VERSION ""

NS_ :

BS_:

BU_: AMP ETC GW ICM IVI NVS PDC TBOX VSP WCM

BO_ 1924 Diag_Resp_POT: 8 GW
 SG_ Diag_Resp_POT_Data : 0|64@1+ (1,0) [0|0] "N/A"  TBOX

BO_ 1925 Diag_Resp_DSCU: 8 GW
 SG_ Diag_Resp_DSCU_Data : 0|64@1+ (1,0) [0|0] "N/A"  TBOX

BO_ 1934 Diag_Resp_GW: 8 GW
 SG_ Diag_Resp_GW_Data : 0|64@1+ (1,0) [0|0] "N/A"  TBOX

BO_ 1945 Diag_Resp_SWM: 8 GW
 SG_ Diag_Resp_SWM_Data : 0|64@1+ (1,0) [0|0] "N/A"  TBOX

BO_ 1952 Diag_Resp_HCMR: 8 GW
 SG_ Diag_Resp_HCMR_Data : 0|64@1+ (1,0) [0|0] "N/A"  TBOX

BO_ 1953 Diag_Resp_HCML: 8 GW
 SG_ Diag_Resp_HCML_Data : 0|64@1+ (1,0) [0|0] "N/A"  TBOX

BO_ 1954 Diag_Resp_ESC: 8 GW
 SG_ Diag_Resp_ESC_Data : 0|64@1+ (1,0) [0|0] "N/A"  TBOX

BO_ 1956 Diag_Resp_AVM: 8 GW
 SG_ Diag_Resp_AVM_Data : 0|64@1+ (1,0) [0|0] "N/A"  TBOX

BO_ 1958 Diag_Resp_AC: 8 GW
 SG_ Diag_Resp_AC_Data : 0|64@1+ (1,0) [0|0] "N/A"  TBOX

BO_ 1959 Diag_Resp_ASC: 8 GW
 SG_ Diag_Resp_ASC_Data : 0|64@1+ (1,0) [0|0] "N/A"  TBOX

BO_ 1961 Diag_Resp_GSM: 8 GW
 SG_ Diag_Resp_GSM_Data : 0|64@1+ (1,0) [0|0] "N/A"  TBOX

BO_ 1962 Diag_Resp_MPC: 8 GW
 SG_ Diag_Resp_MPC_Data : 0|64@1+ (1,0) [0|0] "N/A"  TBOX

BO_ 1963 Diag_Resp_MRR_R1: 8 GW
 SG_ Diag_Resp_MRR_R1_Data : 0|64@1+ (1,0) [0|0] "N/A"  TBOX

BO_ 1964 Diag_Resp_MRR_R2: 8 GW
 SG_ Diag_Resp_MRR_R2_Data : 0|64@1+ (1,0) [0|0] "N/A"  TBOX

BO_ 1969 Diag_Resp_VCU: 8 GW
 SG_ Diag_Resp_VCU_Data : 0|64@1+ (1,0) [0|0] "N/A"  TBOX

BO_ 1970 Diag_Resp_MCUR0: 8 GW
 SG_ Diag_Resp_MCUR0_Data : 0|64@1+ (1,0) [0|0] "N/A"  TBOX

BO_ 1971 Diag_Resp_MCUF0: 8 GW
 SG_ Diag_Resp_MCUF0_Data : 0|64@1+ (1,0) [0|0] "N/A"  TBOX

BO_ 1972 Diag_Resp_BMS: 8 GW
 SG_ Diag_Resp_BMS_Data : 0|64@1+ (1,0) [0|0] "N/A"  TBOX

BO_ 1973 Diag_Resp_iBooster: 8 GW
 SG_ Diag_Resp_iB_Data : 0|64@1+ (1,0) [0|0] "N/A"  TBOX

BO_ 1975 Diag_Resp_OBCM: 8 GW
 SG_ Diag_Resp_OBCM_Data : 0|64@1+ (1,0) [0|0] "N/A"  TBOX

BO_ 1977 Diag_Resp_MRR: 8 GW
 SG_ Diag_Resp_MRR_Data : 0|64@1+ (1,0) [0|0] "N/A"  TBOX

BO_ 1979 Diag_Resp_BLE: 8 GW
 SG_ Diag_Resp_BLE_Data : 0|64@1+ (1,0) [0|0] "N/A"  TBOX

BO_ 1980 Diag_Resp_GCU: 8 GW
 SG_ Diag_Resp_GCU_Data : 0|64@1+ (1,0) [0|0] "N/A"  TBOX

BO_ 1987 Diag_Resp_APA: 8 GW
 SG_ Diag_Resp_APA_Data : 0|64@1+ (1,0) [0|0] "N/A"  TBOX

BO_ 1988 Diag_Resp_EPS: 8 GW
 SG_ Diag_Resp_EPS_Data : 0|64@1+ (1,0) [0|0] "N/A"  TBOX

BO_ 1994 Diag_Resp_HANDLE_LF: 8 GW
 SG_ Diag_Resp_HANDLE_LF_Data : 0|64@1+ (1,0) [0|0] "N/A"  TBOX

BO_ 1995 Diag_Resp_HANDLE_RF: 8 GW
 SG_ Diag_Resp_HANDLE_RF_Data : 0|64@1+ (1,0) [0|0] "N/A"  TBOX

BO_ 1996 Diag_Resp_HANDLE_LR: 8 GW
 SG_ Diag_Resp_HANDLE_LR_Data : 0|64@1+ (1,0) [0|0] "N/A"  TBOX

BO_ 1997 Diag_Resp_HANDLE_RR: 8 GW
 SG_ Diag_Resp_HANDLE_RR_Data : 0|64@1+ (1,0) [0|0] "N/A"  TBOX

BO_ 2015 Diag_FuncReq: 8 GW
 SG_ Diag_FuncReq_Data : 0|64@1+ (1,0) [0|0] "N/A"  AMP,ETC,ICM,IVI,NVS,PDC,TBOX,VSP,WCM

BO_ 2024 Diag_Resp_ECU: 8 GW
 SG_ Diag_Resp_ECU_Data : 0|64@1+ (1,0) [0|0] "N/A"  TBOX

BO_ 2026 OBD_Resp_BMS: 8 GW
 SG_ OBD_Resp_BMS_Data : 0|64@1+ (1,0) [0|0] "N/A"  TBOX

BO_ 2027 OBD_Resp_GCU: 8 GW
 SG_ OBD_Resp_GCU_Data : 0|64@1+ (1,0) [0|0] "N/A"  TBOX

BO_ 2028 OBD_Resp_OBCM: 8 GW
 SG_ OBD_Resp_OBCM_Data : 0|64@1+ (1,0) [0|0] "N/A"  TBOX

BO_ 2029 OBD_Resp_iBooster: 8 GW
 SG_ OBD_Resp_iBooster_Data : 0|64@1+ (1,0) [0|0] "N/A"  TBOX

BO_ 2030 OBD_Resp_ESC: 8 GW
 SG_ OBD_Resp_ESC_Data : 0|64@1+ (1,0) [0|0] "N/A"  TBOX

BO_ 2031 OBD_Resp_VCU: 8 GW
 SG_ OBD_Resp_VCU_Data : 0|64@1+ (1,0) [0|0] "N/A"  TBOX

BO_ 2041 Diag_Resp_ACU: 8 GW
 SG_ Diag_Resp_ACU_Data : 0|64@1+ (1,0) [0|0] "N/A"  TBOX

BO_ 937 ICM_state: 8 ICM
 SG_ icm_dvrSts : 0|3@1+ (1,0) [0|7] ""  GW,IVI,TBOX
 SG_ icm_dvrPhotoSts : 3|1@1+ (1,0) [0|1] ""  GW,IVI,TBOX
 SG_ icm_dvrSDcardSts : 4|3@1+ (1,0) [0|7] ""  GW,IVI
 SG_ icm_dvrPhotoOutput : 7|1@1+ (1,0) [0|1] ""  GW,IVI,TBOX
 SG_ icm_dvrExitReq : 8|2@1+ (1,0) [0|3] ""  GW,IVI
 SG_ icm_roaSts : 10|2@1+ (1,0) [0|3] ""  GW,IVI,TBOX
 SG_ icm_roaDisplayRes : 14|2@1+ (1,0) [0|3] ""  GW,IVI
 SG_ icm_roaPassengerL : 16|1@1+ (1,0) [0|1] ""  GW,IVI
 SG_ icm_roaPassengerM : 17|1@1+ (1,0) [0|1] ""  GW,IVI
 SG_ icm_roaPassengerR : 18|1@1+ (1,0) [0|1] ""  GW,IVI
 SG_ icm_roaPassengerAge : 19|2@1+ (1,0) [0|3] ""  GW,IVI
 SG_ icm_roaPassengerMood : 21|2@1+ (1,0) [0|3] ""  GW,IVI,TBOX
 SG_ icm_ivipressphto : 23|1@1+ (1,0) [0|1] ""  GW,IVI
 SG_ icm_dmsSts : 24|3@1+ (1,0) [0|7] ""  GW,IVI,TBOX
 SG_ icm_dmsCameraSts : 27|3@1+ (1,0) [0|7] ""  GW,IVI,TBOX
 SG_ icm_dmsWearySet : 30|1@1+ (1,0) [0|1] ""  GW,IVI
 SG_ icm_dmsWearyAssisSet : 31|1@1+ (1,0) [0|1] ""  GW,IVI
 SG_ icm_dmsWearyLeverSts : 32|3@1+ (1,0) [0|7] ""  GW,IVI,TBOX
 SG_ icm_dmsDrvBehaviorMon : 35|3@1+ (1,0) [0|7] ""  GW,IVI,TBOX
 SG_ icm_dmsDistractLeverSts : 38|2@1+ (1,0) [0|3] ""  GW,IVI,TBOX
 SG_ icm_dmsSenSetRsp : 40|1@1+ (1,0) [0|1] ""  GW,IVI,TBOX
 SG_ icm_roaRemind : 41|3@1+ (1,0) [0|7] ""  GW,IVI,TBOX
 SG_ icm_dmsDriverMood : 44|2@1+ (1,0) [0|3] ""  GW,IVI,TBOX
 SG_ icm_dmsDriver : 46|1@1+ (1,0) [0|1] ""  GW,IVI
 SG_ icm_dmsPassenger : 47|1@1+ (1,0) [0|1] ""  GW,IVI
 SG_ icm_dmsFaceID : 48|4@1+ (1,0) [0|15] ""  GW,IVI,TBOX
 SG_ icm_dmsGestureID : 52|4@1+ (1,0) [0|15] ""  GW,IVI,TBOX
 SG_ icm_dmsVideoCallSts : 56|3@1+ (1,0) [0|7] ""  GW,IVI,TBOX
 SG_ icm_roaITLLightReq : 59|2@1+ (1,0) [0|3] ""  GW
 SG_ icm_dvrVideoOutput : 61|1@1+ (1,0) [0|1] ""  GW,IVI,TBOX
 SG_ icm_roaCameraSts : 62|2@1+ (1,0) [0|3] ""  GW,IVI

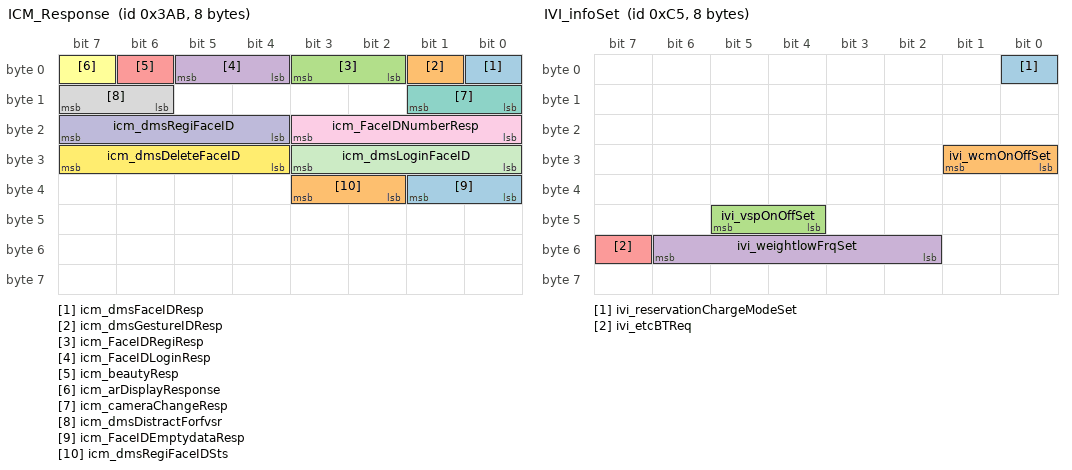
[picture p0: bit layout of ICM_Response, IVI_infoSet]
BO_ 939 ICM_Response: 8 ICM
 SG_ icm_dmsFaceIDResp : 0|1@1+ (1,0) [0|1] ""  IVI
 SG_ icm_dmsGestureIDResp : 1|1@1+ (1,0) [0|1] ""  IVI
 SG_ icm_FaceIDRegiResp : 2|2@1+ (1,0) [0|3] ""  IVI
 SG_ icm_FaceIDLoginResp : 4|2@1+ (1,0) [0|3] ""  IVI
 SG_ icm_beautyResp : 6|1@1+ (1,0) [0|1] ""  IVI
 SG_ icm_arDisplayResponse : 7|1@1+ (1,0) [0|1] ""  IVI
 SG_ icm_cameraChangeResp : 8|2@1+ (1,0) [0|3] ""  IVI
 SG_ icm_dmsDistractForfvsr : 14|2@1+ (1,0) [0|3] ""  GW
 SG_ icm_FaceIDNumberResp : 16|4@1+ (1,0) [0|15] ""  IVI
 SG_ icm_dmsRegiFaceID : 20|4@1+ (1,0) [0|15] ""  IVI
 SG_ icm_dmsLoginFaceID : 24|4@1+ (1,0) [0|15] ""  IVI
 SG_ icm_dmsDeleteFaceID : 28|4@1+ (1,0) [0|15] ""  IVI
 SG_ icm_FaceIDEmptydataResp : 32|2@1+ (1,0) [0|3] ""  IVI
 SG_ icm_dmsRegiFaceIDSts : 34|2@1+ (1,0) [0|3] ""  IVI

BO_ 1545 NM_ICM: 8 ICM
 SG_ ICM_RMR : 8|1@1+ (1,0) [0|1] ""  AMP,ETC,GW,IVI,TBOX
 SG_ ICM_AWB : 12|1@1+ (1,0) [0|1] ""  AMP,ETC,GW,IVI,TBOX

BO_ 1929 Diag_Resp_ICM: 8 ICM
 SG_ Diag_Resp_ICM_Data : 0|64@1+ (1,0) [0|0] "N/A"  GW,TBOX

BO_ 82 IC_engineOFF: 8 IVI
 SG_ ic_engOffTime : 0|10@1+ (1,0) [0|1000] "min"  GW
 SG_ ic_engOffTimeValid : 10|1@1+ (1,0) [0|1] ""  GW

BO_ 117 IVI_control: 8 IVI
 SG_ ivi_hoodUnlockCtrl : 0|2@1+ (1,0) [0|3] ""  GW
 SG_ ivi_RearWindowLockCtrl : 2|2@1+ (1,0) [0|3] ""  GW
 SG_ ivi_gloveBoxUnlockCtrl : 4|2@1+ (1,0) [0|3] ""  GW
 SG_ ivi_centralLockCtrl : 6|2@1+ (1,0) [0|3] ""  GW
 SG_ ivi_fuelPortCapOpenCtrl : 8|2@1+ (1,0) [0|3] ""  GW
 SG_ ivi_lowBeamOnOffCtrl : 10|2@1+ (1,0) [0|3] ""  GW
 SG_ ivi_v2vChrgOnOffSet : 12|2@1+ (1,0) [0|3] ""  GW
 SG_ ivi_posLampOnOffCtrl : 14|2@1+ (1,0) [0|3] ""  GW
 SG_ ivi_obcDschrgOnOffSet : 16|2@1+ (1,0) [0|3] ""  GW
 SG_ ivi_modememory : 18|2@1+ (1,0) [0|3] ""  GW
 SG_ ivi_rearFogLampOnOffCtrl : 20|2@1+ (1,0) [0|3] ""  GW
 SG_ ivi_ventilateSts : 22|2@1+ (1,0) [0|3] ""  GW
 SG_ ivi_chrgPortCapOpenCtrl : 24|2@1+ (1,0) [0|3] ""  GW
 SG_ ivi_sunroofGlassCmd : 26|3@1+ (1,0) [0|7] ""  GW
 SG_ ivi_NormalHvOffReq : 29|1@1+ (1,0) [0|1] ""  GW
 SG_ ivi_antiTheftAlarmFormSet : 30|2@1+ (1,0) [0|3] ""  GW
 SG_ ivi_tailgateCtrl : 32|2@1+ (1,0) [0|3] ""  GW
 SG_ ivi_MirrorSw : 34|2@1+ (1,0) [0|3] ""  GW
 SG_ ivi_rearDefrostCtrl : 36|2@1+ (1,0) [0|3] ""  GW
 SG_ IVI_SOCmodeSet : 38|2@1+ (1,0) [0|3] ""  GW
 SG_ ivi_MaxFuelConsumptionSW : 40|2@1+ (1,0) [0|3] ""  GW
 SG_ ivi_MaxFuelConsumptionModeSW : 42|2@1+ (1,0) [0|3] ""  GW
 SG_ ivi_v2vChrgOptCurntSet : 44|4@1+ (1,0) [0|15] "A"  GW
 SG_ ivi_BatteryCondition : 48|2@1+ (1,0) [0|3] ""  GW
 SG_ ivi_approachingUnlockCtrl : 50|2@1+ (1,0) [0|3] ""  GW
 SG_ ivi_awayLockCtrl : 52|2@1+ (1,0) [0|3] ""  GW
 SG_ ivi_WipperMaintenanceCtrl : 54|1@1+ (1,0) [0|1] ""  GW
 SG_ ivi_gunUnlockCtrlReq : 55|1@1+ (1,0) [0|1] ""  GW
 SG_ ivi_ExhibitionSet : 56|2@1+ (1,0) [0|3] ""  GW
 SG_ ivi_potOnOffSet : 58|2@1+ (1,0) [0|3] ""  GW
 SG_ ivi_frontWindshieldHeatingCtrl : 60|2@1+ (1,0) [0|3] ""  GW
 SG_ ivi_lowVoltPowerCtrl : 62|2@1+ (1,0) [0|3] ""  GW

BO_ 133 IVI_speechControl: 8 IVI
 SG_ ivi_pot_SpeechCtrlOnOffSts : 0|2@1+ (1,0) [0|3] ""  GW
 SG_ ivi_ChargPileAuthSts : 2|1@1+ (1,0) [0|1] ""  TBOX

BO_ 149 IVI_comfortSet: 8 IVI
 SG_ ivi_lockAutoCloseWinCtrl : 0|2@1+ (1,0) [0|3] ""  GW
 SG_ ivi_ambientLightOnOffSet : 2|2@1+ (1,0) [0|3] ""  GW
 SG_ ivi_sunroofRollshadeCtrlSelect : 4|2@1+ (1,0) [0|3] ""  GW
 SG_ ivi_ambientLightColorSet : 8|8@1+ (1,0) [0|255] ""  GW
 SG_ ivi_ambientLightLumiLvSet : 16|4@1+ (1,0) [0|15] ""  GW
 SG_ ivi_screenAutoLiftCtrl : 20|2@1+ (1,0) [0|3] ""  GW
 SG_ ivi_doorTopSW : 22|2@1+ (1,0) [0|3] ""  GW
 SG_ ivi_parkAutoCloseDRLCtrl : 24|2@1+ (1,0) [0|3] ""  GW
 SG_ ivi_followMeHomeSet : 26|3@1+ (1,0) [0|7] ""  GW
 SG_ ivi_WheelAlignmentCtrl : 29|1@1+ (1,0) [0|1] ""  GW
 SG_ ivi_WinLFCtrlRqst : 32|3@1+ (1,0) [0|7] ""  GW
 SG_ ivi_WinRFCtrlRqst : 35|3@1+ (1,0) [0|7] ""  GW
 SG_ ivi_WinLRCtrlRqst : 40|3@1+ (1,0) [0|7] ""  GW
 SG_ ivi_WinRRCtrlRqst : 43|3@1+ (1,0) [0|7] ""  GW
 SG_ IVI_DGSW : 46|2@1+ (1,0) [0|3] ""  GW
 SG_ IVI_DGPercentCtrl : 48|5@1+ (1,0) [0|31] ""  GW
 SG_ IVI_speedautolockonoffSet : 53|2@1+ (1,0) [0|3] ""  GW
 SG_ ivi_adbOnOffSet : 56|2@1+ (1,0) [0|3] ""  GW
 SG_ ivi_hcmHeightSet : 58|3@1+ (1,0) [0|7] ""  GW

BO_ 165 IVI_pwrSet: 8 IVI
 SG_ ivi_4wdModeSet : 2|2@1+ (1,0) [0|3] ""  GW
 SG_ ivi_ChargeCancel : 4|1@1+ (1,0) [0|1] ""  GW,TBOX
 SG_ ivi_RegenModeSet : 5|3@1+ (1,0) [0|7] ""  GW
 SG_ ivi_maxChargeCurrentSet : 8|6@1+ (1,5) [5|67] "A"  GW,TBOX
 SG_ ivi_TowModeSet : 14|2@1+ (1,0) [0|3] ""  GW
 SG_ ivi_maxChrgSocSet : 16|8@1+ (1,0) [0|100] "%"  GW,TBOX
 SG_ ivi_chargeFormSet : 24|2@1+ (1,0) [0|3] ""  GW,TBOX
 SG_ ivi_ChargeEnable : 26|1@1+ (1,0) [0|1] ""  GW,TBOX
 SG_ ivi_highwayModeRequest : 27|2@1+ (1,0) [0|3] ""  GW
 SG_ ivi_chargeSetValid : 30|1@1+ (1,0) [0|1] ""  GW,TBOX
 SG_ ivi_ChargeEndTimeHour : 32|4@1+ (1,0) [0|15] ""  GW,TBOX
 SG_ ivi_ChargeStartTimeHour : 36|4@1+ (1,0) [0|15] ""  GW,TBOX
 SG_ ivi_ChargeEndTimeHalfDay : 40|1@1+ (1,0) [0|1] ""  GW,TBOX
 SG_ ivi_ChargeStartTimeHalfDay : 41|1@1+ (1,0) [0|1] ""  GW,TBOX
 SG_ ivi_ChargeEndTimeMinute : 42|6@1+ (1,0) [0|59] ""  GW,TBOX
 SG_ ivi_ChargeStartTimeMinute : 48|6@1+ (1,0) [0|59] ""  GW,TBOX
 SG_ ivi_ResetCurrentTrip : 54|1@1+ (1,0) [0|1] ""  GW
 SG_ ivi_BCMEBSHvoffset : 56|2@1+ (1,0) [0|3] ""  GW
 SG_ ivi_ChargeEndTimeValid : 58|1@1+ (1,0) [0|1] ""  GW,TBOX
 SG_ ivi_ChargeStartTimeValid : 59|1@1+ (1,0) [0|1] ""  GW,TBOX
 SG_ ivi_driveModeSet : 61|3@1+ (1,0) [0|7] ""  GW

BO_ 197 IVI_infoSet: 8 IVI
 SG_ ivi_reservationChargeModeSet : 0|1@1+ (1,0) [0|1] ""  TBOX
 SG_ ivi_wcmOnOffSet : 24|2@1+ (1,0) [0|3] ""  WCM
 SG_ ivi_vspOnOffSet : 44|2@1+ (1,0) [0|3] ""  VSP
 SG_ ivi_weightlowFrqSet : 50|5@1+ (1,0) [0|31] ""  AMP
 SG_ ivi_etcBTReq : 55|1@1+ (1,0) [0|1] ""  ETC

BO_ 245 IVI_scuSet: 8 IVI
 SG_ ivi_autoEasyEntrySet : 0|2@1+ (1,0) [0|3] ""  GW
 SG_ ivi_drSeatHeatOnOffSet : 2|2@1+ (1,0) [0|3] ""  GW
 SG_ ivi_drSeatVentOnOffSet : 4|2@1+ (1,0) [0|3] ""  GW
 SG_ ivi_drSeatMassOnOffSet : 6|2@1+ (1,0) [0|3] ""  GW
 SG_ ivi_drSeatHeatLevelSet : 8|3@1+ (1,0) [0|7] ""  GW
 SG_ ivi_drSeatVentLevelSet : 11|3@1+ (1,0) [0|7] ""  GW
 SG_ ivi_passSeatHeatOnOffSet : 14|2@1+ (1,0) [0|3] ""  GW
 SG_ ivi_passSeatVentOnOffSet : 16|2@1+ (1,0) [0|3] ""  GW
 SG_ ivi_passSeatHeatLevelSet : 18|3@1+ (1,0) [0|7] ""  GW
 SG_ ivi_passSeatVentLevelSet : 21|3@1+ (1,0) [0|7] ""  GW
 SG_ ivi_passSeatMassOnOffSet : 24|2@1+ (1,0) [0|3] ""  GW
 SG_ ivi_drSeatMassLevelSet : 26|3@1+ (1,0) [0|7] ""  GW
 SG_ ivi_passSeatMassLevelSet : 29|3@1+ (1,0) [0|7] ""  GW
 SG_ ivi_MirrorAutoFoldUnfoldSet : 32|2@1+ (1,0) [0|3] ""  GW
 SG_ ivi_easyEntrySet : 34|2@1+ (1,0) [0|3] ""  GW
 SG_ ivi_dsmSetMemoryReq : 40|3@1+ (1,0) [0|7] ""  GW
 SG_ ivi_dsmGetMemoryReq : 43|3@1+ (1,0) [0|7] ""  GW
 SG_ ivi_rvMirrorAutoTurnDownSet : 46|2@1+ (1,0) [0|3] ""  GW
 SG_ ivi_DrMassgIntenSet : 48|2@1+ (1,0) [0|3] ""  GW
 SG_ ivi_PsgMassgIntenSet : 50|2@1+ (1,0) [0|3] ""  GW
 SG_ ivi_manualEasyOutSw : 52|2@1+ (1,0) [0|3] ""  GW
 SG_ ivi_potPositionStsSet : 54|4@1+ (1,0) [0|15] ""  GW
 SG_ ivi_welcomeOnOffSet : 58|4@1+ (1,0) [0|15] ""  GW
 SG_ ivi_welcomeSetEnable : 62|2@1+ (1,0) [0|3] ""  GW

BO_ 261 IVI_icmSet: 8 IVI
 SG_ ivi_dvrDisplayReq : 0|2@1+ (1,0) [0|3] ""  ICM
 SG_ ivi_dvrCoTouchMotion : 2|2@1+ (1,0) [0|3] ""  ICM
 SG_ ivi_dvrXCoordinate : 4|12@1+ (1,0) [0|1280] ""  ICM
 SG_ ivi_dvrYCoordinate : 16|10@1+ (1,0) [0|720] ""  ICM
 SG_ ivi_roaDisplayReq : 26|2@1+ (1,0) [0|3] ""  ICM
 SG_ ivi_ICMpressphtoresp : 28|2@1+ (1,0) [0|3] ""  ICM
 SG_ ivi_dmsWearyAssisSet : 30|2@1+ (1,0) [0|3] ""  ICM
 SG_ ivi_dmsCameraCtl : 32|2@1+ (1,0) [0|3] ""  ICM
 SG_ ivi_dmsWearySet : 34|2@1+ (1,0) [0|3] ""  ICM
 SG_ ivi_dmsSenSet : 36|2@1+ (1,0) [0|3] ""  ICM
 SG_ ivi_ICMBeautySet : 38|2@1+ (1,0) [0|3] ""  ICM
 SG_ ivi_cameraChange : 40|3@1+ (1,0) [0|7] ""  ICM
 SG_ ivi_videoCallSts : 44|3@1+ (1,0) [0|7] ""  ICM
 SG_ ivi_nvsDisplay : 51|2@1+ (1,0) [0|3] ""  NVS
 SG_ ivi_nvsOCRPress : 53|2@1+ (1,0) [0|3] ""  NVS
 SG_ ivi_ArdisplayReq : 55|2@1+ (1,0) [0|3] ""  ICM
 SG_ ivi_dvrPhotoReceive : 57|1@1+ (1,0) [0|1] ""  ICM
 SG_ ivi_dvrVideoReceive : 58|1@1+ (1,0) [0|1] ""  ICM
 SG_ ivi_roaCameraCtl : 59|1@1+ (1,0) [0|1] ""  ICM
 SG_ ivi_tspUploadSts : 60|2@1+ (1,0) [0|3] ""  ICM,TBOX

BO_ 270 IVI_AVMSet: 8 IVI
 SG_ ivi_AVMTrigByTurnningSts : 0|1@1+ (1,0) [0|1] ""  GW
 SG_ ivi_AVMViewModeSw : 1|1@1+ (1,0) [0|1] ""  GW
 SG_ ivi_modeSw : 2|1@1+ (1,0) [0|1] ""  GW
 SG_ ivi_viewSw_Reserved : 3|2@1+ (1,0) [0|1] ""  GW
 SG_ ivi_screenCoordX : 5|11@1+ (1,0) [0|2047] ""  GW
 SG_ ivi_screenCoordY : 16|11@1+ (1,0) [0|2047] ""  GW
 SG_ ivi_avm_monVideoReceive : 28|1@1+ (1,0) [0|1] ""  GW
 SG_ ivi_MODSw : 29|1@1+ (1,0) [0|1] ""  GW
 SG_ ivi_AVMTrajectorySW : 30|1@1+ (1,0) [0|1] ""  GW
 SG_ ivi_AVMAutoswitchingSW : 31|1@1+ (1,0) [0|1] ""  GW
 SG_ ivi_AVM_transparentSW : 32|1@1+ (1,0) [0|1] ""  GW
 SG_ ivi_View_select : 33|5@1+ (1,0) [0|31] ""  GW
 SG_ IVI_Voice_AVMOnOffReq : 38|2@1+ (1,0) [0|3] ""  GW
 SG_ ivi_touchScreenCtrl : 40|4@1+ (1,0) [0|15] ""  GW
 SG_ ivi_naviSts : 44|2@1+ (1,0) [0|3] ""  GW
 SG_ IVI_Voice_APAOnOffReq : 46|2@1+ (1,0) [0|3] ""  GW
 SG_ IVI_Voice_CarbodyTransparentReq : 48|2@1+ (1,0) [0|3] ""  GW

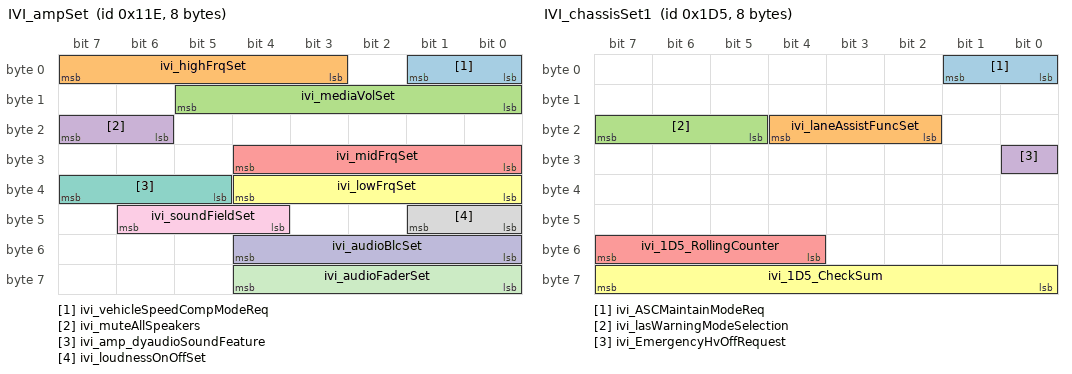
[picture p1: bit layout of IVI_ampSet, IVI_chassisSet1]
BO_ 286 IVI_ampSet: 8 IVI
 SG_ ivi_vehicleSpeedCompModeReq : 0|2@1+ (1,0) [0|3] ""  AMP
 SG_ ivi_highFrqSet : 3|5@1+ (1,0) [0|31] ""  AMP
 SG_ ivi_mediaVolSet : 8|6@1+ (1,0) [0|63] ""  AMP
 SG_ ivi_muteAllSpeakers : 22|2@1+ (1,0) [0|3] ""  AMP
 SG_ ivi_midFrqSet : 24|5@1+ (1,0) [0|31] ""  AMP
 SG_ ivi_lowFrqSet : 32|5@1+ (1,0) [0|31] ""  AMP
 SG_ ivi_amp_dyaudioSoundFeature : 37|3@1+ (1,0) [0|7] ""  AMP
 SG_ ivi_loudnessOnOffSet : 40|2@1+ (1,0) [0|3] ""  AMP
 SG_ ivi_soundFieldSet : 44|3@1+ (1,0) [0|3] ""  AMP
 SG_ ivi_audioBlcSet : 48|5@1+ (1,0) [0|31] ""  AMP
 SG_ ivi_audioFaderSet : 56|5@1+ (1,0) [0|31] ""  AMP

BO_ 446 IVI_chassisSet: 8 IVI
 SG_ ivi_epsModeSet : 0|2@1+ (1,0) [0|3] ""  GW
 SG_ ivi_escOffSw : 2|2@1+ (1,0) [0|3] ""  GW
 SG_ ivi_hdcOnOffSet : 4|2@1+ (1,0) [0|3] ""  GW
 SG_ ivi_aebOnOffSet : 6|2@1+ (1,0) [0|3] ""  GW
 SG_ ivi_iBModeSet : 8|2@1+ (1,0) [0|3] ""  GW
 SG_ ivi_lksSensitivitySet : 10|2@1+ (1,0) [0|3] ""  GW
 SG_ ivi_lcaBsdOnOffSet : 12|2@1+ (1,0) [0|3] ""  GW
 SG_ ivi_rctaOnOffSet : 14|2@1+ (1,0) [0|3] ""  GW
 SG_ ivi_dowOnOffSet : 16|2@1+ (1,0) [0|3] ""  GW
 SG_ ivi_startRevSOCSet : 18|6@1+ (1,19) [19|80] "%"  GW
 SG_ ivi_speedLimitWarningMode : 24|2@1+ (1,0) [0|3] ""  GW
 SG_ ivi_ISAOnOffSet : 26|2@1+ (1,0) [0|3] ""  GW
 SG_ ivi_currentRoadType : 28|4@1+ (1,0) [0|15] ""  GW
 SG_ ivi_countryCodeSet : 32|8@1+ (1,0) [0|255] ""  GW
 SG_ ivi_FrtVehStrReminderSw : 40|2@1+ (1,0) [0|3] ""  GW
 SG_ ivi_speedLimitUnitSet : 48|2@1+ (1,0) [0|3] ""  GW
 SG_ ivi_speedLimitStsSet : 50|2@1+ (1,0) [0|3] ""  GW
 SG_ ivi_propModeSet : 52|2@1+ (1,0) [0|3] ""  GW
 SG_ ivi_pcwOnOffSet : 54|2@1+ (1,0) [0|3] ""  GW
 SG_ ivi_torqueDistModeSet : 56|2@1+ (1,0) [0|3] ""  GW
 SG_ ivi_rcwOnOffSet : 58|2@1+ (1,0) [0|3] ""  GW
 SG_ ivi_trailerModeOnOffSet : 60|2@1+ (1,0) [0|3] ""  GW
 SG_ ivi_esc_epbButtonRelease : 62|1@1+ (1,0) [0|1] ""  GW

BO_ 469 IVI_chassisSet1: 8 IVI
 SG_ ivi_ASCMaintainModeReq : 0|2@1+ (1,0) [0|3] ""  GW
 SG_ ivi_laneAssistFuncSet : 18|3@1+ (1,0) [0|7] ""  GW
 SG_ ivi_lasWarningModeSelection : 21|3@1+ (1,0) [0|7] ""  GW
 SG_ ivi_EmergencyHvOffRequest : 24|1@1+ (1,0) [0|1] ""  GW
 SG_ ivi_1D5_RollingCounter : 52|4@1+ (1,0) [0|15] ""  GW
 SG_ ivi_1D5_CheckSum : 56|8@1+ (1,0) [0|255] ""  GW

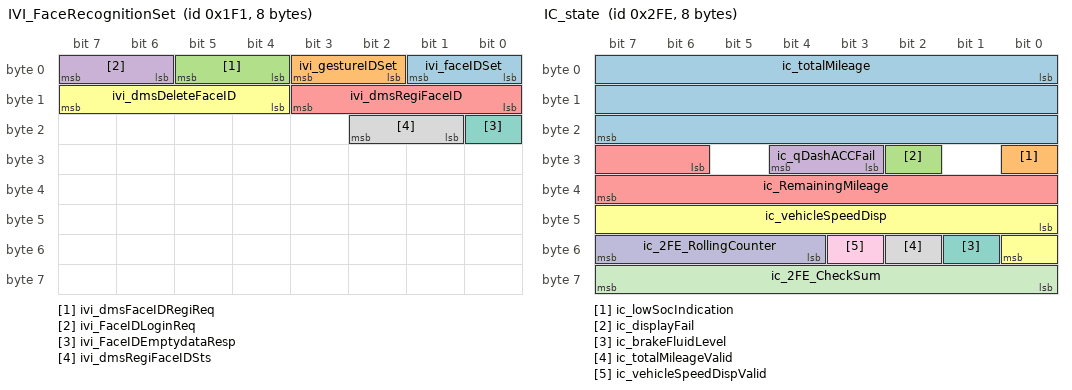
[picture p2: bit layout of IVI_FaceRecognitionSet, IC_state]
BO_ 497 IVI_FaceRecognitionSet: 8 IVI
 SG_ ivi_faceIDSet : 0|2@1+ (1,0) [0|3] ""  ICM
 SG_ ivi_gestureIDSet : 2|2@1+ (1,0) [0|3] ""  ICM
 SG_ ivi_dmsFaceIDRegiReq : 4|2@1+ (1,0) [0|3] ""  ICM
 SG_ ivi_FaceIDLoginReq : 6|2@1+ (1,0) [0|3] ""  ICM
 SG_ ivi_dmsRegiFaceID : 8|4@1+ (1,0) [0|15] ""  ICM
 SG_ ivi_dmsDeleteFaceID : 12|4@1+ (1,0) [0|15] ""  ICM
 SG_ ivi_FaceIDEmptydataResp : 16|1@1+ (1,0) [0|1] ""  ICM
 SG_ ivi_dmsRegiFaceIDSts : 17|2@1+ (1,0) [0|3] ""  ICM

BO_ 766 IC_state: 8 IVI
 SG_ ic_totalMileage : 0|24@1+ (0.1,0) [0|1677721.4] "km"  GW,TBOX
 SG_ ic_lowSocIndication : 24|1@1+ (1,0) [0|1] ""  GW
 SG_ ic_displayFail : 26|1@1+ (1,0) [0|1] ""  GW
 SG_ ic_qDashACCFail : 27|2@1+ (1,0) [0|3] ""  GW
 SG_ ic_RemainingMileage : 30|10@1+ (1,0) [0|1022] "km"  GW,TBOX
 SG_ ic_vehicleSpeedDisp : 40|9@1+ (1,0) [0|280] "KPH"  GW,ICM
 SG_ ic_brakeFluidLevel : 49|1@1+ (1,0) [0|1] ""  GW
 SG_ ic_totalMileageValid : 50|1@1+ (1,0) [0|1] ""  GW
 SG_ ic_vehicleSpeedDispValid : 51|1@1+ (1,0) [0|1] ""  GW
 SG_ ic_2FE_RollingCounter : 52|4@1+ (1,0) [0|15] ""  GW
 SG_ ic_2FE_CheckSum : 56|8@1+ (1,0) [0|255] ""  GW

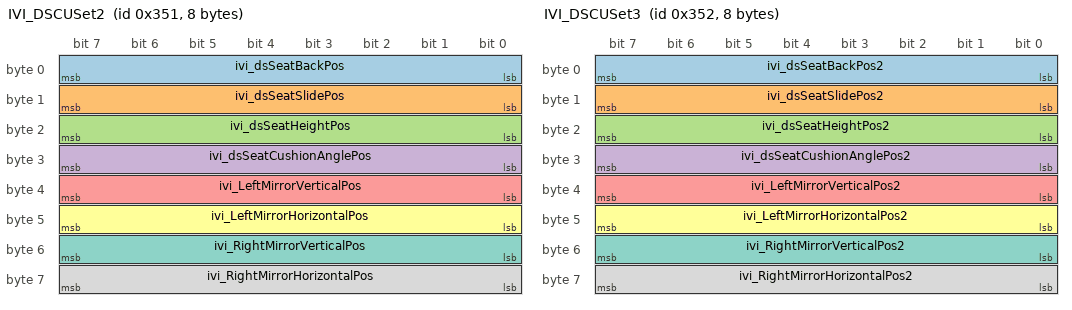
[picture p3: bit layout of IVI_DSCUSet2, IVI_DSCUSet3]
BO_ 849 IVI_DSCUSet2: 8 IVI
 SG_ ivi_dsSeatBackPos : 0|8@1+ (1,0) [0|100] "%"  GW
 SG_ ivi_dsSeatSlidePos : 8|8@1+ (1,0) [0|100] "%"  GW
 SG_ ivi_dsSeatHeightPos : 16|8@1+ (1,0) [0|100] "%"  GW
 SG_ ivi_dsSeatCushionAnglePos : 24|8@1+ (1,0) [0|100] "%"  GW
 SG_ ivi_LeftMirrorVerticalPos : 32|8@1+ (1,0) [0|100] "%"  GW
 SG_ ivi_LeftMirrorHorizontalPos : 40|8@1+ (1,0) [0|100] "%"  GW
 SG_ ivi_RightMirrorVerticalPos : 48|8@1+ (1,0) [0|100] "%"  GW
 SG_ ivi_RightMirrorHorizontalPos : 56|8@1+ (1,0) [0|100] "%"  GW

BO_ 850 IVI_DSCUSet3: 8 IVI
 SG_ ivi_dsSeatBackPos2 : 0|8@1+ (1,0) [0|100] "%"  GW
 SG_ ivi_dsSeatSlidePos2 : 8|8@1+ (1,0) [0|100] "%"  GW
 SG_ ivi_dsSeatHeightPos2 : 16|8@1+ (1,0) [0|100] "%"  GW
 SG_ ivi_dsSeatCushionAnglePos2 : 24|8@1+ (1,0) [0|100] "%"  GW
 SG_ ivi_LeftMirrorVerticalPos2 : 32|8@1+ (1,0) [0|100] "%"  GW
 SG_ ivi_LeftMirrorHorizontalPos2 : 40|8@1+ (1,0) [0|100] "%"  GW
 SG_ ivi_RightMirrorVerticalPos2 : 48|8@1+ (1,0) [0|100] "%"  GW
 SG_ ivi_RightMirrorHorizontalPos2 : 56|8@1+ (1,0) [0|100] "%"  GW

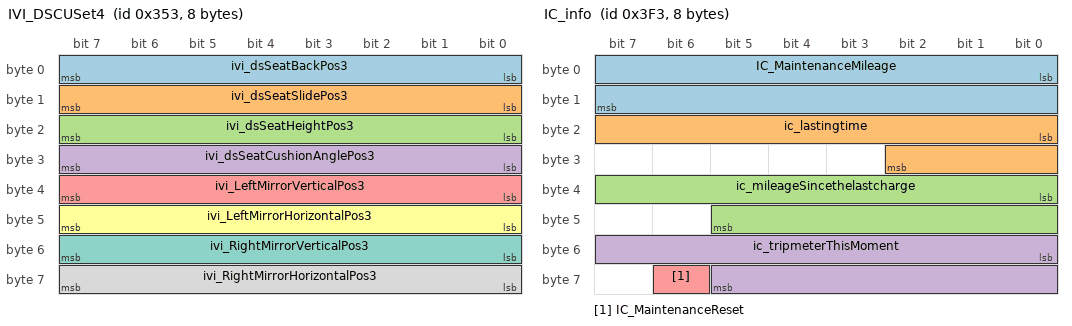
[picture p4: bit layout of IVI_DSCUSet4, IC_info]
BO_ 851 IVI_DSCUSet4: 8 IVI
 SG_ ivi_dsSeatBackPos3 : 0|8@1+ (1,0) [0|100] "%"  GW
 SG_ ivi_dsSeatSlidePos3 : 8|8@1+ (1,0) [0|100] "%"  GW
 SG_ ivi_dsSeatHeightPos3 : 16|8@1+ (1,0) [0|100] "%"  GW
 SG_ ivi_dsSeatCushionAnglePos3 : 24|8@1+ (1,0) [0|100] "%"  GW
 SG_ ivi_LeftMirrorVerticalPos3 : 32|8@1+ (1,0) [0|100] "%"  GW
 SG_ ivi_LeftMirrorHorizontalPos3 : 40|8@1+ (1,0) [0|100] "%"  GW
 SG_ ivi_RightMirrorVerticalPos3 : 48|8@1+ (1,0) [0|100] "%"  GW
 SG_ ivi_RightMirrorHorizontalPos3 : 56|8@1+ (1,0) [0|100] "%"  GW

BO_ 949 IVI_set: 8 IVI
 SG_ ivi_hvacOnOffReq : 0|1@1+ (1,0) [0|1] ""  GW
 SG_ ivi_hvacAutoModeReq : 8|1@1+ (1,0) [0|1] ""  GW
 SG_ ivi_hvacRecircModeReq : 9|1@1+ (1,0) [0|1] ""  GW
 SG_ ivi_hvacModeReq : 16|3@1+ (1,0) [0|7] ""  GW
 SG_ ivi_driverTempCSet : 19|5@1+ (0.5,15.5) [15.5|30.5] "degreeC"  GW
 SG_ ivi_passengerTempCSet : 27|5@1+ (0.5,15.5) [15.5|30.5] "degreeC"  GW
 SG_ ivi_hvacDualMode : 32|1@1+ (1,0) [0|1] ""  GW
 SG_ ivi_acReq : 34|1@1+ (1,0) [0|1] ""  GW
 SG_ ivi_pm25StsReq : 35|1@1+ (1,0) [0|1] ""  GW
 SG_ ivi_acWorkModeSet : 36|2@1+ (1,0) [0|3] ""  GW
 SG_ ivi_acDiagReq : 39|1@1+ (1,0) [0|1] ""  GW
 SG_ IVI_Backlightadjust : 40|4@1+ (1,0) [0|10] ""  GW
 SG_ IVI_FreshAirModeSet : 44|1@1+ (1,0) [0|1] ""  GW
 SG_ IVI_VentilationCoolSet : 45|1@1+ (1,0) [0|1] ""  GW
 SG_ ivi_frontDefrostCtrl : 46|1@1+ (1,0) [0|1] ""  GW
 SG_ ivi_languageSet : 48|2@1+ (1,0) [0|3] ""  GW
 SG_ ivi_unitSet : 50|2@1+ (1,0) [0|3] ""  GW
 SG_ ivi_hvacBlowLvReq : 52|4@1+ (1,0) [0|15] ""  GW
 SG_ IVI_Sunroof_HorizontalControl : 56|7@1+ (1,0) [0|100] "%"  GW

BO_ 1011 IC_info: 8 IVI
 SG_ IC_MaintenanceMileage : 0|16@1+ (1,0) [0|50000] "km"  GW,TBOX
 SG_ ic_lastingtime : 16|11@1+ (1,0) [0|1440] "min"  GW,ICM,TBOX
 SG_ ic_mileageSincethelastcharge : 32|14@1+ (0.1,0) [0|999.9] "km"  GW
 SG_ ic_tripmeterThisMoment : 48|14@1+ (0.1,0) [0|999.9] "km"  GW,TBOX
 SG_ IC_MaintenanceReset : 62|1@1+ (1,0) [0|1] ""  GW,TBOX

BO_ 1248 IC_info1: 8 IVI
 SG_ ic_totalMileageRev : 0|24@1+ (0.1,0) [0|1677721.4] "km"  TBOX

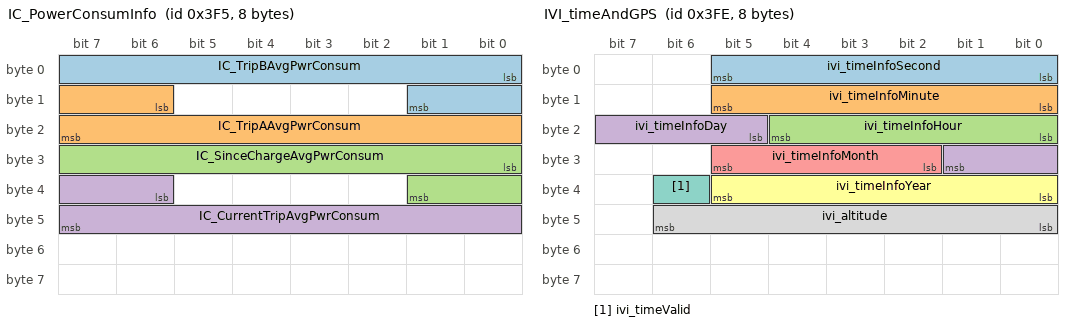
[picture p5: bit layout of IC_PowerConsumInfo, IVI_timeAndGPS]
BO_ 1013 IC_PowerConsumInfo: 8 IVI
 SG_ IC_TripBAvgPwrConsum : 0|10@1+ (0.1,-19.9) [-19.9|40] "kWh/100km"  TBOX
 SG_ IC_TripAAvgPwrConsum : 14|10@1+ (0.1,-19.9) [-19.9|40] "kWh/100km"  TBOX
 SG_ IC_SinceChargeAvgPwrConsum : 24|10@1+ (0.1,-19.9) [-19.9|40] "kWh/100km"  TBOX
 SG_ IC_CurrentTripAvgPwrConsum : 38|10@1+ (0.1,-19.9) [-19.9|40] "kWh/100km"  TBOX

BO_ 1022 IVI_timeAndGPS: 8 IVI
 SG_ ivi_timeInfoSecond : 0|6@1+ (1,0) [0|59] ""  GW,ICM,NVS
 SG_ ivi_timeInfoMinute : 8|6@1+ (1,0) [0|59] ""  GW,ICM,NVS
 SG_ ivi_timeInfoHour : 16|5@1+ (1,0) [0|23] ""  GW,ICM,NVS
 SG_ ivi_timeInfoDay : 21|5@1+ (1,0) [1|31] ""  GW,ICM,NVS
 SG_ ivi_timeInfoMonth : 26|4@1+ (1,0) [1|12] ""  GW,ICM,NVS
 SG_ ivi_timeInfoYear : 32|6@1+ (1,2000) [2000|2059] ""  GW,ICM,NVS
 SG_ ivi_timeValid : 38|1@1+ (1,0) [0|1] ""  GW,ICM,NVS
 SG_ ivi_altitude : 40|7@1+ (100,-100) [-100|8500] "degree"  GW

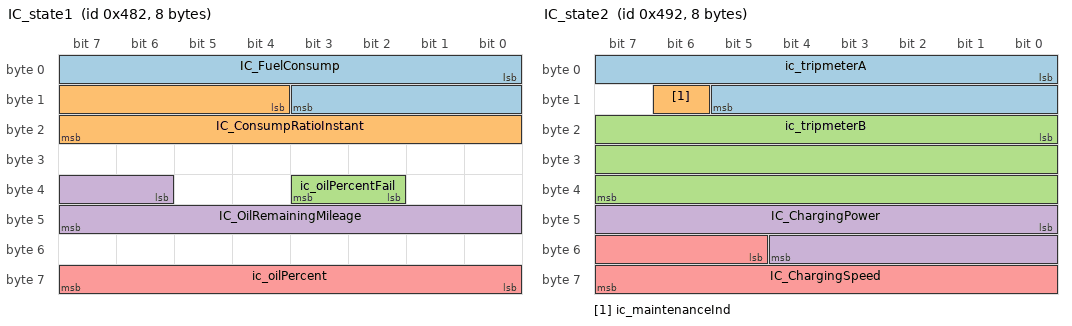
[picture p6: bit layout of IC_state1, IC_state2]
BO_ 1154 IC_state1: 8 IVI
 SG_ IC_FuelConsump : 0|12@1+ (0.1,0) [0|99.9] "L/100Km"  TBOX
 SG_ IC_ConsumpRatioInstant : 12|12@1+ (0.1,-40) [-40|99.9] "kWh/100km"  TBOX
 SG_ ic_oilPercentFail : 34|2@1+ (1,0) [0|3] ""  GW,TBOX
 SG_ IC_OilRemainingMileage : 38|10@1+ (1,0) [0|999] "km"  TBOX
 SG_ ic_oilPercent : 56|8@1+ (1,0) [0|100] "%"  GW,TBOX

BO_ 1170 IC_state2: 8 IVI
 SG_ ic_tripmeterA : 0|14@1+ (0.1,0) [0|1000] "km"  GW
 SG_ ic_maintenanceInd : 14|1@1+ (1,0) [0|1] ""  GW
 SG_ ic_tripmeterB : 16|24@1+ (0.1,0) [0|99999.9] "km"  GW
 SG_ IC_ChargingPower : 40|13@1+ (0.1,0) [0|500] "kW"  GW,TBOX
 SG_ IC_ChargingSpeed : 53|11@1+ (1,0) [0|2000] "km/h"  GW,TBOX

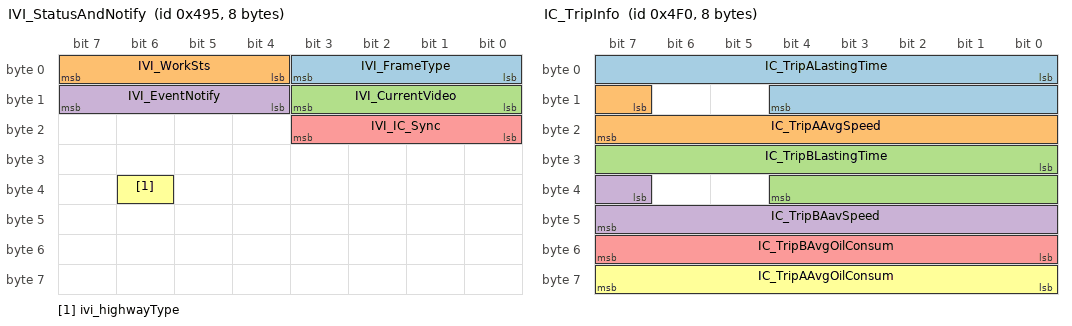
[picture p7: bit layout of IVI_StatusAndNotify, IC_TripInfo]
BO_ 1173 IVI_StatusAndNotify: 8 IVI
 SG_ IVI_FrameType : 0|4@1+ (1,0) [0|15] ""  GW
 SG_ IVI_WorkSts : 4|4@1+ (1,0) [0|15] ""  GW
 SG_ IVI_CurrentVideo : 8|4@1+ (1,0) [0|15] ""  GW
 SG_ IVI_EventNotify : 12|4@1+ (1,0) [0|15] ""  GW
 SG_ IVI_IC_Sync : 16|4@1+ (1,0) [0|15] ""  GW
 SG_ ivi_highwayType : 38|1@1+ (1,0) [0|1] ""  GW

BO_ 1264 IC_TripInfo: 8 IVI
 SG_ IC_TripALastingTime : 0|13@1+ (1,0) [0|5999] "min" Vector__XXX
 SG_ IC_TripAAvgSpeed : 15|9@1+ (1,0) [0|240] "km/h" Vector__XXX
 SG_ IC_TripBLastingTime : 24|13@1+ (1,0) [0|5999] "min" Vector__XXX
 SG_ IC_TripBAavSpeed : 39|9@1+ (1,0) [0|240] "km/h" Vector__XXX
 SG_ IC_TripBAvgOilConsum : 48|8@1+ (0.1,0) [0|19.9] "L/100Km" Vector__XXX
 SG_ IC_TripAAvgOilConsum : 56|8@1+ (0.1,0) [0|19.9] "L/100Km" Vector__XXX

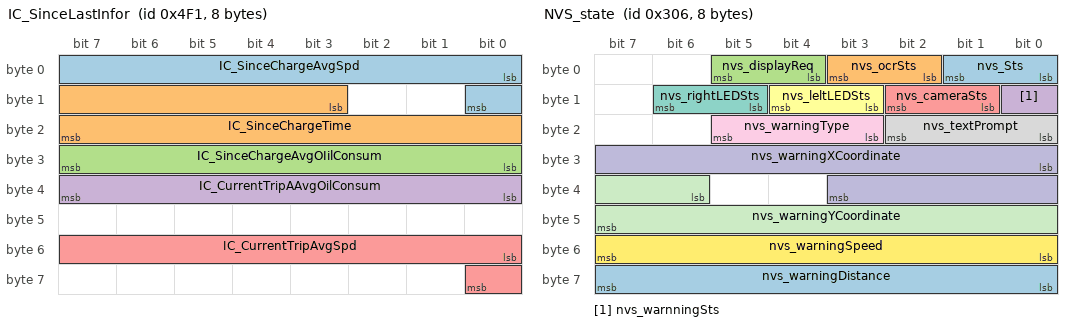
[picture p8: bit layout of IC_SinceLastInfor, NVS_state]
BO_ 1265 IC_SinceLastInfor: 8 IVI
 SG_ IC_SinceChargeAvgSpd : 0|9@1+ (1,0) [0|240] "km/h" Vector__XXX
 SG_ IC_SinceChargeTime : 11|13@1+ (1,0) [0|5999] "min" Vector__XXX
 SG_ IC_SinceChargeAvgOIilConsum : 24|8@1+ (0.1,0) [0|19.9] "L/100Km" Vector__XXX
 SG_ IC_CurrentTripAAvgOilConsum : 32|8@1+ (0.1,0) [0|19.9] "L/100Km"  TBOX
 SG_ IC_CurrentTripAvgSpd : 48|9@1+ (1,0) [0|240] "km/h"  TBOX

BO_ 1573 NM_IVI: 8 IVI
 SG_ IVI_RMR : 8|1@1+ (1,0) [0|1] ""  AMP,ETC,GW,ICM,TBOX
 SG_ IVI_AWB : 12|1@1+ (1,0) [0|1] ""  AMP,ETC,GW,ICM,TBOX

BO_ 1957 Diag_Resp_IVI: 8 IVI
 SG_ Diag_Resp_IVI_Data : 0|64@1+ (1,0) [0|0] "N/A"  GW,WCM

BO_ 774 NVS_state: 8 NVS
 SG_ nvs_Sts : 0|2@1+ (1,0) [0|3] ""  IVI
 SG_ nvs_ocrSts : 2|2@1+ (1,0) [0|3] ""  IVI
 SG_ nvs_displayReq : 4|2@1+ (1,0) [0|3] ""  IVI
 SG_ nvs_warnningSts : 8|1@1+ (1,0) [0|1] ""  IVI
 SG_ nvs_cameraSts : 9|2@1+ (1,0) [0|3] ""  IVI
 SG_ nvs_leltLEDSts : 11|2@1+ (1,0) [0|3] ""  IVI
 SG_ nvs_rightLEDSts : 13|2@1+ (1,0) [0|3] ""  IVI
 SG_ nvs_textPrompt : 16|3@1+ (1,0) [0|7] ""  IVI
 SG_ nvs_warningType : 19|3@1+ (1,0) [0|7] ""  IVI
 SG_ nvs_warningXCoordinate : 24|12@1+ (1,0) [0|1920] ""  IVI,TBOX
 SG_ nvs_warningYCoordinate : 38|10@1+ (1,0) [0|720] ""  IVI,TBOX
 SG_ nvs_warningSpeed : 48|8@1+ (1,0) [0|250] "km/h"  IVI
 SG_ nvs_warningDistance : 56|8@1+ (1,0) [0|250] "m"  IVI

BO_ 1978 Diag_Resp_NVS: 8 NVS
 SG_ Diag_Resp_NVS_Data : 0|64@1+ (1,0) [0|0] "N/A"  GW,TBOX

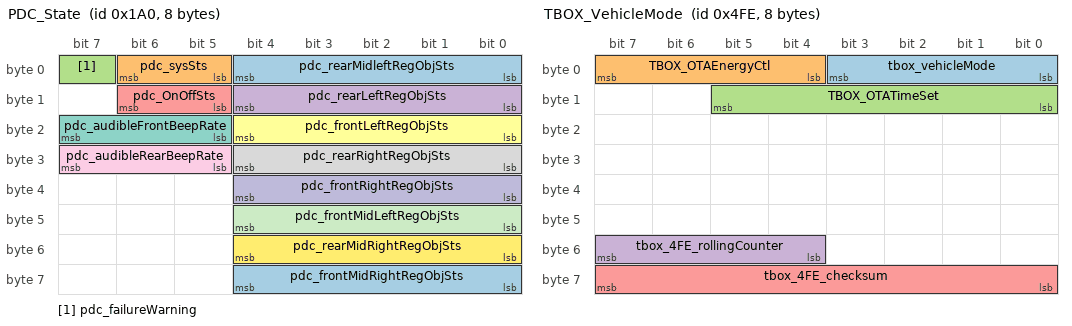
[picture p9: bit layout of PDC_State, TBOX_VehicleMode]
BO_ 416 PDC_State: 8 PDC
 SG_ pdc_rearMidleftRegObjSts : 0|5@1+ (1,0) [0|31] ""  GW,IVI
 SG_ pdc_sysSts : 5|2@1+ (1,0) [0|3] ""  GW,IVI
 SG_ pdc_failureWarning : 7|1@1+ (1,0) [0|1] ""  GW,IVI
 SG_ pdc_rearLeftRegObjSts : 8|5@1+ (1,0) [0|31] ""  GW,IVI
 SG_ pdc_OnOffSts : 13|2@1+ (1,0) [0|3] ""  GW,IVI
 SG_ pdc_frontLeftRegObjSts : 16|5@1+ (1,0) [0|31] ""  GW,IVI
 SG_ pdc_audibleFrontBeepRate : 21|3@1+ (1,0) [0|7] ""  GW,IVI
 SG_ pdc_rearRightRegObjSts : 24|5@1+ (1,0) [0|31] ""  GW,IVI
 SG_ pdc_audibleRearBeepRate : 29|3@1+ (1,0) [0|7] ""  GW,IVI
 SG_ pdc_frontRightRegObjSts : 32|5@1+ (1,0) [0|31] ""  GW,IVI
 SG_ pdc_frontMidLeftRegObjSts : 40|5@1+ (1,0) [0|31] ""  GW,IVI
 SG_ pdc_rearMidRightRegObjSts : 48|5@1+ (1,0) [0|31] ""  GW,IVI
 SG_ pdc_frontMidRightRegObjSts : 56|5@1+ (1,0) [0|31] ""  GW,IVI

BO_ 1943 Diag_Resp_PDC: 8 PDC
 SG_ Diag_Resp_PDC_Data : 0|64@1+ (1,0) [0|0] "N/A"  GW,TBOX

BO_ 72 TBOX_BCM_response: 8 TBOX
 SG_ Tbox_AuthResponeStatus : 8|8@1+ (1,0) [0|255] ""  GW
 SG_ Tbox_AuthKeyData : 16|48@1+ (1,0) [0|65535] ""  GW

BO_ 88 TBOX_remoteCmd: 8 TBOX
 SG_ tbox_remoteLockCtrlReq : 3|2@1+ (1,0) [0|3] ""  GW
 SG_ tbox_remoteCarSearchReq : 6|2@1+ (1,0) [0|3] ""  GW
 SG_ tbox_remoteTailgateCtrlReq : 8|2@1+ (1,0) [0|3] ""  GW
 SG_ tbox_sunroofGlassCmd : 10|3@1+ (1,0) [0|7] ""  GW
 SG_ tbox_remoteForbiddenOn : 13|2@1+ (1,0) [0|3] ""  GW
 SG_ tbox_HornReq : 15|2@1+ (1,0) [0|3] ""  GW
 SG_ tbox_remotePowerCtrlReq : 17|2@1+ (1,0) [0|3] ""  GW
 SG_ tbox_remoteDrSeatHeatReq : 19|3@1+ (1,0) [0|7] ""  GW
 SG_ tbox_remotePassSeatHeatReq : 22|3@1+ (1,0) [0|7] ""  GW
 SG_ tbox_HazardLightReq : 25|2@1+ (1,0) [0|3] ""  GW
 SG_ tbox_remoteACOnOffReq : 27|2@1+ (1,0) [0|3] ""  GW
 SG_ tbox_remoteInfoCollectionReq : 29|2@1+ (1,0) [0|3] ""  GW
 SG_ tbox_oneTouchCoolSet : 32|2@1+ (1,0) [0|3] ""  GW
 SG_ tbox_oneTouchHeatSet : 34|2@1+ (1,0) [0|3] ""  GW
 SG_ tbox_remoteWinLFCtrlRqst : 48|2@1+ (1,0) [0|3] ""  GW
 SG_ tbox_remoteWinRFCtrlRqst : 50|2@1+ (1,0) [0|3] ""  GW
 SG_ tbox_remoteWinLRCtrlRqst : 52|2@1+ (1,0) [0|3] ""  GW
 SG_ tbox_remoteWinRRCtrlRqst : 54|2@1+ (1,0) [0|3] ""  GW
 SG_ tbox_lowBeamOnOffCtrl : 56|2@1+ (1,0) [0|3] ""  GW

BO_ 126 TBOX_chargeSet: 8 TBOX
 SG_ tbox_reservationChargeMode : 0|1@1+ (1,0) [0|1] ""  GW,IVI
 SG_ tbox_SysErSt : 1|2@1+ (1,0) [0|3] ""  GW,IVI
 SG_ tbox_chargeSetValid_Reserved : 7|1@1+ (1,0) [0|1] ""  GW
 SG_ tbox_MaxChargeCurrentSet : 8|6@1+ (1,5) [5|67] "A"  GW,IVI
 SG_ tbox_ChargeFormSet : 14|2@1+ (1,0) [0|3] ""  GW,IVI
 SG_ tbox_ChargeEndTimeHalfDay : 16|1@1+ (1,0) [0|1] ""  GW,IVI
 SG_ tbox_ChargeEndTimeHour : 17|4@1+ (1,0) [0|15] ""  GW,IVI
 SG_ tbox_remoteVehicleForbiddenStart : 21|2@1+ (1,0) [0|3] ""  GW
 SG_ tbox_ChargeEndTimeMinute : 24|6@1+ (1,0) [0|59] ""  GW,IVI
 SG_ tbox_ChargeCancel : 30|1@1+ (1,0) [0|1] ""  GW
 SG_ tbox_ChargeEnable : 31|1@1+ (1,0) [0|1] ""  GW
 SG_ tbox_ChargeStartTimeHalfDay : 32|1@1+ (1,0) [0|1] ""  GW,IVI
 SG_ tbox_ChargeStartTimeHour : 33|4@1+ (1,0) [0|15] ""  GW,IVI
 SG_ tbox_EmergencyHvOffReq : 37|1@1+ (1,0) [0|1] ""  GW
 SG_ tbox_ChargeStartTimeMinute : 40|6@1+ (1,0) [0|59] ""  GW,IVI
 SG_ tbox_BatteryCondition_Reserved : 46|1@1+ (1,0) [0|1] ""  GW
 SG_ tbox_MaxChargeSOCSet : 48|7@1+ (1,0) [0|100] "%"  GW,IVI
 SG_ tbox_ChargeEndTimeValid : 56|1@1+ (1,0) [0|1] ""  GW,IVI
 SG_ tbox_ChargeStartTimeValid : 57|1@1+ (1,0) [0|1] ""  GW,IVI
 SG_ tbox_ChargeSetEnable : 58|1@1+ (1,0) [0|1] ""  GW,IVI
 SG_ tbox_remoteengStartCmd : 59|1@1+ (1,0) [0|1] ""  GW

BO_ 168 TBOX_infoCtrl: 8 TBOX
 SG_ tbox_dvrTakePicCtrl : 0|3@1+ (1,0) [0|7] ""  ICM

BO_ 1278 TBOX_VehicleMode: 8 TBOX
 SG_ tbox_vehicleMode : 0|4@1+ (1,0) [0|15] ""  AMP,ETC,GW,ICM,IVI,NVS,PDC,VSP,WCM
 SG_ TBOX_OTAEnergyCtl : 4|4@1+ (1,0) [0|15] ""  GW
 SG_ TBOX_OTATimeSet : 8|6@1+ (5,0) [0|180] "min"  GW
 SG_ tbox_4FE_rollingCounter : 52|4@1+ (1,0) [0|15] ""  GW
 SG_ tbox_4FE_checksum : 56|8@1+ (1,0) [0|255] ""  GW

BO_ 1576 NM_TBOX: 8 TBOX
 SG_ TBOX_RMR : 8|1@1+ (1,0) [0|1] ""  AMP,ETC,GW,ICM,IVI
 SG_ TBOX_AWB : 12|1@1+ (1,0) [0|1] ""  AMP,ETC,GW,ICM,IVI

BO_ 1793 Diag_PhyReq_BCM: 8 TBOX
 SG_ Diag_PhyReq_BCM_Data : 0|64@1+ (1,0) [0|0] "N/A"  GW

BO_ 1796 Diag_PhyReq_POT: 8 TBOX
 SG_ Diag_PhyReq_POT_Data : 0|64@1+ (1,0) [0|0] "N/A"  GW

BO_ 1797 Diag_PhyReq_DSCU: 8 TBOX
 SG_ Diag_PhyReq_DSCU_Data : 0|64@1+ (1,0) [0|0] "N/A"  GW

BO_ 1806 Diag_PhyReq_GW: 8 TBOX
 SG_ Diag_PhyReq_GW_Data : 0|64@1+ (1,0) [0|0] "N/A"  GW

BO_ 1817 Diag_PhyReq_SWM: 8 TBOX
 SG_ Diag_PhyReq_SWM_Data : 0|64@1+ (1,0) [0|0] "N/A"  GW

BO_ 1824 Diag_PhyReq_HCMR: 8 TBOX
 SG_ Diag_PhyReq_HCMR_Data : 0|64@1+ (1,0) [0|0] "N/A"  GW

BO_ 1825 Diag_PhyReq_HCML: 8 TBOX
 SG_ Diag_PhyReq_HCML_Data : 0|64@1+ (1,0) [0|0] "N/A"  GW

BO_ 1826 Diag_PhyReq_ESC: 8 TBOX
 SG_ Diag_PhyReq_ESC_Data : 0|64@1+ (1,0) [0|0] "N/A"  GW

BO_ 1828 Diag_PhyReq_AVM: 8 TBOX
 SG_ Diag_PhyReq_AVM_Data : 0|64@1+ (1,0) [0|0] "N/A"  GW

BO_ 1830 Diag_PhyReq_AC: 8 TBOX
 SG_ Diag_PhyReq_AC_Data : 0|64@1+ (1,0) [0|0] "N/A"  GW

BO_ 1831 Diag_PhyReq_ASC: 8 TBOX
 SG_ Diag_PhyReq_ASC_Data : 0|64@1+ (1,0) [0|0] "N/A"  GW

BO_ 1833 Diag_PhyReq_GSM: 8 TBOX
 SG_ Diag_PhyReq_GSM_Data : 0|64@1+ (1,0) [0|0] "N/A"  GW

BO_ 1834 Diag_PhyReq_MPC: 8 TBOX
 SG_ Diag_PhyReq_MPC_Data : 0|64@1+ (1,0) [0|0] "N/A"  GW

BO_ 1835 Diag_PhyReq_MRR_R1: 8 TBOX
 SG_ Diag_PhyReq_MRR_R1_Data : 0|64@1+ (1,0) [0|0] "N/A"  GW

BO_ 1836 Diag_PhyReq_MRR_R2: 8 TBOX
 SG_ Diag_PhyReq_MRR_R2_Data : 0|64@1+ (1,0) [0|0] "N/A"  GW

BO_ 1841 Diag_PhyReq_VCU: 8 TBOX
 SG_ Diag_PhyReq_VCU_Data : 0|64@1+ (1,0) [0|0] "N/A"  GW

BO_ 1842 Diag_PhyReq_MCUR0: 8 TBOX
 SG_ Diag_PhyReq_MCUR0_Data : 0|64@1+ (1,0) [0|0] "N/A"  GW

BO_ 1843 Diag_PhyReq_MCUF0: 8 TBOX
 SG_ Diag_PhyReq_MCUF0_Data : 0|64@1+ (1,0) [0|0] "N/A"  GW

BO_ 1844 Diag_PhyReq_BMS: 8 TBOX
 SG_ Diag_PhyReq_BMS_Data : 0|64@1+ (1,0) [0|0] "N/A"  GW

BO_ 1845 Diag_PhyReq_iBooster: 8 TBOX
 SG_ Diag_PhyReq_iB_Data : 0|64@1+ (1,0) [0|0] "N/A"  GW

BO_ 1847 Diag_PhyReq_OBCM: 8 TBOX
 SG_ Diag_PhyReq_OBCM_Data : 0|64@1+ (1,0) [0|0] "N/A"  GW

BO_ 1849 Diag_PhyReq_MRR: 8 TBOX
 SG_ Diag_PhyReq_MRR_Data : 0|64@1+ (1,0) [0|0] "N/A"  GW

BO_ 1851 Diag_PhyReq_BLE: 8 TBOX
 SG_ Diag_PhyReq_BLE_Data : 0|64@1+ (1,0) [0|0] "N/A"  GW

BO_ 1852 Diag_PhyReq_GCU: 8 TBOX
 SG_ Diag_PhyReq_GCU_Data : 0|64@1+ (1,0) [0|0] "N/A"  GW

BO_ 1859 Diag_PhyReq_APA: 8 TBOX
 SG_ Diag_PhyReq_APA_Data : 0|64@1+ (1,0) [0|0] "N/A"  GW

BO_ 1860 Diag_PhyReq_EPS: 8 TBOX
 SG_ Diag_PhyReq_EPS_Data : 0|64@1+ (1,0) [0|0] "N/A"  GW

BO_ 1866 Diag_PhyReq_HANDLE_LF: 8 TBOX
 SG_ Diag_PhyReq_HANDLE_LF_Data : 0|64@1+ (1,0) [0|0] "N/A"  GW

BO_ 1867 Diag_PhyReq_HANDLE_RF: 8 TBOX
 SG_ Diag_PhyReq_HANDLE_RF_Data : 0|64@1+ (1,0) [0|0] "N/A"  GW

BO_ 1868 Diag_PhyReq_HANDLE_LR: 8 TBOX
 SG_ Diag_PhyReq_HANDLE_LR_Data : 0|64@1+ (1,0) [0|0] "N/A"  GW

BO_ 1869 Diag_PhyReq_HANDLE_RR: 8 TBOX
 SG_ Diag_PhyReq_HANDLE_RR_Data : 0|64@1+ (1,0) [0|0] "N/A"  GW

BO_ 1960 Diag_Resp_TBOX: 8 TBOX
 SG_ Diag_Resp_TBOX_Data : 0|64@1+ (1,0) [0|0] "N/A"  GW

BO_ 2016 Diag_PhyReq_ECU: 8 TBOX
 SG_ Diag_PhyReq_ECU_Data : 0|64@1+ (1,0) [0|0] "N/A"  GW

BO_ 2018 OBD_PhyReq_BMS: 8 TBOX
 SG_ OBD_PhyReq_BMS_Data : 0|64@1+ (1,0) [0|0] "N/A"  GW

BO_ 2019 OBD_PhyReq_GCU: 8 TBOX
 SG_ OBD_PhyReq_GCU_Data : 0|64@1+ (1,0) [0|0] "N/A"  GW

BO_ 2020 OBD_PhyReq_OBCM: 8 TBOX
 SG_ OBD_PhyReq_OBCM_Data : 0|64@1+ (1,0) [0|0] "N/A"  GW

BO_ 2021 OBD_PhyReq_iBooster: 8 TBOX
 SG_ OBD_PhyReq_iBooster_Data : 0|64@1+ (1,0) [0|0] "N/A"  GW

BO_ 2022 OBD_PhyReq_ESC: 8 TBOX
 SG_ OBD_PhyReq_ESC_Data : 0|64@1+ (1,0) [0|0] "N/A"  GW

BO_ 2023 OBD_PhyReq_VCU: 8 TBOX
 SG_ OBD_PhyReq_VCU_Data : 0|64@1+ (1,0) [0|0] "N/A"  GW

BO_ 2033 Diag_PhyReq_ACU: 8 TBOX
 SG_ Diag_PhyReq_ACU_Data : 0|64@1+ (1,0) [0|0] "N/A"  GW

BO_ 928 VSP_state: 8 VSP
 SG_ vsp_soundEnable : 4|1@1+ (1,0) [0|1] ""  IVI
 SG_ vsp_errorIdentification : 5|1@1+ (1,0) [0|1] ""  IVI

BO_ 1936 Diag_Resp_VSP: 8 VSP
 SG_ Diag_Resp_VSP_Data : 0|64@1+ (1,0) [0|0] "N/A"  GW,TBOX

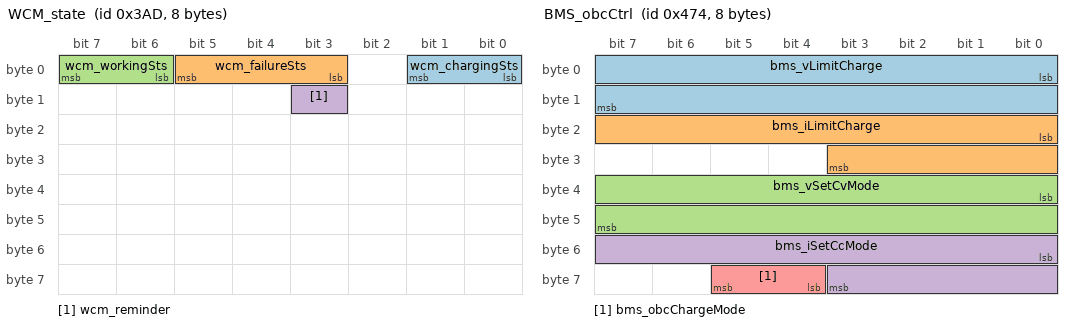
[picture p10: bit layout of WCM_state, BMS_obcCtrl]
BO_ 941 WCM_state: 8 WCM
 SG_ wcm_chargingSts : 0|2@1+ (1,0) [0|3] ""  IVI
 SG_ wcm_failureSts : 3|3@1+ (1,0) [0|7] ""  IVI
 SG_ wcm_workingSts : 6|2@1+ (1,0) [0|3] ""  IVI
 SG_ wcm_reminder : 11|1@1+ (1,0) [0|1] ""  IVI

BO_ 1933 Diag_Resp_WCM: 8 WCM
 SG_ Diag_Resp_WCM_Data : 0|64@1+ (1,0) [0|0] "N/A"  GW,TBOX

BO_ 1140 BMS_obcCtrl: 8 GW
 SG_ bms_vLimitCharge : 0|16@1+ (0.1,0) [0|6553.5] "V"  TBOX
 SG_ bms_iLimitCharge : 16|12@1+ (0.1,0) [0|409.5] "A"  TBOX
 SG_ bms_vSetCvMode : 32|16@1+ (0.1,0) [0|6553.5] "V" Vector__XXX
 SG_ bms_iSetCcMode : 48|12@1+ (0.1,0) [0|409.5] "A"  TBOX
 SG_ bms_obcChargeMode : 60|2@1+ (1,0) [0|3] "" Vector__XXX

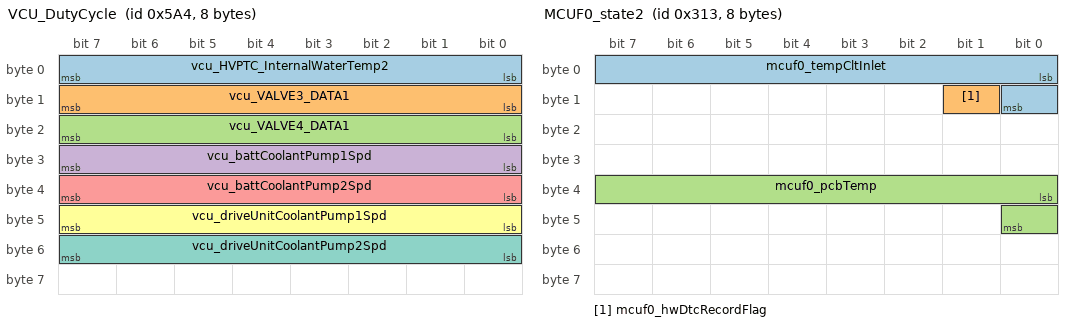
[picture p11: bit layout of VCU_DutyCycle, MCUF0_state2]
BO_ 1444 VCU_DutyCycle: 8 GW
 SG_ vcu_HVPTC_InternalWaterTemp2 : 0|8@1+ (1,-50) [0|100] "%" Vector__XXX
 SG_ vcu_VALVE3_DATA1 : 8|8@1+ (0.392,0) [0|99.96] "%"  TBOX
 SG_ vcu_VALVE4_DATA1 : 16|8@1+ (0.392,0) [0|99.96] "%"  TBOX
 SG_ vcu_battCoolantPump1Spd : 24|8@1+ (0.392,0) [0|99.96] "%" Vector__XXX
 SG_ vcu_battCoolantPump2Spd : 32|8@1+ (0.392,0) [0|99.96] "%" Vector__XXX
 SG_ vcu_driveUnitCoolantPump1Spd : 40|8@1+ (0.392,0) [0|99.96] "%" Vector__XXX
 SG_ vcu_driveUnitCoolantPump2Spd : 48|8@1+ (0.392,0) [0|99.96] "%" Vector__XXX

BO_ 1445 VCU_PTCPower: 8 GW
 SG_ vcu_HVPTC_HV_DC_curr : 0|8@1+ (0.25,0) [0|63.5] "A"  TBOX
 SG_ vcu_HVPTC_HV_voltage : 8|8@1+ (2,0) [0|508] "V"  TBOX

BO_ 787 MCUF0_state2: 8 GW
 SG_ mcuf0_tempCltInlet : 0|9@1+ (0.5,-40) [-40|215] "℃" Vector__XXX
 SG_ mcuf0_hwDtcRecordFlag : 9|1@1+ (1,0) [0|1] "" Vector__XXX
 SG_ mcuf0_pcbTemp : 32|9@1+ (0.5,-40) [-40|215] "℃"  TBOX

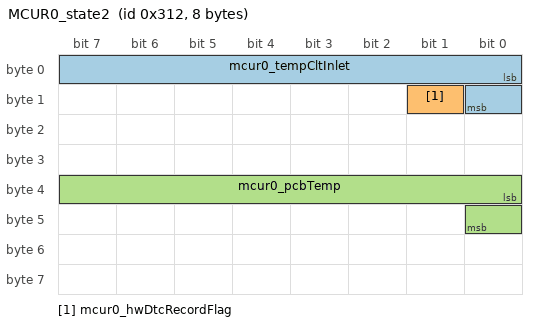
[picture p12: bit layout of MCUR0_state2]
BO_ 786 MCUR0_state2: 8 GW
 SG_ mcur0_tempCltInlet : 0|9@1+ (0.5,-40) [-40|215] "℃" Vector__XXX
 SG_ mcur0_hwDtcRecordFlag : 9|1@1+ (1,0) [0|1] "" Vector__XXX
 SG_ mcur0_pcbTemp : 32|9@1+ (0.5,-40) [-40|215] "℃"  TBOX

CM_ SG_ 1924 Diag_Resp_POT_Data "Diagnostic Physical response Data from POT";
CM_ SG_ 1925 Diag_Resp_DSCU_Data "Diagnostic Physical response Data from DSCU";
CM_ SG_ 1934 Diag_Resp_GW_Data "Diagnostic Physical response Data from GW";
CM_ SG_ 1945 Diag_Resp_SWM_Data "Diagnostic Physical response Data from SWM";
CM_ SG_ 1952 Diag_Resp_HCMR_Data "Diagnostic Physical response Data from HCMR";
CM_ SG_ 1953 Diag_Resp_HCML_Data "Diagnostic Physical response Data from HCML";
CM_ SG_ 1954 Diag_Resp_ESC_Data "Diagnostic Physical response Data from ESC";
CM_ SG_ 1956 Diag_Resp_AVM_Data "Diagnostic Physical response Data from AVM";
CM_ SG_ 1958 Diag_Resp_AC_Data "Diagnostic Physical response Data from AC";
CM_ SG_ 1959 Diag_Resp_ASC_Data "Diagnostic Physical response Data from ASC";
CM_ SG_ 1961 Diag_Resp_GSM_Data "Diagnostic physical response data from GSM";
CM_ SG_ 1962 Diag_Resp_MPC_Data "Diagnostic Physical response Data from MPC";
CM_ SG_ 1963 Diag_Resp_MRR_R1_Data "Diagnostic Physical response Data from MRR_R1";
CM_ SG_ 1964 Diag_Resp_MRR_R2_Data "Diagnostic Physical response Data from MRR_R2";
CM_ SG_ 1969 Diag_Resp_VCU_Data "Diagnostic physical response data from VCU";
CM_ SG_ 1970 Diag_Resp_MCUR0_Data "Diagnostic physical response data from MCUR0";
CM_ SG_ 1971 Diag_Resp_MCUF0_Data "Diagnostic physical response data from MCUF0";
CM_ SG_ 1972 Diag_Resp_BMS_Data "Diagnostic physical response data from BMS";
CM_ SG_ 1973 Diag_Resp_iB_Data "Diagnostic Physical response Data from iBooster";
CM_ SG_ 1975 Diag_Resp_OBCM_Data "Diagnostic physical response data from OBCM";
CM_ SG_ 1977 Diag_Resp_MRR_Data "Diagnostic Physical response Data from MRR";
CM_ SG_ 1979 Diag_Resp_BLE_Data "Diagnostic Physical response Data from BLE";
CM_ SG_ 1980 Diag_Resp_GCU_Data "Diagnostic physical response data from GCU";
CM_ SG_ 1987 Diag_Resp_APA_Data "Diagnostic Physical response Data from APA";
CM_ SG_ 1988 Diag_Resp_EPS_Data "Diagnostic Physical response Data from EPS";
CM_ SG_ 1994 Diag_Resp_HANDLE_LF_Data "Diagnostic Physical response Data from HANDLE_LF";
CM_ SG_ 1995 Diag_Resp_HANDLE_RF_Data "Diagnostic Physical response Data from HANDLE_RF";
CM_ SG_ 1996 Diag_Resp_HANDLE_LR_Data "Diagnostic Physical response Data from HANDLE_LR";
CM_ SG_ 1997 Diag_Resp_HANDLE_RR_Data "Diagnostic Physical response Data from HANDLE_RR";
CM_ SG_ 2015 Diag_FuncReq_Data "Diagnostic functional request data";
CM_ SG_ 2024 Diag_Resp_ECU_Data "Diagnostic physical response data from ECU";
CM_ SG_ 2026 OBD_Resp_BMS_Data "Diagnostic physical response data from BMS";
CM_ SG_ 2027 OBD_Resp_GCU_Data "Diagnostic physical response data from GCU";
CM_ SG_ 2028 OBD_Resp_OBCM_Data "Diagnostic physical response data from OBCM";
CM_ SG_ 2029 OBD_Resp_iBooster_Data "Diagnostic physical response data from iBooster";
CM_ SG_ 2030 OBD_Resp_ESC_Data "Diagnostic physical response data from ESC";
CM_ SG_ 2031 OBD_Resp_VCU_Data "Diagnostic physical response data from VCU";
CM_ SG_ 2041 Diag_Resp_ACU_Data "Diagnostic Physical response Data from ACU";
CM_ SG_ 937 icm_dvrSts "DVR status.";
CM_ SG_ 937 icm_dvrPhotoSts "DVR Photo status.";
CM_ SG_ 937 icm_dvrSDcardSts "SD card status.";
CM_ SG_ 937 icm_dvrPhotoOutput "take pic status.";
CM_ SG_ 937 icm_dvrExitReq "exit request.";
CM_ SG_ 937 icm_roaSts "ROA status.";
CM_ SG_ 937 icm_roaDisplayRes "ROA display response.";
CM_ SG_ 937 icm_roaPassengerL "ROA passenger lift.";
CM_ SG_ 937 icm_roaPassengerM "ROA passenger middle.";
CM_ SG_ 937 icm_roaPassengerR "ROA passenger right.";
CM_ SG_ 937 icm_roaPassengerAge "ROA passenger age.";
CM_ SG_ 937 icm_roaPassengerMood "ROA passenger mood.";
CM_ SG_ 937 icm_ivipressphto "DVR请求车机传输照片";
CM_ SG_ 937 icm_dmsSts "DMS status.";
CM_ SG_ 937 icm_dmsCameraSts "DMS camera status.";
CM_ SG_ 937 icm_dmsWearySet "DMS weary set.";
CM_ SG_ 937 icm_dmsWearyAssisSet "DMS weary assis set.";
CM_ SG_ 937 icm_dmsWearyLeverSts "DMS weary lever status.";
CM_ SG_ 937 icm_dmsDrvBehaviorMon "DMS driving behavior monitor.";
CM_ SG_ 937 icm_dmsDistractLeverSts "DMS distract lever status.";
CM_ SG_ 937 icm_dmsSenSetRsp "sensitive set response";
CM_ SG_ 937 icm_roaRemind "ROA Remind";
CM_ SG_ 937 icm_dmsDriverMood "DMS driving mood.";
CM_ SG_ 937 icm_dmsDriver "DMS driver.";
CM_ SG_ 937 icm_dmsPassenger "DMS passenger.";
CM_ SG_ 937 icm_dmsFaceID "DMS face ID.";
CM_ SG_ 937 icm_dmsGestureID "DMS gesture ID.";
CM_ SG_ 937 icm_dmsVideoCallSts "DMS video call status.";
CM_ SG_ 937 icm_roaITLLightReq "ROA  requests to light ITL.";
CM_ SG_ 937 icm_dvrVideoOutput "DVR video output.";
CM_ SG_ 937 icm_roaCameraSts "ROA camera status.";
CM_ SG_ 939 icm_dmsFaceIDResp "DMS face ID Response";
CM_ SG_ 939 icm_dmsGestureIDResp "DMS gesture ID Response";
CM_ SG_ 939 icm_FaceIDRegiResp "Face ID registration Response";
CM_ SG_ 939 icm_FaceIDLoginResp "Face ID log in";
CM_ SG_ 939 icm_beautyResp "美颜开关状态反馈";
CM_ SG_ 939 icm_arDisplayResponse "AR  导航显示";
CM_ SG_ 939 icm_cameraChangeResp "ICM反馈相机切换视频流";
CM_ SG_ 939 icm_dmsDistractForfvsr "驾驶员状态信号";
CM_ SG_ 939 icm_FaceIDNumberResp "icm反馈目前已录入多少个人脸";
CM_ SG_ 939 icm_dmsRegiFaceID "icm反馈目前注册成功的faceid";
CM_ SG_ 939 icm_dmsLoginFaceID "icm反馈目前登陆成功的faceid";
CM_ SG_ 939 icm_dmsDeleteFaceID "icm反馈目前删除成功的faceid";
CM_ SG_ 939 icm_FaceIDEmptydataResp "icm反馈清空数据的状态";
CM_ SG_ 939 icm_dmsRegiFaceIDSts "icm反馈收到了ivi的登陆成功事件";
CM_ SG_ 1545 ICM_RMR "Repeat Message Request";
CM_ SG_ 1545 ICM_AWB "Active Wakeup Bit";
CM_ SG_ 1929 Diag_Resp_ICM_Data "Diagnostic Physical response Data from ICM";
CM_ SG_ 82 ic_engOffTime "Engine Off Time.";
CM_ SG_ 82 ic_engOffTimeValid "Engine Off Time Valid.";
CM_ SG_ 117 ivi_hoodUnlockCtrl "Hood unlock control.";
CM_ SG_ 117 ivi_RearWindowLockCtrl "Child Safety Lock Control.(儿童安全锁/后排车窗锁止控制)";
CM_ SG_ 117 ivi_gloveBoxUnlockCtrl "glove box unlock control";
CM_ SG_ 117 ivi_centralLockCtrl "Central lock control.";
CM_ SG_ 117 ivi_fuelPortCapOpenCtrl "Fuel port cap open close control.";
CM_ SG_ 117 ivi_lowBeamOnOffCtrl "Low beam on off control.";
CM_ SG_ 117 ivi_v2vChrgOnOffSet "V2V charging turn ON or OFF set.";
CM_ SG_ 117 ivi_posLampOnOffCtrl "Position lamp on off control.";
CM_ SG_ 117 ivi_obcDschrgOnOffSet "OBC discharging turn ON or OFF set.";
CM_ SG_ 117 ivi_modememory "memory mode.";
CM_ SG_ 117 ivi_rearFogLampOnOffCtrl "Rear fog lamp on off control.";
CM_ SG_ 117 ivi_ventilateSts "ventilate Status.";
CM_ SG_ 117 ivi_chrgPortCapOpenCtrl "Charging port cap open control.";
CM_ SG_ 117 ivi_sunroofGlassCmd "Sunroof  Glass control command";
CM_ SG_ 117 ivi_NormalHvOffReq "Normal high voltage Off Request.";
CM_ SG_ 117 ivi_antiTheftAlarmFormSet "anti Theft Alar mForm Set";
CM_ SG_ 117 ivi_tailgateCtrl "Tailgate control.";
CM_ SG_ 117 ivi_MirrorSw "Rearview mirror switch  control.";
CM_ SG_ 117 ivi_rearDefrostCtrl "Rear defrost control.";
CM_ SG_ 117 IVI_SOCmodeSet "SOC set mode to VCU.
事件发生时，发送三帧有效信号后信号值发送0x0:no request";
CM_ SG_ 117 ivi_MaxFuelConsumptionSW "Maximum fuel consumption switch control.";
CM_ SG_ 117 ivi_MaxFuelConsumptionModeSW "Maximum fuel consumption mode switch control.";
CM_ SG_ 117 ivi_v2vChrgOptCurntSet "V2V charging output current set.";
CM_ SG_ 117 ivi_BatteryCondition "Battery Condition.";
CM_ SG_ 117 ivi_approachingUnlockCtrl "approaching unlock control.";
CM_ SG_ 117 ivi_awayLockCtrl "away lock control.";
CM_ SG_ 117 ivi_WipperMaintenanceCtrl "wipper maint  mode Control.";
CM_ SG_ 117 ivi_gunUnlockCtrlReq "Gun Unlock request from IVI";
CM_ SG_ 117 ivi_ExhibitionSet "Exhibition mode set req
事件发生时，发送三帧有效信号后信号值发送0x0:no request";
CM_ SG_ 117 ivi_potOnOffSet "POT on off set.
信号触发后发送3-5帧，然后信号值回到0x0；";
CM_ SG_ 117 ivi_frontWindshieldHeatingCtrl "front Windshield Heating Control.";
CM_ SG_ 117 ivi_lowVoltPowerCtrl "low Voltage Power Control.";
CM_ SG_ 133 ivi_pot_SpeechCtrlOnOffSts "Speech control POT on/off status.";
CM_ SG_ 133 ivi_ChargPileAuthSts "IVI充电桩鉴权状态";
CM_ SG_ 149 ivi_lockAutoCloseWinCtrl "lock Auto Close Window Control";
CM_ SG_ 149 ivi_ambientLightOnOffSet "Ambient light on/off set.";
CM_ SG_ 149 ivi_sunroofRollshadeCtrlSelect "ivi下发选择天窗还是遮阳帘的控制信号";
CM_ SG_ 149 ivi_ambientLightColorSet "Ambient light color set(64 colors, each value represents a color).";
CM_ SG_ 149 ivi_ambientLightLumiLvSet "Ambient light luminance level set.";
CM_ SG_ 149 ivi_screenAutoLiftCtrl "screen Auto Lift Control";
CM_ SG_ 149 ivi_doorTopSW "door top switch.";
CM_ SG_ 149 ivi_parkAutoCloseDRLCtrl "驻车自动关闭日行灯控制信号";
CM_ SG_ 149 ivi_followMeHomeSet "Follow me home function set.";
CM_ SG_ 149 ivi_WheelAlignmentCtrl "Wheel Alignment Control";
CM_ SG_ 149 ivi_WinLFCtrlRqst "left front window Control request.";
CM_ SG_ 149 ivi_WinRFCtrlRqst "right front window Control request.";
CM_ SG_ 149 ivi_WinLRCtrlRqst "left rear window Control request.";
CM_ SG_ 149 ivi_WinRRCtrlRqst "right rear window Control request.";
CM_ SG_ 149 IVI_DGSW "DG switch.";
CM_ SG_ 149 IVI_DGPercentCtrl "DG Percent Control.";
CM_ SG_ 149 IVI_speedautolockonoffSet "Speed automatic lock on/off set.";
CM_ SG_ 149 ivi_adbOnOffSet "Turn ADB on/off set.";
CM_ SG_ 149 ivi_hcmHeightSet "HCM height set.";
CM_ SG_ 165 ivi_4wdModeSet "4WD mode set.";
CM_ SG_ 165 ivi_ChargeCancel "Cancel Charge.";
CM_ SG_ 165 ivi_RegenModeSet "Energy recovery on off set.";
CM_ SG_ 165 ivi_maxChargeCurrentSet "Maximum charge current set.";
CM_ SG_ 165 ivi_TowModeSet "tow Mode Set";
CM_ SG_ 165 ivi_maxChrgSocSet "Maximum charge SOC set.";
CM_ SG_ 165 ivi_chargeFormSet "Charge form set.";
CM_ SG_ 165 ivi_ChargeEnable "充电开始使能（可开始立即充电+开始预约充电）";
CM_ SG_ 165 ivi_highwayModeRequest "自动设置高速公路调节功能";
CM_ SG_ 165 ivi_chargeSetValid "Slow charge set valid signal.";
CM_ SG_ 165 ivi_ChargeEndTimeHour "Charge End Time:Hour.";
CM_ SG_ 165 ivi_ChargeStartTimeHour "Charge Start Time:Hour.";
CM_ SG_ 165 ivi_ChargeEndTimeHalfDay "Charge End Time:Half Day.";
CM_ SG_ 165 ivi_ChargeStartTimeHalfDay "Charge Start Time:Half Day.";
CM_ SG_ 165 ivi_ChargeEndTimeMinute "Charge End Time:Minute.";
CM_ SG_ 165 ivi_ChargeStartTimeMinute "Charge Start Time:Minute.";
CM_ SG_ 165 ivi_ResetCurrentTrip "Reset Current Trip.";
CM_ SG_ 165 ivi_BCMEBSHvoffset "BCM/EBS higf voltage offset.";
CM_ SG_ 165 ivi_ChargeEndTimeValid "Charge End Time Valid.";
CM_ SG_ 165 ivi_ChargeStartTimeValid "Charge Start Time Valid.";
CM_ SG_ 165 ivi_driveModeSet "Driving mode set.";
CM_ SG_ 197 ivi_reservationChargeModeSet "Reservation charge mode set(预约充电定时方式设置)";
CM_ SG_ 197 ivi_wcmOnOffSet "WCM ON/OFF set.";
CM_ SG_ 197 ivi_vspOnOffSet "VSP ON/OFF set.";
CM_ SG_ 197 ivi_weightlowFrqSet "重低音设置";
CM_ SG_ 197 ivi_etcBTReq "IVI控制ETC蓝牙开关";
CM_ SG_ 245 ivi_autoEasyEntrySet "Automatic easy entry function set.";
CM_ SG_ 245 ivi_drSeatHeatOnOffSet "Driver seat heating ON /OFF set.";
CM_ SG_ 245 ivi_drSeatVentOnOffSet "Driver seat Venting ON /OFF set.";
CM_ SG_ 245 ivi_drSeatMassOnOffSet "Driver seat Massage ON /OFF set.";
CM_ SG_ 245 ivi_drSeatHeatLevelSet "Driver seat heating level set.";
CM_ SG_ 245 ivi_drSeatVentLevelSet "Driver seat Venting level set.";
CM_ SG_ 245 ivi_passSeatHeatOnOffSet "Passenger seat heating ON /OFF set.";
CM_ SG_ 245 ivi_passSeatVentOnOffSet "Passenger seat Venting ON /OFF set.";
CM_ SG_ 245 ivi_passSeatHeatLevelSet "Passenger seat heating level set.";
CM_ SG_ 245 ivi_passSeatVentLevelSet "Passenger seat Venting level set.";
CM_ SG_ 245 ivi_passSeatMassOnOffSet "Passenger seat Massage ON /OFF set.";
CM_ SG_ 245 ivi_drSeatMassLevelSet "Driver seat Massage level set.";
CM_ SG_ 245 ivi_passSeatMassLevelSet "Passenger seat Massage level set.";
CM_ SG_ 245 ivi_MirrorAutoFoldUnfoldSet "Mirror auto fold/unfold function set.";
CM_ SG_ 245 ivi_easyEntrySet "对用户进入车辆时座椅自动调节的设置";
CM_ SG_ 245 ivi_dsmSetMemoryReq "memory set request.";
CM_ SG_ 245 ivi_dsmGetMemoryReq "dsm Get memory  request.";
CM_ SG_ 245 ivi_rvMirrorAutoTurnDownSet "Rearview mirror auto turn down on off set.
后视镜自动下翻控制";
CM_ SG_ 245 ivi_DrMassgIntenSet "Driver Seat massage Inten Set.";
CM_ SG_ 245 ivi_PsgMassgIntenSet "Passenger Seat massage Inten Set.";
CM_ SG_ 245 ivi_manualEasyOutSw "Manualeasyentryfunctionswitch";
CM_ SG_ 245 ivi_potPositionStsSet "POT Position Status Set .";
CM_ SG_ 245 ivi_welcomeOnOffSet "welcome On/Off set.";
CM_ SG_ 245 ivi_welcomeSetEnable "迎宾功能使能信号";
CM_ SG_ 261 ivi_dvrDisplayReq "DVR display request.";
CM_ SG_ 261 ivi_dvrCoTouchMotion "DVR image user Touch or release coordinate.";
CM_ SG_ 261 ivi_dvrXCoordinate "DVR X coordinate.";
CM_ SG_ 261 ivi_dvrYCoordinate "DVR Y coordinate.";
CM_ SG_ 261 ivi_roaDisplayReq "ROA display request.";
CM_ SG_ 261 ivi_ICMpressphtoresp "IVI答复DVR可以开始传输";
CM_ SG_ 261 ivi_dmsWearyAssisSet "DMS Weary Assis Set.";
CM_ SG_ 261 ivi_dmsCameraCtl "DMS Camera control.";
CM_ SG_ 261 ivi_dmsWearySet "DMS Weary Set.";
CM_ SG_ 261 ivi_dmsSenSet "Sensitive Set.";
CM_ SG_ 261 ivi_ICMBeautySet "美颜开关设置";
CM_ SG_ 261 ivi_cameraChange "IVI相机切换视频流";
CM_ SG_ 261 ivi_videoCallSts "Video Call Status.";
CM_ SG_ 261 ivi_nvsDisplay "NVS display.";
CM_ SG_ 261 ivi_nvsOCRPress "NVS OCR Press.";
CM_ SG_ 261 ivi_ArdisplayReq "AR Display";
CM_ SG_ 261 ivi_dvrPhotoReceive "DVR照片上传请求";
CM_ SG_ 261 ivi_dvrVideoReceive "m";
CM_ SG_ 261 ivi_roaCameraCtl "roa Camera control";
CM_ SG_ 270 ivi_AVMTrigByTurnningSts "Set the function of “AVM trigger by turning“.";
CM_ SG_ 270 ivi_AVMViewModeSw "The AVM 2D/3D view switch.";
CM_ SG_ 270 ivi_modeSw "AVM mode switch.";
CM_ SG_ 270 ivi_viewSw_Reserved "AVM view switch.";
CM_ SG_ 270 ivi_screenCoordX "Screen coord X.";
CM_ SG_ 270 ivi_screenCoordY "Screen coord Y.";
CM_ SG_ 270 ivi_avm_monVideoReceive "IVI receive AVM monitor video status (IVI是否允许AVM传输录制哨兵功能的视频信号";
CM_ SG_ 270 ivi_MODSw "MOD Switch (移动物体检测开关)";
CM_ SG_ 270 ivi_AVMTrajectorySW "Trajectory line Switch (轨迹线开关)";
CM_ SG_ 270 ivi_AVMAutoswitchingSW "AutovswitchingvSwitch (智能切换视角开关)";
CM_ SG_ 270 ivi_AVM_transparentSW "Car body transparent switch. (透明车辆开关)";
CM_ SG_ 270 ivi_View_select "IVI requests AVM to switch diferent views. IVI发送的AVM视图切换信号";
CM_ SG_ 270 IVI_Voice_AVMOnOffReq "语音开启环视请求";
CM_ SG_ 270 ivi_touchScreenCtrl "Touch screen signal.";
CM_ SG_ 270 ivi_naviSts "导航前后台状态信息同步";
CM_ SG_ 270 IVI_Voice_APAOnOffReq "语音开启APA";
CM_ SG_ 270 IVI_Voice_CarbodyTransparentReq "语音开启透明车体";
CM_ SG_ 286 ivi_vehicleSpeedCompModeReq "Vehicle Speed Compensation Mode (on/off) request";
CM_ SG_ 286 ivi_highFrqSet "High frequency audio set";
CM_ SG_ 286 ivi_mediaVolSet "Media Volume Adjustment (A2B Ch5 & 6)";
CM_ SG_ 286 ivi_muteAllSpeakers "Mute all speakers";
CM_ SG_ 286 ivi_midFrqSet "Mid Frequency Audio Set";
CM_ SG_ 286 ivi_lowFrqSet "Low frequency audio set";
CM_ SG_ 286 ivi_amp_dyaudioSoundFeature "音响模式";
CM_ SG_ 286 ivi_loudnessOnOffSet "声音补偿";
CM_ SG_ 286 ivi_soundFieldSet "声场设置";
CM_ SG_ 286 ivi_audioBlcSet "Left/Right Audio Balance Set";
CM_ SG_ 286 ivi_audioFaderSet "Front/Rear Audio Fader Set";
CM_ SG_ 446 ivi_epsModeSet "EPS mode set.";
CM_ SG_ 446 ivi_escOffSw "ESC off switch.";
CM_ SG_ 446 ivi_hdcOnOffSet "HDC ON OFF set.";
CM_ SG_ 446 ivi_aebOnOffSet "AEB ON OFF set.";
CM_ SG_ 446 ivi_iBModeSet "iBooster  Mode  Set";
CM_ SG_ 446 ivi_lksSensitivitySet "LKS sensitivity set.";
CM_ SG_ 446 ivi_lcaBsdOnOffSet "Lane change assist/Blind Spot Detection ON OFF set.";
CM_ SG_ 446 ivi_rctaOnOffSet "Rear CTA ON OFF set.";
CM_ SG_ 446 ivi_dowOnOffSet "Door open warning ON OFF set.";
CM_ SG_ 446 ivi_startRevSOCSet "Start Recovery  SOC Limit Set.";
CM_ SG_ 446 ivi_speedLimitWarningMode "Speed limit assist warning mode.";
CM_ SG_ 446 ivi_ISAOnOffSet "Speed limit assist ON OFF set.";
CM_ SG_ 446 ivi_currentRoadType "Current road type.";
CM_ SG_ 446 ivi_countryCodeSet "Country code set.";
CM_ SG_ 446 ivi_FrtVehStrReminderSw "前车驶离提醒功能使能设置";
CM_ SG_ 446 ivi_speedLimitUnitSet "Speed Limit Unit set.";
CM_ SG_ 446 ivi_speedLimitStsSet "Speed Limit Status set.";
CM_ SG_ 446 ivi_propModeSet "Propulsion mode set.";
CM_ SG_ 446 ivi_pcwOnOffSet "PCW ON OFF set.";
CM_ SG_ 446 ivi_torqueDistModeSet "Torque distribution mode set";
CM_ SG_ 446 ivi_rcwOnOffSet "RCW ON OFF set.";
CM_ SG_ 446 ivi_trailerModeOnOffSet "Trailer mode ON OFF set(reserve).";
CM_ SG_ 446 ivi_esc_epbButtonRelease "EPB button release.";
CM_ SG_ 469 ivi_ASCMaintainModeReq "ASC Maintain Mode Requeest.";
CM_ SG_ 469 ivi_laneAssistFuncSet "Lane assist function set.";
CM_ SG_ 469 ivi_lasWarningModeSelection "LAS Warning Mode Set.";
CM_ SG_ 469 ivi_EmergencyHvOffRequest "Emergency High voltage Off Request.";
CM_ SG_ 469 ivi_1D5_RollingCounter "chassisSet1_message rolling Counter.";
CM_ SG_ 469 ivi_1D5_CheckSum "chassisSet1_CRC8  CheckSum.";
CM_ SG_ 497 ivi_faceIDSet "Face ID Set.";
CM_ SG_ 497 ivi_gestureIDSet "Gesture ID Set.";
CM_ SG_ 497 ivi_dmsFaceIDRegiReq "Face ID registration";
CM_ SG_ 497 ivi_FaceIDLoginReq "IVI Face ID login request";
CM_ SG_ 497 ivi_dmsRegiFaceID "ivi请求目前需要注册的faceid";
CM_ SG_ 497 ivi_dmsDeleteFaceID "ivi请求目前需要删除的faceid";
CM_ SG_ 497 ivi_FaceIDEmptydataResp "ivi通知ICM清空数据";
CM_ SG_ 497 ivi_dmsRegiFaceIDSts "ivi反馈目前已成功使用faceid登陆的状态";
CM_ SG_ 766 ic_totalMileage "Total mileage.";
CM_ SG_ 766 ic_lowSocIndication "Low SOC indication.";
CM_ SG_ 766 ic_displayFail "Error in the display or display control unit.(ADAS Reruirment).";
CM_ SG_ 766 ic_qDashACCFail "Error in the ACC message detected by the HMI, like timeout or alivecounter error.";
CM_ SG_ 766 ic_RemainingMileage "Remaining Mileage";
CM_ SG_ 766 ic_vehicleSpeedDisp "IC displayed vehicle speed.";
CM_ SG_ 766 ic_brakeFluidLevel "Brake fluid level.";
CM_ SG_ 766 ic_totalMileageValid "Total mileage valid signal.";
CM_ SG_ 766 ic_vehicleSpeedDispValid "IC displayed vehicle speed valid signal.";
CM_ SG_ 766 ic_2FE_RollingCounter "message rolling counter.";
CM_ SG_ 766 ic_2FE_CheckSum "CRC8 checksum";
CM_ SG_ 849 ivi_dsSeatBackPos "Driver seat back position.
主驾靠背位置（百分比）";
CM_ SG_ 849 ivi_dsSeatSlidePos "Driver  seat slide position.
主驾滑道位置（百分比）";
CM_ SG_ 849 ivi_dsSeatHeightPos "Driver seat height position.
主驾高度位置（百分比）";
CM_ SG_ 849 ivi_dsSeatCushionAnglePos "Driver's seat cushion angle position.
主驾座垫角度位置（百分比）";
CM_ SG_ 849 ivi_LeftMirrorVerticalPos "左后视镜上下位置（百分比）";
CM_ SG_ 849 ivi_LeftMirrorHorizontalPos "左后视镜左右位置（百分比）";
CM_ SG_ 849 ivi_RightMirrorVerticalPos "右后视镜上下位置（百分比）";
CM_ SG_ 849 ivi_RightMirrorHorizontalPos "右后视镜左右位置（百分比）";
CM_ SG_ 850 ivi_dsSeatBackPos2 "Driver seat back position.
主驾靠背位置（百分比）";
CM_ SG_ 850 ivi_dsSeatSlidePos2 "Driver  seat slide position.
主驾滑道位置（百分比）";
CM_ SG_ 850 ivi_dsSeatHeightPos2 "Driver seat height position.
主驾高度位置（百分比）";
CM_ SG_ 850 ivi_dsSeatCushionAnglePos2 "Driver's seat cushion angle position.
主驾座垫角度位置（百分比）";
CM_ SG_ 850 ivi_LeftMirrorVerticalPos2 "左后视镜上下位置（百分比）";
CM_ SG_ 850 ivi_LeftMirrorHorizontalPos2 "左后视镜左右位置（百分比）";
CM_ SG_ 850 ivi_RightMirrorVerticalPos2 "右后视镜上下位置（百分比）";
CM_ SG_ 850 ivi_RightMirrorHorizontalPos2 "右后视镜左右位置（百分比）";
CM_ SG_ 851 ivi_dsSeatBackPos3 "Driver seat back position.
主驾靠背位置（百分比）";
CM_ SG_ 851 ivi_dsSeatSlidePos3 "Driver  seat slide position.
主驾滑道位置（百分比）";
CM_ SG_ 851 ivi_dsSeatHeightPos3 "Driver seat height position.
主驾高度位置（百分比）";
CM_ SG_ 851 ivi_dsSeatCushionAnglePos3 "Driver's seat cushion angle position.
主驾座垫角度位置（百分比）";
CM_ SG_ 851 ivi_LeftMirrorVerticalPos3 "左后视镜上下位置（百分比）";
CM_ SG_ 851 ivi_LeftMirrorHorizontalPos3 "左后视镜左右位置（百分比）";
CM_ SG_ 851 ivi_RightMirrorVerticalPos3 "右后视镜上下位置（百分比）";
CM_ SG_ 851 ivi_RightMirrorHorizontalPos3 "右后视镜左右位置（百分比）";
CM_ SG_ 949 ivi_hvacOnOffReq "Request HVAC switch Status.";
CM_ SG_ 949 ivi_hvacAutoModeReq "HVAC auto mode request.";
CM_ SG_ 949 ivi_hvacRecircModeReq "HVAC recirculation mode request.";
CM_ SG_ 949 ivi_hvacModeReq "HVAC mode request.
空调模式请求（具有联动功能）";
CM_ SG_ 949 ivi_driverTempCSet "Driver Temperature Celsius.";
CM_ SG_ 949 ivi_passengerTempCSet "Passenger Temperature Celsius set.";
CM_ SG_ 949 ivi_hvacDualMode "HVAC Dual mode.";
CM_ SG_ 949 ivi_acReq "Request the status of HVAC clutch.";
CM_ SG_ 949 ivi_pm25StsReq "PM25请求";
CM_ SG_ 949 ivi_acWorkModeSet "空调工作模式设置";
CM_ SG_ 949 ivi_acDiagReq "AC diagnostic request.";
CM_ SG_ 949 IVI_Backlightadjust "Adjust the backlight";
CM_ SG_ 949 IVI_FreshAirModeSet "换气设置";
CM_ SG_ 949 IVI_VentilationCoolSet "通风降温设置";
CM_ SG_ 949 ivi_frontDefrostCtrl "单独控制前除霜";
CM_ SG_ 949 ivi_languageSet "Language set.";
CM_ SG_ 949 ivi_unitSet "Length measurement unit set.";
CM_ SG_ 949 ivi_hvacBlowLvReq "HVAC blow level request.";
CM_ SG_ 949 IVI_Sunroof_HorizontalControl "天窗开度控制命令";
CM_ SG_ 1011 IC_MaintenanceMileage "剩余保养里程";
CM_ SG_ 1011 ic_lastingtime "lasting time of current tripmeter.";
CM_ SG_ 1011 ic_mileageSincethelastcharge "mileage  display  since the last charge.";
CM_ SG_ 1011 ic_tripmeterThisMoment "tripmeter this moment.";
CM_ SG_ 1011 IC_MaintenanceReset "保养里程清零";
CM_ SG_ 1248 ic_totalMileageRev "Total mileage of REV.";
CM_ SG_ 1013 IC_TripBAvgPwrConsum "TripB平均电耗";
CM_ SG_ 1013 IC_TripAAvgPwrConsum "TripA平均电耗";
CM_ SG_ 1013 IC_SinceChargeAvgPwrConsum "自上次充电平均电耗";
CM_ SG_ 1013 IC_CurrentTripAvgPwrConsum "自启动平均电耗";
CM_ SG_ 1022 ivi_timeInfoSecond "Time informatioin:Second.";
CM_ SG_ 1022 ivi_timeInfoMinute "Time informatioin:Minute.";
CM_ SG_ 1022 ivi_timeInfoHour "Time informatioin：Hour.";
CM_ SG_ 1022 ivi_timeInfoDay "Time informatioin：Day.";
CM_ SG_ 1022 ivi_timeInfoMonth "Time informatioin：Month.";
CM_ SG_ 1022 ivi_timeInfoYear "Time informatioin:Year.";
CM_ SG_ 1022 ivi_timeValid "Time Valid.";
CM_ SG_ 1022 ivi_altitude "海拔高度";
CM_ SG_ 1154 IC_FuelConsump "瞬时油耗";
CM_ SG_ 1154 IC_ConsumpRatioInstant "瞬时电耗";
CM_ SG_ 1154 ic_oilPercentFail "oil percent sensor error.";
CM_ SG_ 1154 IC_OilRemainingMileage "燃油续航里程（增程车）";
CM_ SG_ 1154 ic_oilPercent "Oil tank percent
0xFF: SENSOR_FAULT_OIL";
CM_ SG_ 1170 ic_tripmeterA "IC tripmeter A.";
CM_ SG_ 1170 ic_maintenanceInd "Maintenance indication.";
CM_ SG_ 1170 ic_tripmeterB "IC tripmeter B.";
CM_ SG_ 1170 IC_ChargingPower "充电功率";
CM_ SG_ 1170 IC_ChargingSpeed "充电速度";
CM_ SG_ 1173 IVI_FrameType "Frame Type.";
CM_ SG_ 1173 IVI_WorkSts "Work Status.";
CM_ SG_ 1173 IVI_CurrentVideo "Current Video.";
CM_ SG_ 1173 IVI_EventNotify "Event Notify.";
CM_ SG_ 1173 IVI_IC_Sync "IVI and IC synchronization.";
CM_ SG_ 1173 ivi_highwayType "描述车辆是否在高速路上";
CM_ SG_ 1264 IC_TripALastingTime "TripA行驶时间";
CM_ SG_ 1264 IC_TripAAvgSpeed "TripA平均车速";
CM_ SG_ 1264 IC_TripBLastingTime "TripB行驶时间";
CM_ SG_ 1264 IC_TripBAavSpeed "TripB平均车速";
CM_ SG_ 1264 IC_TripBAvgOilConsum "TripB平均油耗";
CM_ SG_ 1264 IC_TripAAvgOilConsum "TripA平均油耗";
CM_ SG_ 1265 IC_SinceChargeAvgSpd "自上次充电平均车速";
CM_ SG_ 1265 IC_SinceChargeTime "自上次充电行驶时间";
CM_ SG_ 1265 IC_SinceChargeAvgOIilConsum "自上次充电平均油耗";
CM_ SG_ 1265 IC_CurrentTripAAvgOilConsum "自启动平均油耗";
CM_ SG_ 1265 IC_CurrentTripAvgSpd "自启动平均车速";
CM_ SG_ 1573 IVI_RMR "Repeat Message Request";
CM_ SG_ 1573 IVI_AWB "Active Wakeup Bit";
CM_ SG_ 1957 Diag_Resp_IVI_Data "Diagnostic Physical response Data from IVI";
CM_ SG_ 774 nvs_Sts "NVS status.";
CM_ SG_ 774 nvs_ocrSts "NVS OCR status.";
CM_ SG_ 774 nvs_displayReq "NVS display request.";
CM_ SG_ 774 nvs_warnningSts "NVS warnning status.";
CM_ SG_ 774 nvs_cameraSts "NVS camera status.";
CM_ SG_ 774 nvs_leltLEDSts "NVS left LED status.";
CM_ SG_ 774 nvs_rightLEDSts "NVS right LED status.";
CM_ SG_ 774 nvs_textPrompt "NVS  text  prompt";
CM_ SG_ 774 nvs_warningType "NVS warnning type";
CM_ SG_ 774 nvs_warningXCoordinate "NVS warning X coordinate.";
CM_ SG_ 774 nvs_warningYCoordinate "NVS warning Y coordinate.";
CM_ SG_ 774 nvs_warningSpeed "nvs_warningSpeed";
CM_ SG_ 774 nvs_warningDistance "nvs_warningDistance";
CM_ SG_ 1978 Diag_Resp_NVS_Data "Diagnostic Physical response Data from NVS";
CM_ SG_ 416 pdc_rearMidleftRegObjSts "Parking Assistantce Rear Middle Left Region Object Status.";
CM_ SG_ 416 pdc_sysSts "PAS System Status.";
CM_ SG_ 416 pdc_failureWarning "PDC failure warning";
CM_ SG_ 416 pdc_rearLeftRegObjSts "Parking Assistantce Rear Left Region Object Status.";
CM_ SG_ 416 pdc_OnOffSts "indicate the PAS switch status.";
CM_ SG_ 416 pdc_frontLeftRegObjSts "Parking Assistantce Front Left Region Object Status.";
CM_ SG_ 416 pdc_audibleFrontBeepRate "audible Beep Rate.";
CM_ SG_ 416 pdc_rearRightRegObjSts "Parking Assistantce Rear Right Region Object Status.";
CM_ SG_ 416 pdc_audibleRearBeepRate "audible Beep Rate.";
CM_ SG_ 416 pdc_frontRightRegObjSts "Parking Assistantce Front Right Region Object Status.";
CM_ SG_ 416 pdc_frontMidLeftRegObjSts "Parking Assistantce Front Middle Left Region Object Status.";
CM_ SG_ 416 pdc_rearMidRightRegObjSts "Parking Assistantce Rear Middle Right Region Object Status.";
CM_ SG_ 416 pdc_frontMidRightRegObjSts "Parking Assistantce Front Middle Right Region Object Status.";
CM_ SG_ 1943 Diag_Resp_PDC_Data "Diagnostic Physical response Data from PDC";
CM_ SG_ 72 Tbox_AuthResponeStatus "Authorities Respone Status.";
CM_ SG_ 72 Tbox_AuthKeyData "Authorities Key Data.";
CM_ SG_ 88 tbox_remoteLockCtrlReq "TBOX remote lock control request.";
CM_ SG_ 88 tbox_remoteCarSearchReq "TBOX remote search car request.";
CM_ SG_ 88 tbox_remoteTailgateCtrlReq "TBOX remote tailgate control request.";
CM_ SG_ 88 tbox_sunroofGlassCmd "TBOX remote sunroof glass control request.";
CM_ SG_ 88 tbox_remoteForbiddenOn "远程禁止上电请求信号";
CM_ SG_ 88 tbox_HornReq "远程开启喇叭请求";
CM_ SG_ 88 tbox_remotePowerCtrlReq "TBOX remote power control request.";
CM_ SG_ 88 tbox_remoteDrSeatHeatReq "TBOX远程请求主驾加热控制请求";
CM_ SG_ 88 tbox_remotePassSeatHeatReq "TBOX远程请求副驾加热控制请求";
CM_ SG_ 88 tbox_HazardLightReq "Hazard Warning lighton off control.";
CM_ SG_ 88 tbox_remoteACOnOffReq "TBOX remote AC on off request.";
CM_ SG_ 88 tbox_remoteInfoCollectionReq "TBOX remote information collection request.";
CM_ SG_ 88 tbox_oneTouchCoolSet "TBOX set AC to cool（一键清凉）";
CM_ SG_ 88 tbox_oneTouchHeatSet "TBOX set AC to heat（一键加热）";
CM_ SG_ 88 tbox_remoteWinLFCtrlRqst "Remote front left window control request.";
CM_ SG_ 88 tbox_remoteWinRFCtrlRqst "Remote front right window control request.";
CM_ SG_ 88 tbox_remoteWinLRCtrlRqst "Remote rear left window control request.";
CM_ SG_ 88 tbox_remoteWinRRCtrlRqst "Remote rear right window control request.";
CM_ SG_ 88 tbox_lowBeamOnOffCtrl "Low beam on off control.";
CM_ SG_ 126 tbox_reservationChargeMode "Reservation charge Mode(预约充电定时方式)";
CM_ SG_ 126 tbox_SysErSt "TBOX系统故障";
CM_ SG_ 126 tbox_chargeSetValid_Reserved "Slow charge set valid signal(Reserved).";
CM_ SG_ 126 tbox_MaxChargeCurrentSet "Maximum Charge Current Set.";
CM_ SG_ 126 tbox_ChargeFormSet "charge form set.";
CM_ SG_ 126 tbox_ChargeEndTimeHalfDay "Charge End Time:Half Day";
CM_ SG_ 126 tbox_ChargeEndTimeHour "Charge End Time:Hour.";
CM_ SG_ 126 tbox_remoteVehicleForbiddenStart "TBOX remote Vehicle Forbidden Start.";
CM_ SG_ 126 tbox_ChargeEndTimeMinute "Charge End Time:Minute";
CM_ SG_ 126 tbox_ChargeCancel "Cancel Charge.";
CM_ SG_ 126 tbox_ChargeEnable "Charge Enable .";
CM_ SG_ 126 tbox_ChargeStartTimeHalfDay "Charge Start Time:Half Day.";
CM_ SG_ 126 tbox_ChargeStartTimeHour "Charge Start Time:Hour.";
CM_ SG_ 126 tbox_EmergencyHvOffReq "Emergency high voltage Off Request.";
CM_ SG_ 126 tbox_ChargeStartTimeMinute "ChargeStartTimeMinute.";
CM_ SG_ 126 tbox_BatteryCondition_Reserved "Battery Condition(Reserved).";
CM_ SG_ 126 tbox_MaxChargeSOCSet "Maximum Charge SOC Set .";
CM_ SG_ 126 tbox_ChargeEndTimeValid "Charge End Time Valid.";
CM_ SG_ 126 tbox_ChargeStartTimeValid "Charge Start Time Valid.";
CM_ SG_ 126 tbox_remoteengStartCmd "允许远程启动发动机";
CM_ SG_ 168 tbox_dvrTakePicCtrl "DVR take picture control.";
CM_ SG_ 1278 tbox_vehicleMode "the signal indicates the current vehicle state to active or dective functions";
CM_ SG_ 1278 TBOX_OTAEnergyCtl "OTA energy control";
CM_ SG_ 1278 TBOX_OTATimeSet "OTA time setting";
CM_ SG_ 1278 tbox_4FE_rollingCounter "every message increments the counter.";
CM_ SG_ 1278 tbox_4FE_checksum "CRC8, message checksum.";
CM_ SG_ 1576 TBOX_RMR "Repeat Message Request";
CM_ SG_ 1576 TBOX_AWB "Active Wakeup Bit";
CM_ SG_ 1793 Diag_PhyReq_BCM_Data "Diagnostic Physical Request Data to BCM";
CM_ SG_ 1796 Diag_PhyReq_POT_Data "Diagnostic Physical Request Data to POT";
CM_ SG_ 1797 Diag_PhyReq_DSCU_Data "Diagnostic Physical Request Data to DSCU";
CM_ SG_ 1806 Diag_PhyReq_GW_Data "Diagnostic Physical Request Data to GW";
CM_ SG_ 1817 Diag_PhyReq_SWM_Data "Diagnostic Physical Request Data to SWM";
CM_ SG_ 1824 Diag_PhyReq_HCMR_Data "Diagnostic Physical Request Data to HCMR";
CM_ SG_ 1825 Diag_PhyReq_HCML_Data "Diagnostic Physical Request Data to HCML";
CM_ SG_ 1826 Diag_PhyReq_ESC_Data "Diagnostic Physical Request Data to ESC";
CM_ SG_ 1828 Diag_PhyReq_AVM_Data "Diagnostic Physical Request Data to AVM";
CM_ SG_ 1830 Diag_PhyReq_AC_Data "Diagnostic Physical Request Data to AC";
CM_ SG_ 1831 Diag_PhyReq_ASC_Data "Diagnostic Physical Request Data to ASC";
CM_ SG_ 1833 Diag_PhyReq_GSM_Data "Diagnostic physical request data to GSM";
CM_ SG_ 1834 Diag_PhyReq_MPC_Data "Diagnostic Physical Request Data to MPC";
CM_ SG_ 1835 Diag_PhyReq_MRR_R1_Data "Diagnostic Physical Request Data to MRR_R1";
CM_ SG_ 1836 Diag_PhyReq_MRR_R2_Data "Diagnostic Physical Request Data to MRR_R2";
CM_ SG_ 1841 Diag_PhyReq_VCU_Data "Diagnostic physical request data to VCU";
CM_ SG_ 1842 Diag_PhyReq_MCUR0_Data "Diagnostic physical request data  to MCUR0";
CM_ SG_ 1843 Diag_PhyReq_MCUF0_Data "Diagnostic physical request data to MCUF0";
CM_ SG_ 1844 Diag_PhyReq_BMS_Data "Diagnostic physical request data to BMS";
CM_ SG_ 1845 Diag_PhyReq_iB_Data "Diagnostic Physical Request Data to iBooster";
CM_ SG_ 1847 Diag_PhyReq_OBCM_Data "Diagnostic physical request data to OBCM";
CM_ SG_ 1849 Diag_PhyReq_MRR_Data "Diagnostic Physical Request Data to MRR";
CM_ SG_ 1851 Diag_PhyReq_BLE_Data "Diagnostic Physical Request Data to BLE";
CM_ SG_ 1852 Diag_PhyReq_GCU_Data "Diagnostic physical request data to GCU";
CM_ SG_ 1859 Diag_PhyReq_APA_Data "Diagnostic Physical Request Data to APA";
CM_ SG_ 1860 Diag_PhyReq_EPS_Data "Diagnostic Physical Request Data to EPS";
CM_ SG_ 1866 Diag_PhyReq_HANDLE_LF_Data "Diagnostic Physical Request Data to HANDLE_LF";
CM_ SG_ 1867 Diag_PhyReq_HANDLE_RF_Data "Diagnostic Physical Request Data to HANDLE_RF";
CM_ SG_ 1868 Diag_PhyReq_HANDLE_LR_Data "Diagnostic Physical Request Data to HANDLE_LR";
CM_ SG_ 1869 Diag_PhyReq_HANDLE_RR_Data "Diagnostic Physical Request Data to HANDLE_RR";
CM_ SG_ 1960 Diag_Resp_TBOX_Data "Diagnostic Physical response Data from TBOX";
CM_ SG_ 2016 Diag_PhyReq_ECU_Data "Diagnostic physical request data to ECU";
CM_ SG_ 2018 OBD_PhyReq_BMS_Data "Diagnostic physical request data to BMS";
CM_ SG_ 2019 OBD_PhyReq_GCU_Data "Diagnostic physical request data to GCU";
CM_ SG_ 2020 OBD_PhyReq_OBCM_Data "Diagnostic physical request data to OBCM";
CM_ SG_ 2021 OBD_PhyReq_iBooster_Data "Diagnostic physical request data to iBooster";
CM_ SG_ 2022 OBD_PhyReq_ESC_Data "Diagnostic physical request data to ESC";
CM_ SG_ 2023 OBD_PhyReq_VCU_Data "Diagnostic physical request data to VCU";
CM_ SG_ 2033 Diag_PhyReq_ACU_Data "Diagnostic Physical Request Data to ACU";
CM_ SG_ 928 vsp_soundEnable "Sound enable or disable.";
CM_ SG_ 928 vsp_errorIdentification "Show sound error.";
CM_ SG_ 1936 Diag_Resp_VSP_Data "Diagnostic Physical response Data from VSP";
CM_ SG_ 941 wcm_chargingSts "Charging status.";
CM_ SG_ 941 wcm_failureSts "WCM failure status.";
CM_ SG_ 941 wcm_workingSts "WCM working status.";
CM_ SG_ 941 wcm_reminder "Phone left in car warning";
CM_ SG_ 1933 Diag_Resp_WCM_Data "Diagnostic Physical response Data from WCM";
CM_ SG_ 1140 bms_vLimitCharge "OBC maximum charge voltage allowed by BMS.";
CM_ SG_ 1140 bms_iLimitCharge "OBC maximum charge current allowed by BMS.";
CM_ SG_ 1140 bms_vSetCvMode "OBC charge voltage set by BMS.";
CM_ SG_ 1140 bms_iSetCcMode "OBC charge current set by BMS.";
CM_ SG_ 1140 bms_obcChargeMode "OBC  charge mode.";
CM_ SG_ 1444 vcu_HVPTC_InternalWaterTemp2 "HV_PTC Duty Cycle Actual
PTC占空比";
CM_ SG_ 1444 vcu_VALVE3_DATA1 "The specified opening data the master has requested
开度位置设定";
CM_ SG_ 1444 vcu_VALVE4_DATA1 "The specified opening data the master has requested
开度位置设定";
CM_ SG_ 1444 vcu_battCoolantPump1Spd "Battery coolant pump1 speed
电池水泵1占空比";
CM_ SG_ 1444 vcu_battCoolantPump2Spd "Battery coolant pump2 speed
电池水泵2占空比";
CM_ SG_ 1444 vcu_driveUnitCoolantPump1Spd "Drive unit coolant pump1 speed
电驱水泵1占空比";
CM_ SG_ 1444 vcu_driveUnitCoolantPump2Spd "Drive unit coolant pump2 speed
电驱水泵2占空比";
CM_ SG_ 1445 vcu_HVPTC_HV_DC_curr "Current Draw of HV-PTC";
CM_ SG_ 1445 vcu_HVPTC_HV_voltage "High Voltage Measurement";
CM_ SG_ 787 mcuf0_tempCltInlet "Rear MCU0 inlet coolant temperature.";
CM_ SG_ 787 mcuf0_hwDtcRecordFlag "硬件故障DTC记录标志位";
CM_ SG_ 787 mcuf0_pcbTemp "Rear MCU0 PCB temperature.";
CM_ SG_ 786 mcur0_tempCltInlet "Rear MCU0 inlet coolant temperature";
CM_ SG_ 786 mcur0_hwDtcRecordFlag "硬件故障DTC记录标志位";
CM_ SG_ 786 mcur0_pcbTemp "Rear MCU0 PCB temperature";
BA_DEF_ BO_  "NmMessage" ENUM  "No","Yes";
BA_DEF_ BO_  "DiagState" ENUM  "No","Yes";
BA_DEF_ BO_  "GenMsgSendType" ENUM  "Cyclic","Event","IfActive","CE","CA","NoMsgSendType";
BA_DEF_ BO_  "GenMsgCycleTime" INT 0 0;
BA_DEF_ SG_  "GenSigSendType" ENUM  "Cyclic","OnChange","OnWrite","IfActive","OnChangeWithRepetition","OnWriteWithRepetition","IfActiveWithRepetition","NoSigSendType","OnChangeAndIfActive","OnChangeAndIfActiveWithRepetition","CA","CE","Event";
BA_DEF_ SG_  "GenSigStartValue" INT 0 0;
BA_DEF_ SG_  "GenSigInactiveValue" INT 0 0;
BA_DEF_ BO_  "GenMsgCycleTimeFast" INT 0 0;
BA_DEF_ BO_  "GenMsgNrOfRepetition" INT 0 0;
BA_DEF_DEF_  "NmMessage" "No";
BA_DEF_DEF_  "DiagState" "No";
BA_DEF_DEF_  "GenMsgSendType" "Cyclic";
BA_DEF_DEF_  "GenMsgCycleTime" 0;
BA_DEF_DEF_  "GenSigSendType" "Cyclic";
BA_DEF_DEF_  "GenSigStartValue" 0;
BA_DEF_DEF_  "GenSigInactiveValue" 0;
BA_DEF_DEF_  "GenMsgCycleTimeFast" 0;
BA_DEF_DEF_  "GenMsgNrOfRepetition" 0;
BA_ "GenMsgSendType" BO_ 1924 1;
BA_ "GenMsgSendType" BO_ 1925 1;
BA_ "GenMsgSendType" BO_ 1934 1;
BA_ "GenMsgSendType" BO_ 1945 1;
BA_ "GenMsgSendType" BO_ 1952 1;
BA_ "GenMsgSendType" BO_ 1953 1;
BA_ "GenMsgSendType" BO_ 1954 1;
BA_ "GenMsgSendType" BO_ 1956 1;
BA_ "GenMsgSendType" BO_ 1958 1;
BA_ "GenMsgSendType" BO_ 1959 1;
BA_ "GenMsgSendType" BO_ 1961 1;
BA_ "GenMsgSendType" BO_ 1962 1;
BA_ "GenMsgSendType" BO_ 1963 1;
BA_ "GenMsgSendType" BO_ 1964 1;
BA_ "GenMsgSendType" BO_ 1969 1;
BA_ "GenMsgSendType" BO_ 1970 1;
BA_ "GenMsgSendType" BO_ 1971 1;
BA_ "GenMsgSendType" BO_ 1972 1;
BA_ "GenMsgSendType" BO_ 1973 1;
BA_ "GenMsgSendType" BO_ 1975 1;
BA_ "GenMsgSendType" BO_ 1977 1;
BA_ "GenMsgSendType" BO_ 1979 1;
BA_ "GenMsgSendType" BO_ 1980 1;
BA_ "GenMsgSendType" BO_ 1987 1;
BA_ "GenMsgSendType" BO_ 1988 1;
BA_ "GenMsgSendType" BO_ 1994 1;
BA_ "GenMsgSendType" BO_ 1995 1;
BA_ "GenMsgSendType" BO_ 1996 1;
BA_ "GenMsgSendType" BO_ 1997 1;
BA_ "GenMsgSendType" BO_ 2015 1;
BA_ "DiagState" BO_ 2015 1;
BA_ "GenMsgSendType" BO_ 2024 1;
BA_ "GenMsgSendType" BO_ 2026 1;
BA_ "GenMsgSendType" BO_ 2027 1;
BA_ "GenMsgSendType" BO_ 2028 1;
BA_ "GenMsgSendType" BO_ 2029 1;
BA_ "GenMsgSendType" BO_ 2030 1;
BA_ "GenMsgSendType" BO_ 2031 1;
BA_ "GenMsgSendType" BO_ 2041 1;
BA_ "GenMsgCycleTime" BO_ 937 100;
BA_ "GenMsgCycleTime" BO_ 939 100;
BA_ "GenMsgSendType" BO_ 1545 1;
BA_ "NmMessage" BO_ 1545 1;
BA_ "GenMsgSendType" BO_ 1929 1;
BA_ "GenMsgCycleTime" BO_ 82 100;
BA_ "GenMsgCycleTime" BO_ 117 100;
BA_ "GenMsgCycleTime" BO_ 133 100;
BA_ "GenMsgNrOfRepetition" BO_ 149 5;
BA_ "GenMsgCycleTimeFast" BO_ 149 100;
BA_ "GenMsgCycleTime" BO_ 149 100;
BA_ "GenMsgSendType" BO_ 149 3;
BA_ "GenMsgNrOfRepetition" BO_ 165 3;
BA_ "GenMsgCycleTimeFast" BO_ 165 20;
BA_ "GenMsgCycleTime" BO_ 165 100;
BA_ "GenMsgSendType" BO_ 165 3;
BA_ "GenMsgNrOfRepetition" BO_ 197 3;
BA_ "GenMsgCycleTimeFast" BO_ 197 20;
BA_ "GenMsgCycleTime" BO_ 197 100;
BA_ "GenMsgSendType" BO_ 197 3;
BA_ "GenMsgNrOfRepetition" BO_ 245 3;
BA_ "GenMsgCycleTimeFast" BO_ 245 20;
BA_ "GenMsgCycleTime" BO_ 245 100;
BA_ "GenMsgSendType" BO_ 245 3;
BA_ "GenMsgNrOfRepetition" BO_ 261 3;
BA_ "GenMsgCycleTimeFast" BO_ 261 20;
BA_ "GenMsgCycleTime" BO_ 261 100;
BA_ "GenMsgSendType" BO_ 261 3;
BA_ "GenMsgNrOfRepetition" BO_ 270 3;
BA_ "GenMsgCycleTimeFast" BO_ 270 20;
BA_ "GenMsgCycleTime" BO_ 270 100;
BA_ "GenMsgSendType" BO_ 270 3;
BA_ "GenMsgNrOfRepetition" BO_ 286 3;
BA_ "GenMsgCycleTimeFast" BO_ 286 20;
BA_ "GenMsgCycleTime" BO_ 286 100;
BA_ "GenMsgSendType" BO_ 286 3;
BA_ "GenMsgNrOfRepetition" BO_ 446 3;
BA_ "GenMsgCycleTimeFast" BO_ 446 100;
BA_ "GenMsgCycleTime" BO_ 446 100;
BA_ "GenMsgSendType" BO_ 446 3;
BA_ "GenMsgCycleTime" BO_ 469 100;
BA_ "GenMsgNrOfRepetition" BO_ 497 3;
BA_ "GenMsgCycleTimeFast" BO_ 497 20;
BA_ "GenMsgCycleTime" BO_ 497 100;
BA_ "GenMsgSendType" BO_ 497 3;
BA_ "GenMsgCycleTime" BO_ 766 20;
BA_ "GenMsgSendType" BO_ 849 1;
BA_ "GenMsgSendType" BO_ 850 1;
BA_ "GenMsgSendType" BO_ 851 1;
BA_ "GenMsgNrOfRepetition" BO_ 949 3;
BA_ "GenMsgCycleTimeFast" BO_ 949 100;
BA_ "GenMsgCycleTime" BO_ 949 100;
BA_ "GenMsgSendType" BO_ 949 3;
BA_ "GenMsgCycleTime" BO_ 1011 1000;
BA_ "GenMsgCycleTime" BO_ 1248 1000;
BA_ "GenMsgCycleTime" BO_ 1013 1000;
BA_ "GenMsgCycleTime" BO_ 1022 100;
BA_ "GenMsgCycleTime" BO_ 1154 500;
BA_ "GenMsgCycleTime" BO_ 1170 500;
BA_ "GenMsgNrOfRepetition" BO_ 1173 3;
BA_ "GenMsgCycleTimeFast" BO_ 1173 20;
BA_ "GenMsgCycleTime" BO_ 1173 500;
BA_ "GenMsgSendType" BO_ 1173 3;
BA_ "GenMsgCycleTime" BO_ 1264 1000;
BA_ "GenMsgCycleTime" BO_ 1265 1000;
BA_ "GenMsgSendType" BO_ 1573 1;
BA_ "NmMessage" BO_ 1573 1;
BA_ "GenMsgSendType" BO_ 1957 1;
BA_ "GenMsgCycleTime" BO_ 774 100;
BA_ "GenMsgSendType" BO_ 1978 1;
BA_ "GenMsgCycleTime" BO_ 416 50;
BA_ "GenMsgSendType" BO_ 1943 1;
BA_ "GenMsgSendType" BO_ 72 1;
BA_ "GenMsgSendType" BO_ 88 1;
BA_ "GenMsgCycleTime" BO_ 126 100;
BA_ "GenMsgSendType" BO_ 168 1;
BA_ "GenMsgCycleTime" BO_ 1278 1000;
BA_ "GenMsgSendType" BO_ 1576 1;
BA_ "NmMessage" BO_ 1576 1;
BA_ "GenMsgSendType" BO_ 1793 1;
BA_ "GenMsgSendType" BO_ 1796 1;
BA_ "GenMsgSendType" BO_ 1797 1;
BA_ "GenMsgSendType" BO_ 1806 1;
BA_ "GenMsgSendType" BO_ 1817 1;
BA_ "GenMsgSendType" BO_ 1824 1;
BA_ "GenMsgSendType" BO_ 1825 1;
BA_ "GenMsgSendType" BO_ 1826 1;
BA_ "GenMsgSendType" BO_ 1828 1;
BA_ "GenMsgSendType" BO_ 1830 1;
BA_ "GenMsgSendType" BO_ 1831 1;
BA_ "GenMsgSendType" BO_ 1833 1;
BA_ "GenMsgSendType" BO_ 1834 1;
BA_ "GenMsgSendType" BO_ 1835 1;
BA_ "GenMsgSendType" BO_ 1836 1;
BA_ "GenMsgSendType" BO_ 1841 1;
BA_ "GenMsgSendType" BO_ 1842 1;
BA_ "GenMsgSendType" BO_ 1843 1;
BA_ "GenMsgSendType" BO_ 1844 1;
BA_ "GenMsgSendType" BO_ 1845 1;
BA_ "GenMsgSendType" BO_ 1847 1;
BA_ "GenMsgSendType" BO_ 1849 1;
BA_ "GenMsgSendType" BO_ 1851 1;
BA_ "GenMsgSendType" BO_ 1852 1;
BA_ "GenMsgSendType" BO_ 1859 1;
BA_ "GenMsgSendType" BO_ 1860 1;
BA_ "GenMsgSendType" BO_ 1866 1;
BA_ "GenMsgSendType" BO_ 1867 1;
BA_ "GenMsgSendType" BO_ 1868 1;
BA_ "GenMsgSendType" BO_ 1869 1;
BA_ "GenMsgSendType" BO_ 1960 1;
BA_ "GenMsgSendType" BO_ 2016 1;
BA_ "GenMsgSendType" BO_ 2018 1;
BA_ "GenMsgSendType" BO_ 2019 1;
BA_ "GenMsgSendType" BO_ 2020 1;
BA_ "GenMsgSendType" BO_ 2021 1;
BA_ "GenMsgSendType" BO_ 2022 1;
BA_ "GenMsgSendType" BO_ 2023 1;
BA_ "GenMsgSendType" BO_ 2033 1;
BA_ "GenMsgCycleTime" BO_ 928 100;
BA_ "GenMsgSendType" BO_ 1936 1;
BA_ "GenMsgCycleTime" BO_ 941 100;
BA_ "GenMsgSendType" BO_ 1933 1;
BA_ "GenMsgCycleTime" BO_ 1140 200;
BA_ "GenMsgCycleTime" BO_ 1444 500;
BA_ "GenMsgCycleTime" BO_ 1445 500;
BA_ "GenMsgCycleTime" BO_ 787 100;
BA_ "GenMsgCycleTime" BO_ 786 100;
BA_ "GenSigSendType" SG_ 1924 Diag_Resp_POT_Data 2;
BA_ "GenSigSendType" SG_ 1925 Diag_Resp_DSCU_Data 2;
BA_ "GenSigSendType" SG_ 1934 Diag_Resp_GW_Data 2;
BA_ "GenSigSendType" SG_ 1945 Diag_Resp_SWM_Data 2;
BA_ "GenSigSendType" SG_ 1952 Diag_Resp_HCMR_Data 2;
BA_ "GenSigSendType" SG_ 1953 Diag_Resp_HCML_Data 2;
BA_ "GenSigSendType" SG_ 1954 Diag_Resp_ESC_Data 2;
BA_ "GenSigSendType" SG_ 1956 Diag_Resp_AVM_Data 2;
BA_ "GenSigSendType" SG_ 1958 Diag_Resp_AC_Data 2;
BA_ "GenSigSendType" SG_ 1959 Diag_Resp_ASC_Data 2;
BA_ "GenSigSendType" SG_ 1961 Diag_Resp_GSM_Data 2;
BA_ "GenSigSendType" SG_ 1962 Diag_Resp_MPC_Data 2;
BA_ "GenSigSendType" SG_ 1963 Diag_Resp_MRR_R1_Data 2;
BA_ "GenSigSendType" SG_ 1964 Diag_Resp_MRR_R2_Data 2;
BA_ "GenSigSendType" SG_ 1969 Diag_Resp_VCU_Data 2;
BA_ "GenSigSendType" SG_ 1970 Diag_Resp_MCUR0_Data 2;
BA_ "GenSigSendType" SG_ 1971 Diag_Resp_MCUF0_Data 2;
BA_ "GenSigSendType" SG_ 1972 Diag_Resp_BMS_Data 2;
BA_ "GenSigSendType" SG_ 1973 Diag_Resp_iB_Data 2;
BA_ "GenSigSendType" SG_ 1975 Diag_Resp_OBCM_Data 2;
BA_ "GenSigSendType" SG_ 1977 Diag_Resp_MRR_Data 2;
BA_ "GenSigSendType" SG_ 1979 Diag_Resp_BLE_Data 2;
BA_ "GenSigSendType" SG_ 1980 Diag_Resp_GCU_Data 2;
BA_ "GenSigSendType" SG_ 1987 Diag_Resp_APA_Data 2;
BA_ "GenSigSendType" SG_ 1988 Diag_Resp_EPS_Data 2;
BA_ "GenSigSendType" SG_ 1994 Diag_Resp_HANDLE_LF_Data 2;
BA_ "GenSigSendType" SG_ 1995 Diag_Resp_HANDLE_RF_Data 2;
BA_ "GenSigSendType" SG_ 1996 Diag_Resp_HANDLE_LR_Data 2;
BA_ "GenSigSendType" SG_ 1997 Diag_Resp_HANDLE_RR_Data 2;
BA_ "GenSigSendType" SG_ 2015 Diag_FuncReq_Data 2;
BA_ "GenSigSendType" SG_ 2024 Diag_Resp_ECU_Data 2;
BA_ "GenSigSendType" SG_ 2026 OBD_Resp_BMS_Data 2;
BA_ "GenSigSendType" SG_ 2027 OBD_Resp_GCU_Data 2;
BA_ "GenSigSendType" SG_ 2028 OBD_Resp_OBCM_Data 2;
BA_ "GenSigSendType" SG_ 2029 OBD_Resp_iBooster_Data 2;
BA_ "GenSigSendType" SG_ 2030 OBD_Resp_ESC_Data 2;
BA_ "GenSigSendType" SG_ 2031 OBD_Resp_VCU_Data 2;
BA_ "GenSigSendType" SG_ 2041 Diag_Resp_ACU_Data 2;
BA_ "GenSigInactiveValue" SG_ 937 icm_dmsGestureID 15;
BA_ "GenSigSendType" SG_ 1545 ICM_RMR 2;
BA_ "GenSigSendType" SG_ 1545 ICM_AWB 2;
BA_ "GenSigSendType" SG_ 1929 Diag_Resp_ICM_Data 2;
BA_ "GenSigStartValue" SG_ 117 ivi_antiTheftAlarmFormSet 3;
BA_ "GenSigSendType" SG_ 117 IVI_SOCmodeSet 4;
BA_ "GenSigSendType" SG_ 149 ivi_ambientLightOnOffSet 4;
BA_ "GenSigSendType" SG_ 149 ivi_sunroofRollshadeCtrlSelect 4;
BA_ "GenSigSendType" SG_ 149 ivi_ambientLightColorSet 4;
BA_ "GenSigSendType" SG_ 149 ivi_ambientLightLumiLvSet 4;
BA_ "GenSigInactiveValue" SG_ 149 ivi_screenAutoLiftCtrl 2;
BA_ "GenSigSendType" SG_ 149 ivi_doorTopSW 4;
BA_ "GenSigSendType" SG_ 149 ivi_parkAutoCloseDRLCtrl 4;
BA_ "GenSigSendType" SG_ 149 ivi_followMeHomeSet 4;
BA_ "GenSigSendType" SG_ 149 ivi_WheelAlignmentCtrl 4;
BA_ "GenSigSendType" SG_ 149 ivi_WinLFCtrlRqst 4;
BA_ "GenSigSendType" SG_ 149 ivi_WinRFCtrlRqst 4;
BA_ "GenSigSendType" SG_ 149 ivi_WinLRCtrlRqst 4;
BA_ "GenSigSendType" SG_ 149 ivi_WinRRCtrlRqst 4;
BA_ "GenSigSendType" SG_ 149 IVI_DGSW 4;
BA_ "GenSigSendType" SG_ 149 IVI_DGPercentCtrl 4;
BA_ "GenSigSendType" SG_ 149 IVI_speedautolockonoffSet 4;
BA_ "GenSigSendType" SG_ 149 ivi_adbOnOffSet 4;
BA_ "GenSigSendType" SG_ 149 ivi_hcmHeightSet 4;
BA_ "GenSigSendType" SG_ 165 ivi_4wdModeSet 4;
BA_ "GenSigSendType" SG_ 165 ivi_ChargeCancel 4;
BA_ "GenSigSendType" SG_ 165 ivi_RegenModeSet 4;
BA_ "GenSigSendType" SG_ 165 ivi_maxChargeCurrentSet 4;
BA_ "GenSigSendType" SG_ 165 ivi_TowModeSet 4;
BA_ "GenSigSendType" SG_ 165 ivi_maxChrgSocSet 4;
BA_ "GenSigSendType" SG_ 165 ivi_chargeFormSet 4;
BA_ "GenSigSendType" SG_ 165 ivi_ChargeEnable 4;
BA_ "GenSigSendType" SG_ 165 ivi_highwayModeRequest 4;
BA_ "GenSigSendType" SG_ 165 ivi_chargeSetValid 4;
BA_ "GenSigSendType" SG_ 165 ivi_ChargeEndTimeHour 4;
BA_ "GenSigSendType" SG_ 165 ivi_ChargeStartTimeHour 4;
BA_ "GenSigSendType" SG_ 165 ivi_ChargeEndTimeHalfDay 4;
BA_ "GenSigSendType" SG_ 165 ivi_ChargeStartTimeHalfDay 4;
BA_ "GenSigStartValue" SG_ 165 ivi_ChargeEndTimeMinute 63;
BA_ "GenSigSendType" SG_ 165 ivi_ChargeEndTimeMinute 4;
BA_ "GenSigStartValue" SG_ 165 ivi_ChargeStartTimeMinute 63;
BA_ "GenSigSendType" SG_ 165 ivi_ChargeStartTimeMinute 4;
BA_ "GenSigSendType" SG_ 165 ivi_ResetCurrentTrip 4;
BA_ "GenSigSendType" SG_ 165 ivi_BCMEBSHvoffset 4;
BA_ "GenSigSendType" SG_ 165 ivi_ChargeEndTimeValid 4;
BA_ "GenSigSendType" SG_ 165 ivi_ChargeStartTimeValid 4;
BA_ "GenSigSendType" SG_ 165 ivi_driveModeSet 4;
BA_ "GenSigSendType" SG_ 197 ivi_reservationChargeModeSet 4;
BA_ "GenSigSendType" SG_ 197 ivi_wcmOnOffSet 4;
BA_ "GenSigSendType" SG_ 197 ivi_vspOnOffSet 4;
BA_ "GenSigStartValue" SG_ 197 ivi_weightlowFrqSet 1;
BA_ "GenSigSendType" SG_ 197 ivi_weightlowFrqSet 4;
BA_ "GenSigSendType" SG_ 197 ivi_etcBTReq 4;
BA_ "GenSigSendType" SG_ 245 ivi_autoEasyEntrySet 4;
BA_ "GenSigSendType" SG_ 245 ivi_drSeatHeatOnOffSet 4;
BA_ "GenSigSendType" SG_ 245 ivi_drSeatVentOnOffSet 4;
BA_ "GenSigSendType" SG_ 245 ivi_drSeatMassOnOffSet 4;
BA_ "GenSigSendType" SG_ 245 ivi_drSeatHeatLevelSet 4;
BA_ "GenSigSendType" SG_ 245 ivi_drSeatVentLevelSet 4;
BA_ "GenSigSendType" SG_ 245 ivi_passSeatHeatOnOffSet 4;
BA_ "GenSigSendType" SG_ 245 ivi_passSeatVentOnOffSet 4;
BA_ "GenSigSendType" SG_ 245 ivi_passSeatHeatLevelSet 4;
BA_ "GenSigSendType" SG_ 245 ivi_passSeatVentLevelSet 4;
BA_ "GenSigSendType" SG_ 245 ivi_passSeatMassOnOffSet 4;
BA_ "GenSigSendType" SG_ 245 ivi_drSeatMassLevelSet 4;
BA_ "GenSigSendType" SG_ 245 ivi_passSeatMassLevelSet 4;
BA_ "GenSigSendType" SG_ 245 ivi_MirrorAutoFoldUnfoldSet 4;
BA_ "GenSigSendType" SG_ 245 ivi_easyEntrySet 4;
BA_ "GenSigSendType" SG_ 245 ivi_dsmSetMemoryReq 4;
BA_ "GenSigSendType" SG_ 245 ivi_dsmGetMemoryReq 4;
BA_ "GenSigSendType" SG_ 245 ivi_rvMirrorAutoTurnDownSet 4;
BA_ "GenSigSendType" SG_ 245 ivi_DrMassgIntenSet 4;
BA_ "GenSigSendType" SG_ 245 ivi_PsgMassgIntenSet 4;
BA_ "GenSigSendType" SG_ 245 ivi_manualEasyOutSw 4;
BA_ "GenSigSendType" SG_ 245 ivi_potPositionStsSet 4;
BA_ "GenSigSendType" SG_ 245 ivi_welcomeSetEnable 4;
BA_ "GenSigSendType" SG_ 261 ivi_dvrDisplayReq 4;
BA_ "GenSigSendType" SG_ 261 ivi_dvrCoTouchMotion 4;
BA_ "GenSigSendType" SG_ 261 ivi_dvrXCoordinate 4;
BA_ "GenSigSendType" SG_ 261 ivi_dvrYCoordinate 4;
BA_ "GenSigSendType" SG_ 261 ivi_roaDisplayReq 4;
BA_ "GenSigSendType" SG_ 261 ivi_ICMpressphtoresp 4;
BA_ "GenSigSendType" SG_ 261 ivi_dmsWearyAssisSet 4;
BA_ "GenSigSendType" SG_ 261 ivi_dmsCameraCtl 4;
BA_ "GenSigSendType" SG_ 261 ivi_dmsWearySet 4;
BA_ "GenSigStartValue" SG_ 261 ivi_dmsSenSet 3;
BA_ "GenSigSendType" SG_ 261 ivi_dmsSenSet 4;
BA_ "GenSigSendType" SG_ 261 ivi_ICMBeautySet 4;
BA_ "GenSigSendType" SG_ 261 ivi_cameraChange 4;
BA_ "GenSigSendType" SG_ 261 ivi_videoCallSts 4;
BA_ "GenSigSendType" SG_ 261 ivi_nvsDisplay 4;
BA_ "GenSigSendType" SG_ 261 ivi_nvsOCRPress 4;
BA_ "GenSigSendType" SG_ 261 ivi_ArdisplayReq 4;
BA_ "GenSigSendType" SG_ 261 ivi_dvrPhotoReceive 4;
BA_ "GenSigSendType" SG_ 261 ivi_dvrVideoReceive 4;
BA_ "GenSigSendType" SG_ 261 ivi_roaCameraCtl 4;
BA_ "GenSigSendType" SG_ 261 ivi_tspUploadSts 4;
BA_ "GenSigSendType" SG_ 270 ivi_AVMTrigByTurnningSts 4;
BA_ "GenSigSendType" SG_ 270 ivi_AVMViewModeSw 4;
BA_ "GenSigSendType" SG_ 270 ivi_modeSw 4;
BA_ "GenSigSendType" SG_ 270 ivi_viewSw_Reserved 4;
BA_ "GenSigSendType" SG_ 270 ivi_screenCoordX 4;
BA_ "GenSigSendType" SG_ 270 ivi_screenCoordY 4;
BA_ "GenSigSendType" SG_ 270 ivi_avm_monVideoReceive 4;
BA_ "GenSigSendType" SG_ 270 ivi_MODSw 4;
BA_ "GenSigSendType" SG_ 270 ivi_AVMTrajectorySW 4;
BA_ "GenSigSendType" SG_ 270 ivi_AVMAutoswitchingSW 4;
BA_ "GenSigSendType" SG_ 270 ivi_AVM_transparentSW 4;
BA_ "GenSigSendType" SG_ 270 ivi_View_select 4;
BA_ "GenSigSendType" SG_ 270 IVI_Voice_AVMOnOffReq 4;
BA_ "GenSigSendType" SG_ 270 ivi_touchScreenCtrl 4;
BA_ "GenSigSendType" SG_ 270 ivi_naviSts 4;
BA_ "GenSigSendType" SG_ 270 IVI_Voice_APAOnOffReq 4;
BA_ "GenSigSendType" SG_ 270 IVI_Voice_CarbodyTransparentReq 4;
BA_ "GenSigStartValue" SG_ 286 ivi_vehicleSpeedCompModeReq 3;
BA_ "GenSigSendType" SG_ 286 ivi_vehicleSpeedCompModeReq 4;
BA_ "GenSigStartValue" SG_ 286 ivi_highFrqSet 1;
BA_ "GenSigSendType" SG_ 286 ivi_highFrqSet 4;
BA_ "GenSigStartValue" SG_ 286 ivi_mediaVolSet 63;
BA_ "GenSigSendType" SG_ 286 ivi_mediaVolSet 4;
BA_ "GenSigStartValue" SG_ 286 ivi_muteAllSpeakers 3;
BA_ "GenSigSendType" SG_ 286 ivi_muteAllSpeakers 4;
BA_ "GenSigStartValue" SG_ 286 ivi_midFrqSet 31;
BA_ "GenSigSendType" SG_ 286 ivi_midFrqSet 4;
BA_ "GenSigStartValue" SG_ 286 ivi_lowFrqSet 1;
BA_ "GenSigSendType" SG_ 286 ivi_lowFrqSet 4;
BA_ "GenSigStartValue" SG_ 286 ivi_amp_dyaudioSoundFeature 7;
BA_ "GenSigSendType" SG_ 286 ivi_amp_dyaudioSoundFeature 4;
BA_ "GenSigStartValue" SG_ 286 ivi_loudnessOnOffSet 3;
BA_ "GenSigSendType" SG_ 286 ivi_loudnessOnOffSet 4;
BA_ "GenSigStartValue" SG_ 286 ivi_soundFieldSet 7;
BA_ "GenSigSendType" SG_ 286 ivi_soundFieldSet 4;
BA_ "GenSigStartValue" SG_ 286 ivi_audioBlcSet 31;
BA_ "GenSigSendType" SG_ 286 ivi_audioBlcSet 4;
BA_ "GenSigStartValue" SG_ 286 ivi_audioFaderSet 31;
BA_ "GenSigSendType" SG_ 286 ivi_audioFaderSet 4;
BA_ "GenSigStartValue" SG_ 446 ivi_epsModeSet 2;
BA_ "GenSigSendType" SG_ 446 ivi_escOffSw 4;
BA_ "GenSigSendType" SG_ 446 ivi_hdcOnOffSet 4;
BA_ "GenSigSendType" SG_ 446 ivi_aebOnOffSet 4;
BA_ "GenSigSendType" SG_ 446 ivi_iBModeSet 4;
BA_ "GenSigSendType" SG_ 446 ivi_lksSensitivitySet 4;
BA_ "GenSigSendType" SG_ 446 ivi_lcaBsdOnOffSet 4;
BA_ "GenSigSendType" SG_ 446 ivi_rctaOnOffSet 4;
BA_ "GenSigSendType" SG_ 446 ivi_dowOnOffSet 4;
BA_ "GenSigSendType" SG_ 446 ivi_startRevSOCSet 4;
BA_ "GenSigSendType" SG_ 446 ivi_speedLimitWarningMode 4;
BA_ "GenSigSendType" SG_ 446 ivi_ISAOnOffSet 4;
BA_ "GenSigSendType" SG_ 446 ivi_currentRoadType 4;
BA_ "GenSigStartValue" SG_ 446 ivi_countryCodeSet 44;
BA_ "GenSigSendType" SG_ 446 ivi_countryCodeSet 4;
BA_ "GenSigSendType" SG_ 446 ivi_FrtVehStrReminderSw 4;
BA_ "GenSigSendType" SG_ 446 ivi_speedLimitUnitSet 4;
BA_ "GenSigSendType" SG_ 446 ivi_speedLimitStsSet 4;
BA_ "GenSigSendType" SG_ 446 ivi_propModeSet 4;
BA_ "GenSigSendType" SG_ 446 ivi_pcwOnOffSet 4;
BA_ "GenSigSendType" SG_ 446 ivi_torqueDistModeSet 4;
BA_ "GenSigSendType" SG_ 446 ivi_rcwOnOffSet 4;
BA_ "GenSigSendType" SG_ 446 ivi_trailerModeOnOffSet 4;
BA_ "GenSigSendType" SG_ 446 ivi_esc_epbButtonRelease 4;
BA_ "GenSigSendType" SG_ 497 ivi_faceIDSet 4;
BA_ "GenSigSendType" SG_ 497 ivi_gestureIDSet 4;
BA_ "GenSigSendType" SG_ 497 ivi_dmsFaceIDRegiReq 4;
BA_ "GenSigSendType" SG_ 497 ivi_FaceIDLoginReq 4;
BA_ "GenSigSendType" SG_ 497 ivi_dmsRegiFaceID 4;
BA_ "GenSigSendType" SG_ 497 ivi_dmsDeleteFaceID 4;
BA_ "GenSigSendType" SG_ 497 ivi_FaceIDEmptydataResp 4;
BA_ "GenSigSendType" SG_ 497 ivi_dmsRegiFaceIDSts 4;
BA_ "GenSigStartValue" SG_ 766 ic_totalMileage 16777215;
BA_ "GenSigStartValue" SG_ 766 ic_RemainingMileage 1023;
BA_ "GenSigSendType" SG_ 849 ivi_dsSeatBackPos 1;
BA_ "GenSigSendType" SG_ 849 ivi_dsSeatSlidePos 1;
BA_ "GenSigSendType" SG_ 849 ivi_dsSeatHeightPos 1;
BA_ "GenSigSendType" SG_ 849 ivi_dsSeatCushionAnglePos 1;
BA_ "GenSigSendType" SG_ 849 ivi_LeftMirrorVerticalPos 1;
BA_ "GenSigSendType" SG_ 849 ivi_LeftMirrorHorizontalPos 1;
BA_ "GenSigSendType" SG_ 849 ivi_RightMirrorVerticalPos 1;
BA_ "GenSigSendType" SG_ 849 ivi_RightMirrorHorizontalPos 1;
BA_ "GenSigSendType" SG_ 850 ivi_dsSeatBackPos2 1;
BA_ "GenSigSendType" SG_ 850 ivi_dsSeatSlidePos2 1;
BA_ "GenSigSendType" SG_ 850 ivi_dsSeatHeightPos2 1;
BA_ "GenSigSendType" SG_ 850 ivi_dsSeatCushionAnglePos2 1;
BA_ "GenSigSendType" SG_ 850 ivi_LeftMirrorVerticalPos2 1;
BA_ "GenSigSendType" SG_ 850 ivi_LeftMirrorHorizontalPos2 1;
BA_ "GenSigSendType" SG_ 850 ivi_RightMirrorVerticalPos2 1;
BA_ "GenSigSendType" SG_ 850 ivi_RightMirrorHorizontalPos2 1;
BA_ "GenSigSendType" SG_ 851 ivi_dsSeatBackPos3 1;
BA_ "GenSigSendType" SG_ 851 ivi_dsSeatSlidePos3 1;
BA_ "GenSigSendType" SG_ 851 ivi_dsSeatHeightPos3 1;
BA_ "GenSigSendType" SG_ 851 ivi_dsSeatCushionAnglePos3 1;
BA_ "GenSigSendType" SG_ 851 ivi_LeftMirrorVerticalPos3 1;
BA_ "GenSigSendType" SG_ 851 ivi_LeftMirrorHorizontalPos3 1;
BA_ "GenSigSendType" SG_ 851 ivi_RightMirrorVerticalPos3 1;
BA_ "GenSigSendType" SG_ 851 ivi_RightMirrorHorizontalPos3 1;
BA_ "GenSigSendType" SG_ 949 ivi_hvacOnOffReq 4;
BA_ "GenSigSendType" SG_ 949 ivi_hvacAutoModeReq 4;
BA_ "GenSigSendType" SG_ 949 ivi_hvacRecircModeReq 4;
BA_ "GenSigStartValue" SG_ 949 ivi_hvacModeReq 7;
BA_ "GenSigSendType" SG_ 949 ivi_hvacModeReq 4;
BA_ "GenSigStartValue" SG_ 949 ivi_driverTempCSet 31;
BA_ "GenSigSendType" SG_ 949 ivi_driverTempCSet 4;
BA_ "GenSigStartValue" SG_ 949 ivi_passengerTempCSet 31;
BA_ "GenSigSendType" SG_ 949 ivi_passengerTempCSet 4;
BA_ "GenSigSendType" SG_ 949 ivi_hvacDualMode 4;
BA_ "GenSigSendType" SG_ 949 ivi_acReq 4;
BA_ "GenSigSendType" SG_ 949 ivi_pm25StsReq 4;
BA_ "GenSigSendType" SG_ 949 ivi_acWorkModeSet 4;
BA_ "GenSigSendType" SG_ 949 ivi_acDiagReq 4;
BA_ "GenSigSendType" SG_ 949 IVI_Backlightadjust 4;
BA_ "GenSigSendType" SG_ 949 IVI_FreshAirModeSet 4;
BA_ "GenSigSendType" SG_ 949 IVI_VentilationCoolSet 4;
BA_ "GenSigSendType" SG_ 949 ivi_frontDefrostCtrl 4;
BA_ "GenSigSendType" SG_ 949 ivi_languageSet 4;
BA_ "GenSigSendType" SG_ 949 ivi_unitSet 4;
BA_ "GenSigSendType" SG_ 949 ivi_hvacBlowLvReq 4;
BA_ "GenSigStartValue" SG_ 949 IVI_Sunroof_HorizontalControl 127;
BA_ "GenSigSendType" SG_ 949 IVI_Sunroof_HorizontalControl 4;
BA_ "GenSigStartValue" SG_ 1011 IC_MaintenanceMileage 65535;
BA_ "GenSigStartValue" SG_ 1011 ic_lastingtime 2047;
BA_ "GenSigStartValue" SG_ 1011 ic_mileageSincethelastcharge 16383;
BA_ "GenSigStartValue" SG_ 1011 ic_tripmeterThisMoment 16383;
BA_ "GenSigStartValue" SG_ 1248 ic_totalMileageRev 16777215;
BA_ "GenSigStartValue" SG_ 1013 IC_TripBAvgPwrConsum 1023;
BA_ "GenSigStartValue" SG_ 1013 IC_TripAAvgPwrConsum 1023;
BA_ "GenSigStartValue" SG_ 1013 IC_SinceChargeAvgPwrConsum 1023;
BA_ "GenSigStartValue" SG_ 1013 IC_CurrentTripAvgPwrConsum 1023;
BA_ "GenSigStartValue" SG_ 1022 ivi_timeInfoDay 1;
BA_ "GenSigStartValue" SG_ 1022 ivi_timeInfoMonth 1;
BA_ "GenSigStartValue" SG_ 1022 ivi_timeValid 1;
BA_ "GenSigStartValue" SG_ 1022 ivi_altitude 1;
BA_ "GenSigStartValue" SG_ 1154 IC_FuelConsump 1023;
BA_ "GenSigStartValue" SG_ 1154 IC_ConsumpRatioInstant 1535;
BA_ "GenSigStartValue" SG_ 1154 IC_OilRemainingMileage 1023;
BA_ "GenSigStartValue" SG_ 1154 ic_oilPercent 255;
BA_ "GenSigStartValue" SG_ 1170 ic_tripmeterA 16383;
BA_ "GenSigStartValue" SG_ 1170 ic_tripmeterB 16777215;
BA_ "GenSigStartValue" SG_ 1170 IC_ChargingPower 8191;
BA_ "GenSigStartValue" SG_ 1170 IC_ChargingSpeed 2047;
BA_ "GenSigSendType" SG_ 1173 IVI_IC_Sync 4;
BA_ "GenSigStartValue" SG_ 1264 IC_TripALastingTime 8191;
BA_ "GenSigStartValue" SG_ 1264 IC_TripAAvgSpeed 511;
BA_ "GenSigStartValue" SG_ 1264 IC_TripBLastingTime 8191;
BA_ "GenSigStartValue" SG_ 1264 IC_TripBAavSpeed 511;
BA_ "GenSigStartValue" SG_ 1264 IC_TripBAvgOilConsum 255;
BA_ "GenSigStartValue" SG_ 1264 IC_TripAAvgOilConsum 255;
BA_ "GenSigStartValue" SG_ 1265 IC_SinceChargeAvgSpd 511;
BA_ "GenSigStartValue" SG_ 1265 IC_SinceChargeTime 8191;
BA_ "GenSigStartValue" SG_ 1265 IC_SinceChargeAvgOIilConsum 255;
BA_ "GenSigStartValue" SG_ 1265 IC_CurrentTripAAvgOilConsum 255;
BA_ "GenSigStartValue" SG_ 1265 IC_CurrentTripAvgSpd 511;
BA_ "GenSigSendType" SG_ 1573 IVI_RMR 2;
BA_ "GenSigSendType" SG_ 1573 IVI_AWB 2;
BA_ "GenSigSendType" SG_ 1957 Diag_Resp_IVI_Data 2;
BA_ "GenSigSendType" SG_ 1978 Diag_Resp_NVS_Data 2;
BA_ "GenSigSendType" SG_ 1943 Diag_Resp_PDC_Data 2;
BA_ "GenSigStartValue" SG_ 72 Tbox_AuthResponeStatus 255;
BA_ "GenSigSendType" SG_ 72 Tbox_AuthResponeStatus 1;
BA_ "GenSigStartValue" SG_ 72 Tbox_AuthKeyData 65535;
BA_ "GenSigSendType" SG_ 72 Tbox_AuthKeyData 1;
BA_ "GenSigSendType" SG_ 88 tbox_remoteLockCtrlReq 2;
BA_ "GenSigSendType" SG_ 88 tbox_remoteCarSearchReq 2;
BA_ "GenSigSendType" SG_ 88 tbox_remoteTailgateCtrlReq 2;
BA_ "GenSigSendType" SG_ 88 tbox_sunroofGlassCmd 2;
BA_ "GenSigSendType" SG_ 88 tbox_remoteForbiddenOn 2;
BA_ "GenSigSendType" SG_ 88 tbox_HornReq 2;
BA_ "GenSigSendType" SG_ 88 tbox_remotePowerCtrlReq 2;
BA_ "GenSigSendType" SG_ 88 tbox_remoteDrSeatHeatReq 2;
BA_ "GenSigSendType" SG_ 88 tbox_remotePassSeatHeatReq 2;
BA_ "GenSigSendType" SG_ 88 tbox_HazardLightReq 2;
BA_ "GenSigSendType" SG_ 88 tbox_remoteACOnOffReq 2;
BA_ "GenSigSendType" SG_ 88 tbox_remoteInfoCollectionReq 2;
BA_ "GenSigSendType" SG_ 88 tbox_oneTouchCoolSet 2;
BA_ "GenSigSendType" SG_ 88 tbox_oneTouchHeatSet 2;
BA_ "GenSigSendType" SG_ 88 tbox_remoteWinLFCtrlRqst 2;
BA_ "GenSigSendType" SG_ 88 tbox_remoteWinRFCtrlRqst 2;
BA_ "GenSigSendType" SG_ 88 tbox_remoteWinLRCtrlRqst 2;
BA_ "GenSigSendType" SG_ 88 tbox_remoteWinRRCtrlRqst 2;
BA_ "GenSigSendType" SG_ 88 tbox_lowBeamOnOffCtrl 2;
BA_ "GenSigStartValue" SG_ 126 tbox_MaxChargeCurrentSet 63;
BA_ "GenSigStartValue" SG_ 126 tbox_MaxChargeSOCSet 127;
BA_ "GenSigSendType" SG_ 168 tbox_dvrTakePicCtrl 1;
BA_ "GenSigSendType" SG_ 1576 TBOX_RMR 2;
BA_ "GenSigSendType" SG_ 1576 TBOX_AWB 2;
BA_ "GenSigSendType" SG_ 1793 Diag_PhyReq_BCM_Data 2;
BA_ "GenSigSendType" SG_ 1796 Diag_PhyReq_POT_Data 2;
BA_ "GenSigSendType" SG_ 1797 Diag_PhyReq_DSCU_Data 2;
BA_ "GenSigSendType" SG_ 1806 Diag_PhyReq_GW_Data 2;
BA_ "GenSigSendType" SG_ 1817 Diag_PhyReq_SWM_Data 2;
BA_ "GenSigSendType" SG_ 1824 Diag_PhyReq_HCMR_Data 2;
BA_ "GenSigSendType" SG_ 1825 Diag_PhyReq_HCML_Data 2;
BA_ "GenSigSendType" SG_ 1826 Diag_PhyReq_ESC_Data 2;
BA_ "GenSigSendType" SG_ 1828 Diag_PhyReq_AVM_Data 2;
BA_ "GenSigSendType" SG_ 1830 Diag_PhyReq_AC_Data 2;
BA_ "GenSigSendType" SG_ 1831 Diag_PhyReq_ASC_Data 2;
BA_ "GenSigSendType" SG_ 1833 Diag_PhyReq_GSM_Data 2;
BA_ "GenSigSendType" SG_ 1834 Diag_PhyReq_MPC_Data 2;
BA_ "GenSigSendType" SG_ 1835 Diag_PhyReq_MRR_R1_Data 2;
BA_ "GenSigSendType" SG_ 1836 Diag_PhyReq_MRR_R2_Data 2;
BA_ "GenSigSendType" SG_ 1841 Diag_PhyReq_VCU_Data 2;
BA_ "GenSigSendType" SG_ 1842 Diag_PhyReq_MCUR0_Data 2;
BA_ "GenSigSendType" SG_ 1843 Diag_PhyReq_MCUF0_Data 2;
BA_ "GenSigSendType" SG_ 1844 Diag_PhyReq_BMS_Data 2;
BA_ "GenSigSendType" SG_ 1845 Diag_PhyReq_iB_Data 2;
BA_ "GenSigSendType" SG_ 1847 Diag_PhyReq_OBCM_Data 2;
BA_ "GenSigSendType" SG_ 1849 Diag_PhyReq_MRR_Data 2;
BA_ "GenSigSendType" SG_ 1851 Diag_PhyReq_BLE_Data 2;
BA_ "GenSigSendType" SG_ 1852 Diag_PhyReq_GCU_Data 2;
BA_ "GenSigSendType" SG_ 1859 Diag_PhyReq_APA_Data 2;
BA_ "GenSigSendType" SG_ 1860 Diag_PhyReq_EPS_Data 2;
BA_ "GenSigSendType" SG_ 1866 Diag_PhyReq_HANDLE_LF_Data 2;
BA_ "GenSigSendType" SG_ 1867 Diag_PhyReq_HANDLE_RF_Data 2;
BA_ "GenSigSendType" SG_ 1868 Diag_PhyReq_HANDLE_LR_Data 2;
BA_ "GenSigSendType" SG_ 1869 Diag_PhyReq_HANDLE_RR_Data 2;
BA_ "GenSigSendType" SG_ 1960 Diag_Resp_TBOX_Data 2;
BA_ "GenSigSendType" SG_ 2016 Diag_PhyReq_ECU_Data 2;
BA_ "GenSigSendType" SG_ 2018 OBD_PhyReq_BMS_Data 2;
BA_ "GenSigSendType" SG_ 2019 OBD_PhyReq_GCU_Data 2;
BA_ "GenSigSendType" SG_ 2020 OBD_PhyReq_OBCM_Data 2;
BA_ "GenSigSendType" SG_ 2021 OBD_PhyReq_iBooster_Data 2;
BA_ "GenSigSendType" SG_ 2022 OBD_PhyReq_ESC_Data 2;
BA_ "GenSigSendType" SG_ 2023 OBD_PhyReq_VCU_Data 2;
BA_ "GenSigSendType" SG_ 2033 Diag_PhyReq_ACU_Data 2;
BA_ "GenSigStartValue" SG_ 928 vsp_soundEnable 1;
BA_ "GenSigStartValue" SG_ 928 vsp_errorIdentification 1;
BA_ "GenSigSendType" SG_ 1936 Diag_Resp_VSP_Data 2;
BA_ "GenSigSendType" SG_ 1933 Diag_Resp_WCM_Data 2;
BA_ "GenSigStartValue" SG_ 1444 vcu_HVPTC_InternalWaterTemp2 255;
BA_ "GenSigStartValue" SG_ 1444 vcu_VALVE3_DATA1 8;
BA_ "GenSigStartValue" SG_ 1444 vcu_VALVE4_DATA1 8;
BA_ "GenSigStartValue" SG_ 1444 vcu_battCoolantPump1Spd 8;
BA_ "GenSigStartValue" SG_ 1444 vcu_battCoolantPump2Spd 8;
BA_ "GenSigStartValue" SG_ 1444 vcu_driveUnitCoolantPump1Spd 8;
BA_ "GenSigStartValue" SG_ 1444 vcu_driveUnitCoolantPump2Spd 8;
BA_ "GenSigStartValue" SG_ 1445 vcu_HVPTC_HV_DC_curr 255;
BA_ "GenSigStartValue" SG_ 1445 vcu_HVPTC_HV_voltage 255;
VAL_ 937 icm_dvrSts 7 "FAULT" 6 "Monitor RECORD" 5 "VIDEO PLAY" 4 "URGENCY RECORD" 3 "RECORD STOP" 2 "NORMAL RECORD" 1 "Code" 0 "OFF" ;
VAL_ 937 icm_dvrPhotoSts 1 "Active" 0 "NotActive" ;
VAL_ 937 icm_dvrSDcardSts 4 "need to be formated" 3 "photo area full" 2 "urgent area full" 1 "Error" 0 "Normal" ;
VAL_ 937 icm_dvrPhotoOutput 1 "Active" 0 "NotActive" ;
VAL_ 937 icm_dvrExitReq 3 "hint_Speed" 2 "Exit Rec" 1 "EnterRes" 0 "NO Request" ;
VAL_ 937 icm_roaSts 3 "FAULT" 2 "Active" 1 "STANDBY" 0 "OFF" ;
VAL_ 937 icm_roaDisplayRes 3 "hint" 2 "Exit Res" 1 "Enter Res" 0 "NO Request" ;
VAL_ 937 icm_roaPassengerL 1 "exist" 0 "not exist" ;
VAL_ 937 icm_roaPassengerM 1 "exist" 0 "not exist" ;
VAL_ 937 icm_roaPassengerR 1 "exist" 0 "not exist" ;
VAL_ 937 icm_roaPassengerAge 3 "unkown" 2 "Old" 1 "Child" 0 "default" ;
VAL_ 937 icm_roaPassengerMood 3 "unkown" 2 "sad" 1 "happy" 0 "default" ;
VAL_ 937 icm_ivipressphto 1 "Request" 0 "No Request" ;
VAL_ 937 icm_dmsSts 7 "Reserve" 6 "Reserve" 5 "Reserve" 4 "failure" 3 "Active" 2 "Standby" 1 "Passive" 0 "OFF" ;
VAL_ 937 icm_dmsCameraSts 7 "Reserve" 6 "Reserve" 5 "Reserve" 4 "Error" 3 "Block" 2 "Face Lost" 1 "Normal" 0 "OFF" ;
VAL_ 937 icm_dmsWearySet 1 "ON" 0 "OFF" ;
VAL_ 937 icm_dmsWearyAssisSet 1 "ON" 0 "OFF" ;
VAL_ 937 icm_dmsWearyLeverSts 7 "Reserve" 6 "Reserve" 5 "Reserve" 4 "Reserve" 3 "Level 3" 2 "Level 2" 1 "Level 1" 0 "Normal" ;
VAL_ 937 icm_dmsDrvBehaviorMon 7 "Reserve" 6 "Reserve" 5 "Reserve" 4 "Reserve" 3 "Smoke" 2 "Phone" 1 "Normal" 0 "OFF" ;
VAL_ 937 icm_dmsDistractLeverSts 3 "Reserve" 2 "Long Time" 1 "Short Time" 0 "Normal" ;
VAL_ 937 icm_dmsSenSetRsp 1 "Sensitive" 0 "Normal" ;
VAL_ 937 icm_roaRemind 3 "Pet" 2 "Wallet" 1 "People" 0 "Invalid" ;
VAL_ 937 icm_dmsDriverMood 3 "unkown" 2 "sad" 1 "happy" 0 "default" ;
VAL_ 937 icm_dmsDriver 1 "exist" 0 "not exist" ;
VAL_ 937 icm_dmsPassenger 1 "exist" 0 "not exist" ;
VAL_ 937 icm_dmsFaceID 15 "Reserved" 14 "Reserved" 13 "Reserved" 12 "Reserved" 11 "Unkown" 10 "Driver10" 9 "Driver9" 8 "Driver8" 7 "Driver7" 6 "Driver6" 5 "Driver5" 4 "Driver4" 3 "Driver3" 2 "Driver2" 1 "Driver1" 0 "default" ;
VAL_ 937 icm_dmsGestureID 15 "Inactive" 14 "Active" 13 "Reserved" 12 "Reserved" 11 "Reserved" 10 "Reserved" 9 "Reserved" 8 "Reserved" 7 "Reserved" 6 "Reserved" 5 "Gesture 5" 4 "Gesture 4" 3 "Gesture 3" 2 "Gesture 2" 1 "Gesture 1" 0 "OFF" ;
VAL_ 937 icm_dmsVideoCallSts 7 "Reserved" 6 "hint" 5 "OverviewVideo" 4 "RearVideo" 3 "FrontVideo" 2 "PassengerVideo" 1 "DriverVideo" 0 "No Response" ;
VAL_ 937 icm_roaITLLightReq 3 "Reserved" 2 "CloseLight" 1 "OpenLight" 0 "Invalid" ;
VAL_ 937 icm_dvrVideoOutput 1 "Active" 0 "NotActive" ;
VAL_ 937 icm_roaCameraSts 3 "Reserved" 2 "Error" 1 "On" 0 "OFF" ;
VAL_ 939 icm_dmsFaceIDResp 1 "ON" 0 "OFF" ;
VAL_ 939 icm_dmsGestureIDResp 1 "ON" 0 "OFF" ;
VAL_ 939 icm_FaceIDRegiResp 3 "Registration failure" 2 "Registration successful" 1 "Registration in progress" 0 "Default" ;
VAL_ 939 icm_FaceIDLoginResp 3 "Failed" 2 "Succeed" 1 "Scanning" 0 "Default" ;
VAL_ 939 icm_beautyResp 1 "ON" 0 "OFF" ;
VAL_ 939 icm_arDisplayResponse 1 "ON" 0 "OFF" ;
VAL_ 939 icm_cameraChangeResp 3 "ROA" 2 "DVR" 1 "DMS" 0 "OFF" ;
VAL_ 939 icm_dmsDistractForfvsr 3 "fault" 2 "distract" 1 "normal" 0 "initial" ;
VAL_ 939 icm_FaceIDNumberResp 10 "10" 9 "9" 8 "8" 7 "7" 6 "6" 5 "5" 4 "4" 3 "3" 2 "2" 1 "1" 0 "0" ;
VAL_ 939 icm_dmsRegiFaceID 15 "Reserved" 14 "Reserved" 13 "Reserved" 12 "Reserved" 11 "Unkown" 10 "Driver10" 9 "Driver9" 8 "Driver8" 7 "Driver7" 6 "Driver6" 5 "Driver5" 4 "Driver4" 3 "Driver3" 2 "Driver2" 1 "Driver1" 0 "No Request" ;
VAL_ 939 icm_dmsLoginFaceID 15 "Reserved" 14 "Reserved" 13 "Reserved" 12 "Reserved" 11 "Unkown" 10 "Driver10" 9 "Driver9" 8 "Driver8" 7 "Driver7" 6 "Driver6" 5 "Driver5" 4 "Driver4" 3 "Driver3" 2 "Driver2" 1 "Driver1" 0 "No Request" ;
VAL_ 939 icm_dmsDeleteFaceID 15 "Reserved" 14 "Reserved" 13 "Reserved" 12 "Reserved" 11 "Unkown" 10 "Driver10" 9 "Driver9" 8 "Driver8" 7 "Driver7" 6 "Driver6" 5 "Driver5" 4 "Driver4" 3 "Driver3" 2 "Driver2" 1 "Driver1" 0 "No Request" ;
VAL_ 939 icm_FaceIDEmptydataResp 3 "Reserved" 2 "Failed" 1 "Success" 0 "No Request" ;
VAL_ 939 icm_dmsRegiFaceIDSts 3 "Reserved" 2 "Failed" 1 "Success" 0 "No Request" ;
VAL_ 1545 ICM_RMR 1 "Repeat Message State requested" 0 "Repeat Message State not requested" ;
VAL_ 1545 ICM_AWB 1 "Node has woken up the network (active Wakeup)" 0 "Node has not woken up the network (passive wakeup)" ;
VAL_ 82 ic_engOffTimeValid 1 "VALID" 0 "INVALID" ;
VAL_ 117 ivi_hoodUnlockCtrl 3 "INVALID" 2 "RESERVED" 1 "UNLOCK" 0 "NO_COMMAND" ;
VAL_ 117 ivi_RearWindowLockCtrl 3 "INVALID" 2 "LOCK" 1 "UNLOCK" 0 "NO_COMMAND" ;
VAL_ 117 ivi_gloveBoxUnlockCtrl 3 "INVALID" 2 "RESERVED" 1 "UNLOCK" 0 "NO_COMMAND" ;
VAL_ 117 ivi_centralLockCtrl 3 "INVALID" 2 "LOCK" 1 "UNLOCK" 0 "NO_COMMAND" ;
VAL_ 117 ivi_fuelPortCapOpenCtrl 3 "INVALID" 2 "RESERVED_FUELPORT" 1 "OPEN_FUELPORT" 0 "NO_COMMAND_FUELPORT" ;
VAL_ 117 ivi_lowBeamOnOffCtrl 3 "INVALID" 2 "ON" 1 "OFF" 0 "NO_COMMAND" ;
VAL_ 117 ivi_v2vChrgOnOffSet 3 "INVALID" 2 "ON" 1 "OFF" 0 "NO Request" ;
VAL_ 117 ivi_posLampOnOffCtrl 3 "INVALID" 2 "ON" 1 "OFF" 0 "NO_COMMAND" ;
VAL_ 117 ivi_obcDschrgOnOffSet 3 "INVALID" 2 "ON" 1 "OFF" 0 "NO_COMMAND" ;
VAL_ 117 ivi_modememory 3 "INVALID" 2 "Memory" 1 "No_Memory" 0 "NO REQUEST" ;
VAL_ 117 ivi_rearFogLampOnOffCtrl 3 "INVALID" 2 "ON" 1 "OFF" 0 "NO_COMMAND" ;
VAL_ 117 ivi_ventilateSts 3 "NO  Request" 2 "Reserved" 1 "VentilateOn" 0 "VentilateOff" ;
VAL_ 117 ivi_chrgPortCapOpenCtrl 3 "INVALID" 2 "RESERVED" 1 "OPEN" 0 "NO_COMMAND" ;
VAL_ 117 ivi_sunroofGlassCmd 7 "STOP_SUNSHADE" 6 "CLOSE_SUNSHAGE" 5 "OPEN_SUNSHADE" 4 "TILTUP_GLASS" 3 "STOP_GLASS" 2 "CLOSE_GLASS" 1 "OPEN_GLASS" 0 "NO_CMD" ;
VAL_ 117 ivi_NormalHvOffReq 1 "REQUEST" 0 "NO_REQUEST" ;
VAL_ 117 ivi_antiTheftAlarmFormSet 3 "No Request" 2 "Reserved" 1 "Vision+Voice" 0 "Only Vision" ;
VAL_ 117 ivi_tailgateCtrl 3 "STOP" 2 "OPEN" 1 "CLOSE" 0 "NO_COMMAND" ;
VAL_ 117 ivi_MirrorSw 3 "INVALID" 2 "RESERVED" 1 "SW_PRESSED" 0 "SW_NOT_PRESSED" ;
VAL_ 117 ivi_rearDefrostCtrl 3 "INVALID" 2 "ON" 1 "OFF" 0 "NO_COMMAND" ;
VAL_ 117 IVI_SOCmodeSet 3 "REVmode" 2 "EVmode" 1 "SmartMode" 0 "no request" ;
VAL_ 117 ivi_MaxFuelConsumptionSW 3 "INVALID" 2 "ON" 1 "OFF" 0 "NO_COMMAND" ;
VAL_ 117 ivi_MaxFuelConsumptionModeSW 3 "INVALID" 2 "Low Speed" 1 "High Speed" 0 "NO_COMMAND" ;
VAL_ 117 ivi_v2vChrgOptCurntSet 15 "INVALID" 14 "Reserved" 13 "Reserved" 12 "Reserved" 11 "Reserved" 10 "Reserved" 9 "100" 8 "90" 7 "80" 6 "70" 5 "60" 4 "50" 3 "40" 2 "30" 1 "20" 0 "NO Request" ;
VAL_ 117 ivi_BatteryCondition 3 "INVALID" 2 "ON" 1 "OFF" 0 "NO REQUEST" ;
VAL_ 117 ivi_approachingUnlockCtrl 3 "INVALID" 2 "INACTIVE" 1 "ACTIVE" 0 "NO_COMMAND" ;
VAL_ 117 ivi_awayLockCtrl 3 "INVALID" 2 "INACTIVE" 1 "ACTIVE" 0 "NO_COMMAND" ;
VAL_ 117 ivi_WipperMaintenanceCtrl 1 "REQUESTED" 0 "NO_REQUEST" ;
VAL_ 117 ivi_gunUnlockCtrlReq 1 "Request" 0 "No Request" ;
VAL_ 117 ivi_ExhibitionSet 3 "INVALID" 2 "ExhibitionSetOff" 1 "ExhibitionSetOn" 0 "NO Request" ;
VAL_ 117 ivi_potOnOffSet 3 "Stop" 2 "Open" 1 "Close" 0 "NoInput" ;
VAL_ 117 ivi_frontWindshieldHeatingCtrl 3 "INVALID" 2 "ON" 1 "OFF" 0 "NO_COMMAND" ;
VAL_ 117 ivi_lowVoltPowerCtrl 3 "INVALID" 2 "RESERVED" 1 "POWER_ON_REQUEST" 0 "NO_COMMAND" ;
VAL_ 133 ivi_pot_SpeechCtrlOnOffSts 3 "STOP" 2 "OPEN" 1 "CLOSE" 0 "NoInput" ;
VAL_ 133 ivi_ChargPileAuthSts 1 "Authentication success" 0 "No authentication" ;
VAL_ 149 ivi_lockAutoCloseWinCtrl 3 "INVALID" 2 "INACTIVE" 1 "ACTIVE" 0 "NO_COMMAND" ;
VAL_ 149 ivi_ambientLightOnOffSet 3 "INVALID" 2 "ON" 1 "OFF" 0 "NO  Request" ;
VAL_ 149 ivi_sunroofRollshadeCtrlSelect 2 "Rollshade" 1 "Sunroof" 0 "NO Request" ;
VAL_ 149 ivi_ambientLightColorSet 255 "INVALID" 254 "Reserved" 253 "Reserved" 252 "Reserved" 251 "Reserved" 250 "Reserved" 249 "Reserved" 248 "Reserved" 247 "Reserved" 246 "Reserved" 245 "Reserved" 244 "Reserved" 243 "Reserved" 242 "Reserved" 241 "Reserved" 240 "Reserved" 239 "Reserved" 238 "Reserved" 237 "Reserved" 236 "Reserved" 235 "Reserved" 234 "Reserved" 233 "Reserved" 232 "Reserved" 231 "Reserved" 230 "Reserved" 229 "Reserved" 228 "Reserved" 227 "Reserved" 226 "Reserved" 225 "Reserved" 224 "Reserved" 223 "Reserved" 222 "Reserved" 221 "Reserved" 220 "Reserved" 219 "Reserved" 218 "Reserved" 217 "Reserved" 216 "Reserved" 215 "Reserved" 214 "Reserved" 213 "Reserved" 212 "Reserved" 211 "Reserved" 210 "Reserved" 209 "Reserved" 208 "Reserved" 207 "Reserved" 206 "Reserved" 205 "Reserved" 204 "Reserved" 203 "Reserved" 202 "Reserved" 201 "Reserved" 200 "Reserved" 199 "Reserved" 198 "Reserved" 197 "Reserved" 196 "Reserved" 195 "Reserved" 194 "Reserved" 193 "Reserved" 192 "Reserved" 191 "Reserved" 190 "Reserved" 189 "Reserved" 188 "Reserved" 187 "Reserved" 186 "Reserved" 185 "Reserved" 184 "Reserved" 183 "Reserved" 182 "Reserved" 181 "Reserved" 180 "Reserved" 179 "Reserved" 178 "Reserved" 177 "Reserved" 176 "Reserved" 175 "Reserved" 174 "Reserved" 173 "Reserved" 172 "Reserved" 171 "Reserved" 170 "Reserved" 169 "Reserved" 168 "Reserved" 167 "Reserved" 166 "Reserved" 165 "Reserved" 164 "Reserved" 163 "Reserved" 162 "Reserved" 161 "Reserved" 160 "Reserved" 159 "Reserved" 158 "Reserved" 157 "Reserved" 156 "Reserved" 155 "Reserved" 154 "Reserved" 153 "Reserved" 152 "Reserved" 151 "Reserved" 150 "Reserved" 149 "Reserved" 148 "Reserved" 147 "Reserved" 146 "Reserved" 145 "Reserved" 144 "Reserved" 143 "Reserved" 142 "Reserved" 141 "Reserved" 140 "Reserved" 139 "Reserved" 138 "Reserved" 137 "Reserved" 136 "Reserved" 135 "Reserved" 134 "Reserved" 133 "Reserved" 132 "Reserved" 131 "Reserved" 130 "Reserved" 129 "Reserved" 128 "Reserved" 127 "Reserved" 126 "Reserved" 125 "Reserved" 124 "Reserved" 123 "Reserved" 122 "Reserved" 121 "Reserved" 120 "Reserved" 119 "Reserved" 118 "Reserved" 117 "Reserved" 116 "Reserved" 115 "Reserved" 114 "Reserved" 113 "Reserved" 112 "Reserved" 111 "Reserved" 110 "Reserved" 109 "Reserved" 108 "Reserved" 107 "Reserved" 106 "Reserved" 105 "Reserved" 104 "Reserved" 103 "Reserved" 102 "Reserved" 101 "Reserved" 100 "Reserved" 99 "Reserved" 98 "Reserved" 97 "Reserved" 96 "Reserved" 95 "Reserved" 94 "Reserved" 93 "Reserved" 92 "Reserved" 91 "Reserved" 90 "Reserved" 89 "Reserved" 88 "Reserved" 87 "Reserved" 86 "Reserved" 85 "Reserved" 84 "Reserved" 83 "Reserved" 82 "Reserved" 81 "Reserved" 80 "Reserved" 79 "Reserved" 78 "Reserved" 77 "Reserved" 76 "Reserved" 75 "Reserved" 74 "Reserved" 73 "Reserved" 72 "Reserved" 71 "Reserved" 70 "Reserved" 69 "Reserved" 68 "Reserved" 67 "Reserved" 66 "Reserved" 65 "Reserved" 64 "Colour1~Colour64" 63 "Colour1~Colour64" 62 "Colour1~Colour64" 61 "Colour1~Colour64" 60 "Colour1~Colour64" 59 "Colour1~Colour64" 58 "Colour1~Colour64" 57 "Colour1~Colour64" 56 "Colour1~Colour64" 55 "Colour1~Colour64" 54 "Colour1~Colour64" 53 "Colour1~Colour64" 52 "Colour1~Colour64" 51 "Colour1~Colour64" 50 "Colour1~Colour64" 49 "Colour1~Colour64" 48 "Colour1~Colour64" 47 "Colour1~Colour64" 46 "Colour1~Colour64" 45 "Colour1~Colour64" 44 "Colour1~Colour64" 43 "Colour1~Colour64" 42 "Colour1~Colour64" 41 "Colour1~Colour64" 40 "Colour1~Colour64" 39 "Colour1~Colour64" 38 "Colour1~Colour64" 37 "Colour1~Colour64" 36 "Colour1~Colour64" 35 "Colour1~Colour64" 34 "Colour1~Colour64" 33 "Colour1~Colour64" 32 "Colour1~Colour64" 31 "Colour1~Colour64" 30 "Colour1~Colour64" 29 "Colour1~Colour64" 28 "Colour1~Colour64" 27 "Colour1~Colour64" 26 "Colour1~Colour64" 25 "Colour1~Colour64" 24 "Colour1~Colour64" 23 "Colour1~Colour64" 22 "Colour1~Colour64" 21 "Colour1~Colour64" 20 "Colour1~Colour64" 19 "Colour1~Colour64" 18 "Colour1~Colour64" 17 "Colour1~Colour64" 16 "Colour1~Colour64" 15 "Colour1~Colour64" 14 "Colour1~Colour64" 13 "Colour1~Colour64" 12 "Colour1~Colour64" 11 "Colour1~Colour64" 10 "Colour1~Colour64" 9 "Colour1~Colour64" 8 "Colour1~Colour64" 7 "Colour1~Colour64" 6 "Colour1~Colour64" 5 "Colour1~Colour64" 4 "Colour1~Colour64" 3 "Colour1~Colour64" 2 "Colour1~Colour64" 1 "Colour1~Colour64" 0 "NO  Request" ;
VAL_ 149 ivi_ambientLightLumiLvSet 11 "LV10" 10 "LV9" 9 "LV8" 8 "LV7" 7 "LV6" 6 "LV5_NORMAL" 5 "LV4" 4 "LV3" 3 "LV2" 2 "LV1" 1 "LV0" 0 "NO_COMMAND" ;
VAL_ 149 ivi_screenAutoLiftCtrl 3 "INVALID" 2 "INACTIVE" 1 "ACTIVE" 0 "NO_COMMAND" ;
VAL_ 149 ivi_doorTopSW 3 "INVALID" 2 "ON" 1 "OFF" 0 "NO_COMMAND" ;
VAL_ 149 ivi_parkAutoCloseDRLCtrl 3 "INVALID" 2 "Disable" 1 "Enable" 0 "No Request" ;
VAL_ 149 ivi_followMeHomeSet 7 "INVALID" 4 "60S" 3 "30S" 2 "15S" 1 "OFF" 0 "NO_COMMAND" ;
VAL_ 149 ivi_WheelAlignmentCtrl 1 "REQUEST" 0 "NO_REQUEST" ;
VAL_ 149 ivi_WinLFCtrlRqst 7 "Invalid" 6 "Ventilate" 5 "Stop" 4 "MANUAL_DOWN_MOVING" 3 "AUTO_DOWN_MOVING" 2 "MANUAL_UP_MOVING" 1 "AUTO_UP_MOVING" 0 "NO_Req" ;
VAL_ 149 ivi_WinRFCtrlRqst 7 "Invalid" 6 "Ventilate" 5 "Stop" 4 "MANUAL_DOWN_MOVING" 3 "AUTO_DOWN_MOVING" 2 "MANUAL_UP_MOVING" 1 "AUTO_UP_MOVING" 0 "NO_Req" ;
VAL_ 149 ivi_WinLRCtrlRqst 7 "Invalid" 6 "Ventilate" 5 "Stop" 4 "MANUAL_DOWN_MOVING" 3 "AUTO_DOWN_MOVING" 2 "MANUAL_UP_MOVING" 1 "AUTO_UP_MOVING" 0 "NO_Req" ;
VAL_ 149 ivi_WinRRCtrlRqst 7 "Invalid" 6 "Ventilate" 5 "Stop" 4 "MANUAL_DOWN_MOVING" 3 "AUTO_DOWN_MOVING" 2 "MANUAL_UP_MOVING" 1 "AUTO_UP_MOVING" 0 "NO_Req" ;
VAL_ 149 IVI_DGSW 3 "INVALID" 2 "CLOSE" 1 "OPEN" 0 "NO COMMOND" ;
VAL_ 149 IVI_DGPercentCtrl 31 "INVALID" 11 "36" 10 "15.5" 9 "13" 8 "11.9" 7 "11.4" 6 "10.6" 5 "10.3" 4 "9.6" 3 "8.8" 2 "7.5" 1 "0" 0 "NO_Req" ;
VAL_ 149 IVI_speedautolockonoffSet 3 "INVALID" 2 "ON" 1 "OFF" 0 "NO  Request" ;
VAL_ 149 ivi_adbOnOffSet 3 "NO  Request" 2 "Reserved" 1 "ON" 0 "OFF" ;
VAL_ 149 ivi_hcmHeightSet 7 "Reserved" 6 "Reserved" 5 "Level 5" 4 "Level 4" 3 "Level 3" 2 "Level 2" 1 "Level 1" 0 "No Request" ;
VAL_ 165 ivi_4wdModeSet 3 "AWD" 2 "RWD" 1 "FWD" 0 "NO Req" ;
VAL_ 165 ivi_ChargeCancel 1 "CANCEL" 0 "NO_REQUEST" ;
VAL_ 165 ivi_RegenModeSet 7 "Reserved" 6 "Reserved" 5 "Reserved" 4 "Strong Recovery" 3 "NORMAL" 2 "LOW" 1 "OFF" 0 "NO REQ" ;
VAL_ 165 ivi_maxChargeCurrentSet 63 "Invalid" ;
VAL_ 165 ivi_TowModeSet 2 "TOW_MODE_ON" 1 "TOW_MODE_OFF" 0 "NO_REQUEST" ;
VAL_ 165 ivi_maxChrgSocSet 255 "Invalid" 254 "No Request" ;
VAL_ 165 ivi_chargeFormSet 3 "RESERVE_CHRGFORM1" 2 "TIMING_CHARGE" 1 "IMMEDIATE_CHARGE" 0 "NO_REQUEST" ;
VAL_ 165 ivi_ChargeEnable 1 "ENABLE" 0 "NO_REQUEST" ;
VAL_ 165 ivi_highwayModeRequest 3 "INVALID" 2 "ON" 1 "OFF" 0 "NO  Request" ;
VAL_ 165 ivi_chargeSetValid 1 "VALID" 0 "INVALID" ;
VAL_ 165 ivi_ChargeEndTimeHour 15 "Invalid" 12 "12" 11 "11" 10 "10" 9 "9" 8 "8" 7 "7" 6 "6" 5 "5" 4 "4" 3 "3" 2 "2" 1 "1" 0 "Reserved" ;
VAL_ 165 ivi_ChargeStartTimeHour 15 "Invalid" 12 "12" 11 "11" 10 "10" 9 "9" 8 "8" 7 "7" 6 "6" 5 "5" 4 "4" 3 "3" 2 "2" 1 "1" 0 "No Request" ;
VAL_ 165 ivi_ChargeEndTimeHalfDay 1 "AFTERNOON" 0 "MORNING" ;
VAL_ 165 ivi_ChargeStartTimeHalfDay 1 "AFTERNOON" 0 "MORNING" ;
VAL_ 165 ivi_ChargeEndTimeMinute 63 "No Request" ;
VAL_ 165 ivi_ChargeStartTimeMinute 63 "No Request" ;
VAL_ 165 ivi_ResetCurrentTrip 1 "REQUEST" 0 "NO_REQUEST" ;
VAL_ 165 ivi_BCMEBSHvoffset 3 "INVALID" 2 "ON" 1 "OFF" 0 "NO  Request" ;
VAL_ 165 ivi_ChargeEndTimeValid 1 "VALID" 0 "INVALID" ;
VAL_ 165 ivi_ChargeStartTimeValid 1 "VALID" 0 "INVALID" ;
VAL_ 165 ivi_driveModeSet 7 "Reserved" 6 "Reserved" 5 "INDIVIDUAL" 4 "OFFROAD" 3 "SPORT" 2 "COMFORT" 1 "ECO" 0 "NO  Request" ;
VAL_ 197 ivi_reservationChargeModeSet 1 "Cycle" 0 "No Cycle" ;
VAL_ 197 ivi_wcmOnOffSet 3 "INVALID" 2 "ON" 1 "OFF" 0 "NO  Request" ;
VAL_ 197 ivi_vspOnOffSet 3 "INVALID" 2 "ON" 1 "OFF" 0 "NO  Request" ;
VAL_ 197 ivi_weightlowFrqSet 31 "No Command" 30 "Reserved" 29 "Reserved" 28 "Reserved" 27 "Reserved" 26 "Reserved" 25 "Reserved" 24 "Reserved" 23 "Reserved" 22 "Reserved" 21 "Reserved" 20 "10" 19 "9" 18 "8" 17 "7" 16 "6" 15 "5" 14 "4" 13 "3" 12 "2" 11 "1" 10 "0" 9 "-1" 8 "-2" 7 "-3" 6 "-4" 5 "-5" 4 "-6" 3 "-7" 2 "-8" 1 "-9" 0 "-10" ;
VAL_ 197 ivi_etcBTReq 1 "Request" 0 "No request" ;
VAL_ 245 ivi_autoEasyEntrySet 3 "INVALID" 2 "ON" 1 "OFF" 0 "NO  Request" ;
VAL_ 245 ivi_drSeatHeatOnOffSet 3 "INVALID" 2 "ON" 1 "OFF" 0 "NO  Request" ;
VAL_ 245 ivi_drSeatVentOnOffSet 3 "INVALID" 2 "ON" 1 "OFF" 0 "NO  Request" ;
VAL_ 245 ivi_drSeatMassOnOffSet 3 "INVALID" 2 "ON" 1 "OFF" 0 "NO  Request" ;
VAL_ 245 ivi_drSeatHeatLevelSet 7 "ERROR" 3 "LEVEL_3" 2 "LEVEL_2" 1 "LEVEL_1" 0 "No req" ;
VAL_ 245 ivi_drSeatVentLevelSet 7 "ERROR" 3 "LEVEL_3" 2 "LEVEL_2" 1 "LEVEL_1" 0 "No req" ;
VAL_ 245 ivi_passSeatHeatOnOffSet 3 "INVALID" 2 "ON" 1 "OFF" 0 "NO  Request" ;
VAL_ 245 ivi_passSeatVentOnOffSet 3 "INVALID" 2 "ON" 1 "OFF" 0 "NO  Request" ;
VAL_ 245 ivi_passSeatHeatLevelSet 7 "INVALID" 3 "Level 3" 2 "Level 2" 1 "Level 1" 0 "NO_COMMAND" ;
VAL_ 245 ivi_passSeatVentLevelSet 7 "ERROR" 3 "LEVEL_3" 2 "LEVEL_2" 1 "LEVEL_1" 0 "No req" ;
VAL_ 245 ivi_passSeatMassOnOffSet 3 "INVALID" 2 "ON" 1 "OFF" 0 "NO  Request" ;
VAL_ 245 ivi_drSeatMassLevelSet 7 "ERROR" 6 "RESERVED" 5 "LEVEL_5" 4 "LEVEL_4" 3 "LEVEL_3" 2 "LEVEL_2" 1 "LEVEL_1" 0 "No req" ;
VAL_ 245 ivi_passSeatMassLevelSet 7 "ERROR" 6 "RESERVED" 5 "LEVEL_5" 4 "LEVEL_4" 3 "LEVEL_3" 2 "LEVEL_2" 1 "LEVEL_1" 0 "No req" ;
VAL_ 245 ivi_MirrorAutoFoldUnfoldSet 3 "INVALID" 2 "ON" 1 "OFF" 0 "NO  Request" ;
VAL_ 245 ivi_easyEntrySet 3 "Invalid" 2 "Enable" 1 "Disable" 0 "No  request" ;
VAL_ 245 ivi_dsmSetMemoryReq 7 "Reserved" 6 "Reserved" 5 "5 POSITION" 4 "4 POSITION" 3 "3 POSITION" 2 "2 POSITION" 1 "1 POSITION" 0 "NO REQUEST" ;
VAL_ 245 ivi_dsmGetMemoryReq 7 "Reserved" 6 "Reserved" 5 "5 POSITION" 4 "4 POSITION" 3 "3 POSITION" 2 "2 POSITION" 1 "1 POSITION" 0 "NO REQUEST" ;
VAL_ 245 ivi_rvMirrorAutoTurnDownSet 3 "INVALID" 2 "ON" 1 "OFF" 0 "NO  Request" ;
VAL_ 245 ivi_DrMassgIntenSet 3 "High Intensity" 2 "Normal Intensity" 1 "Weak Intensity" 0 "NO  Request" ;
VAL_ 245 ivi_PsgMassgIntenSet 3 "High Intensity" 2 "Normal Intensity" 1 "Weak Intensity" 0 "NO  Request" ;
VAL_ 245 ivi_manualEasyOutSw 3 "INVALID" 2 "ON" 1 "OFF" 0 "NO  Request" ;
VAL_ 245 ivi_potPositionStsSet 15 "Reserved" 14 "Reserved" 13 "Reserved" 12 "Reserved" 11 "Reserved" 10 "Reserved" 9 "Reserved" 8 "Reserved" 7 "100%" 6 "90%" 5 "80%" 4 "70%" 3 "60%" 2 "50%" 1 "40%" 0 "No request" ;
VAL_ 245 ivi_welcomeOnOffSet 15 "Reserved" 14 "Reserved" 13 "Reserved" 12 "Reserved" 11 "Mode10" 10 "Mode9" 9 "Mode8" 8 "Mode7" 7 "Mode6" 6 "Mode5" 5 "Mode4" 4 "Mode3" 3 "Mode2" 2 "Mode1" 1 "OFF" 0 "Default" ;
VAL_ 245 ivi_welcomeSetEnable 3 "INVALID" 2 "Enable" 1 "Disable" 0 "NO  Request" ;
VAL_ 261 ivi_dvrDisplayReq 3 "hint" 2 "Exit Req" 1 "Enter Req" 0 "NO Request" ;
VAL_ 261 ivi_dvrCoTouchMotion 3 "No Request" 2 "Reserve" 1 "TOUCH_DOWN" 0 "RELEASE" ;
VAL_ 261 ivi_dvrXCoordinate 4095 "No Request" ;
VAL_ 261 ivi_dvrYCoordinate 1023 "No Request" ;
VAL_ 261 ivi_roaDisplayReq 3 "INVALID" 2 "Exit Req" 1 "Enter Req" 0 "NO  Request" ;
VAL_ 261 ivi_ICMpressphtoresp 3 "Invalid" 2 "Fail" 1 "OK" 0 "No Request" ;
VAL_ 261 ivi_dmsWearyAssisSet 3 "INVALID" 2 "ON" 1 "OFF" 0 "NO Request" ;
VAL_ 261 ivi_dmsCameraCtl 3 "INVALID" 2 "ON" 1 "OFF" 0 "NO Request" ;
VAL_ 261 ivi_dmsWearySet 3 "INVALID" 2 "ON" 1 "OFF" 0 "NO Request" ;
VAL_ 261 ivi_dmsSenSet 3 "NO  Request" 2 "Reserved" 1 "Sensitive" 0 "Normal" ;
VAL_ 261 ivi_ICMBeautySet 3 "INVALID" 2 "ON" 1 "OFF" 0 "NO_COMMAND" ;
VAL_ 261 ivi_cameraChange 4 "OFF" 3 "ROA" 2 "DVR" 1 "DMS" 0 "NO_COMMAND" ;
VAL_ 261 ivi_videoCallSts 7 "Reserved" 6 "Reserved" 5 "overview Video" 4 "Rear Video" 3 "Front Video" 2 "passenger Video" 1 "Driver Video" 0 "NO Request" ;
VAL_ 261 ivi_nvsDisplay 3 "hint" 2 "not Display" 1 "Display" 0 "Defult" ;
VAL_ 261 ivi_nvsOCRPress 3 "Reserved" 2 "ON" 1 "OFF" 0 "NO  Request" ;
VAL_ 261 ivi_ArdisplayReq 3 "INVALID" 2 "ON" 1 "OFF" 0 "NO  Request" ;
VAL_ 261 ivi_dvrPhotoReceive 1 "Active" 0 "Not Active" ;
VAL_ 261 ivi_dvrVideoReceive 1 "Active" 0 "Not Active" ;
VAL_ 261 ivi_roaCameraCtl 1 "Request" 0 "Not Request" ;
VAL_ 261 ivi_tspUploadSts 3 "Failed" 2 "Success" 1 "Uploading" 0 "No upload" ;
VAL_ 270 ivi_AVMTrigByTurnningSts 1 "Press" 0 "No Press" ;
VAL_ 270 ivi_AVMViewModeSw 1 "Press" 0 "No Press" ;
VAL_ 270 ivi_modeSw 1 "Quit AVM" 0 "No request" ;
VAL_ 270 ivi_viewSw_Reserved 1 "Press" 0 "No Press" ;
VAL_ 270 ivi_screenCoordX 2047 "Invalid" ;
VAL_ 270 ivi_screenCoordY 2047 "Invalid" ;
VAL_ 270 ivi_avm_monVideoReceive 1 "Receive" 0 "No Receive" ;
VAL_ 270 ivi_MODSw 1 "Press" 0 "No Press" ;
VAL_ 270 ivi_AVMTrajectorySW 1 "Press" 0 "No Press" ;
VAL_ 270 ivi_AVMAutoswitchingSW 1 "Press" 0 "No Press" ;
VAL_ 270 ivi_AVM_transparentSW 1 "Press" 0 "No Press" ;
VAL_ 270 ivi_View_select 31 "Reserved" 30 "Reserved" 29 "Reserved" 28 "Reserved" 27 "Reserved" 26 "Reserved" 25 "Reserved" 24 "Reserved" 23 "Reserved" 22 "Reserved" 21 "Reserved" 20 "Reserved" 19 "Reserved" 18 "Reserved" 17 "Reserved" 16 "Reserved" 15 "Side View press" 14 "2D Dynamic rear view press" 13 "2D Dynamic front view press" 12 "3D Rear-Right view press" 11 "3D Rear-Left view press" 10 "3D Front-Right view press" 9 "3D Front-Left view press" 8 "3D Right side view press" 7 "3D Left side view press" 6 "3D Top view of the trail press" 5 "3D Top view of the head press" 4 "2D Right view press" 3 "2D Left view press" 2 "2D Rear view press" 1 "2D Front view press" 0 "No request" ;
VAL_ 270 IVI_Voice_AVMOnOffReq 3 "Reserved" 2 "OFF" 1 "ON" 0 "No Request" ;
VAL_ 270 ivi_touchScreenCtrl 15 "Reserved" 14 "Reserved" 13 "Reserved" 12 "Reserved" 11 "Reserved" 10 "Reserved" 9 "Reserved" 8 "Reserved" 7 "Reserved" 6 "Reserved" 5 "Reserved" 4 "Reserved" 3 "Screen release（释放）" 2 "Screen hold（长按）" 1 "Screen touched（单击）" 0 "No command" ;
VAL_ 270 ivi_naviSts 3 "Reserved" 2 "Background" 1 "Foreground" 0 "No Request" ;
VAL_ 270 IVI_Voice_APAOnOffReq 3 "Reserved" 2 "OFF" 1 "ON" 0 "No Request" ;
VAL_ 270 IVI_Voice_CarbodyTransparentReq 3 "Reserved" 2 "OFF" 1 "ON" 0 "No Request" ;
VAL_ 286 ivi_vehicleSpeedCompModeReq 3 "Reserved" 2 "On" 1 "Off" 0 "No Request" ;
VAL_ 286 ivi_highFrqSet 31 "No Command" 30 "Reserved" 29 "Reserved" 28 "Reserved" 27 "Reserved" 26 "Reserved" 25 "Reserved" 24 "Reserved" 23 "Reserved" 22 "Reserved" 21 "Reserved" 20 "10" 19 "9" 18 "8" 17 "7" 16 "6" 15 "5" 14 "4" 13 "3" 12 "2" 11 "1" 10 "0" 9 "-1" 8 "-2" 7 "-3" 6 "-4" 5 "-5" 4 "-6" 3 "-7" 2 "-8" 1 "-9" 0 "-10" ;
VAL_ 286 ivi_mediaVolSet 63 "No Request" 62 "Reserved" 61 "Reserved" 60 "Reserved" 59 "Reserved" 58 "Reserved" 57 "Reserved" 56 "Reserved" 55 "Reserved" 54 "Reserved" 53 "Reserved" 52 "Reserved" 51 "Reserved" 50 "Reserved" 49 "Reserved" 48 "Reserved" 47 "Reserved" 46 "Reserved" 45 "Reserved" 44 "Reserved" 43 "Reserved" 42 "Reserved" 41 "Reserved" 40 "Reserved" 39 "Reserved" 38 "Reserved" 37 "Reserved" 36 "Reserved" 35 "Reserved" 34 "Reserved" 33 "Reserved" 32 "Reserved" 31 "Reserved" 30 "30" 29 "29" 28 "28" 27 "27" 26 "26" 25 "25" 24 "24" 23 "23" 22 "22" 21 "21" 20 "20" 19 "19" 18 "18" 17 "17" 16 "16" 15 "15" 14 "14" 13 "13" 12 "12" 11 "11" 10 "10" 9 "9" 8 "8" 7 "7" 6 "6" 5 "5" 4 "4" 3 "3" 2 "2" 1 "1" 0 "0" ;
VAL_ 286 ivi_muteAllSpeakers 3 "No Command" 2 "Mute A2B Channel 3,4,5,6" 1 "Mute all speakers (All A2B channels)" 0 "Unmute all speakers" ;
VAL_ 286 ivi_midFrqSet 31 "No Command" 30 "Reserved" 29 "Reserved" 28 "Reserved" 27 "Reserved" 26 "Reserved" 25 "Reserved" 24 "Reserved" 23 "Reserved" 22 "Reserved" 21 "Reserved" 20 "10" 19 "9" 18 "8" 17 "7" 16 "6" 15 "5" 14 "4" 13 "3" 12 "2" 11 "1" 10 "0" 9 "-1" 8 "-2" 7 "-3" 6 "-4" 5 "-5" 4 "-6" 3 "-7" 2 "-8" 1 "-9" 0 "-10" ;
VAL_ 286 ivi_lowFrqSet 31 "No Command" 30 "Reserved" 29 "Reserved" 28 "Reserved" 27 "Reserved" 26 "Reserved" 25 "Reserved" 24 "Reserved" 23 "Reserved" 22 "Reserved" 21 "Reserved" 20 "10" 19 "9" 18 "8" 17 "7" 16 "6" 15 "5" 14 "4" 13 "3" 12 "2" 11 "1" 10 "0" 9 "-1" 8 "-2" 7 "-3" 6 "-4" 5 "-5" 4 "-6" 3 "-7" 2 "-8" 1 "-9" 0 "-10" ;
VAL_ 286 ivi_amp_dyaudioSoundFeature 7 "No Request" 6 "Reserved" 5 "Reserved" 4 "Reserved" 3 "Speech mode" 2 "Soft mode" 1 "Dynamic mode" 0 "Original sound mode" ;
VAL_ 286 ivi_loudnessOnOffSet 3 "No Request" 2 "Reserved" 1 "Off" 0 "On" ;
VAL_ 286 ivi_soundFieldSet 7 "Reserved" 6 "Reserved" 5 "Reserved" 4 "Back row passenger" 3 "Front passenger" 2 "Driver" 1 "All passenger" 0 "No command" ;
VAL_ 286 ivi_audioBlcSet 31 "No Command" 30 "Reserved" 29 "Reserved" 28 "Reserved" 27 "Reserved" 26 "Reserved" 25 "Reserved" 24 "Reserved" 23 "Reserved" 22 "Reserved" 21 "Reserved" 20 "Right+10" 19 "Right+9" 18 "Right+8" 17 "Right+7" 16 "Right+6" 15 "Right+5" 14 "Right+4" 13 "Right+3" 12 "Right+2" 11 "Right+1" 10 "Center" 9 "Left+1" 8 "Left+2" 7 "Left+3" 6 "Left+4" 5 "Left+5" 4 "Left+6" 3 "Left+7" 2 "Left+8" 1 "Left+9" 0 "Left+10" ;
VAL_ 286 ivi_audioFaderSet 31 "No Command" 30 "Reserved" 29 "Reserved" 28 "Reserved" 27 "Reserved" 26 "Reserved" 25 "Reserved" 24 "Reserved" 23 "Reserved" 22 "Reserved" 21 "Reserved" 20 "Front+10" 19 "Front+9" 18 "Front+8" 17 "Front+7" 16 "Front+6" 15 "Front+5" 14 "Front+4" 13 "Front+3" 12 "Front+2" 11 "Front+1" 10 "Center" 9 "Rear+1" 8 "Rear+2" 7 "Rear+3" 6 "Rear+4" 5 "Rear+5" 4 "Rear+6" 3 "Rear+7" 2 "Rear+8" 1 "Rear+9" 0 "Rear+10" ;
VAL_ 446 ivi_epsModeSet 3 "SPORT" 2 "COMFORT" 1 "Reserved" 0 "NO  Request" ;
VAL_ 446 ivi_escOffSw 3 "INVALID" 2 "OFF" 1 "ON" 0 "No Request" ;
VAL_ 446 ivi_hdcOnOffSet 3 "INVALID" 2 "OFF" 1 "ON" 0 "No Request" ;
VAL_ 446 ivi_aebOnOffSet 3 "INVALID" 2 "OFF" 1 "ON" 0 "No Request" ;
VAL_ 446 ivi_iBModeSet 3 "INVALID" 2 "SPORT" 1 "COMFORT" 0 "NO  Request" ;
VAL_ 446 ivi_lksSensitivitySet 3 "reserved" 2 "highSensitivity" 1 "lowSensitivity" 0 "NO  Request" ;
VAL_ 446 ivi_lcaBsdOnOffSet 3 "INVALID" 2 "OFF" 1 "ON" 0 "No Request" ;
VAL_ 446 ivi_rctaOnOffSet 3 "INVALID" 2 "OFF" 1 "ON" 0 "No Request" ;
VAL_ 446 ivi_dowOnOffSet 3 "INVALID" 2 "OFF" 1 "ON" 0 "No Request" ;
VAL_ 446 ivi_startRevSOCSet 63 "INVALID" 0 "NO  Request" ;
VAL_ 446 ivi_speedLimitWarningMode 3 "INVALID" 2 "ON with voice" 1 "ON without voice" 0 "No Request" ;
VAL_ 446 ivi_ISAOnOffSet 3 "INVALID" 2 "OFF" 1 "ON" 0 "No Request" ;
VAL_ 446 ivi_currentRoadType 15 "No Request" 14 "Reserved" 13 "Reserved" 12 "Reserved" 11 "Reserved" 10 "NonnavigationalRoad" 9 "GeneralRoad" 8 "SecondaryRoad" 7 "UrbanMajorRoad" 6 "CityExpressway" 5 "ViliageRoad" 4 "TownshipRoad" 3 "CountyHighway" 2 "ProvincialHighway" 1 "NationalHighway" 0 "Expressway" ;
VAL_ 446 ivi_countryCodeSet 44 "CHINA" 0 "UNKNOWN" ;
VAL_ 446 ivi_FrtVehStrReminderSw 3 "reserved" 2 "ON" 1 "OFF" 0 "NO  Request" ;
VAL_ 446 ivi_speedLimitUnitSet 3 "INVALID" 2 "KPH" 1 "MPH" 0 "NO  Request" ;
VAL_ 446 ivi_speedLimitStsSet 3 "SL_PLURUAL" 2 "SL_NOLIMIT" 1 "SL_EXISTS" 0 "SL_UNKNOWN" ;
VAL_ 446 ivi_propModeSet 3 "SPORT" 2 "STANDARD" 1 "ECO" 0 "NO  Request" ;
VAL_ 446 ivi_pcwOnOffSet 3 "INVALID" 2 "OFF" 1 "ON" 0 "No Request" ;
VAL_ 446 ivi_torqueDistModeSet 3 "INVALID" 2 "SPORT" 1 "AUTO" 0 "No Request" ;
VAL_ 446 ivi_rcwOnOffSet 3 "INVALID" 2 "OFF" 1 "ON" 0 "No Request" ;
VAL_ 446 ivi_trailerModeOnOffSet 3 "RESERVED" 2 "TRAILER_MODE_ON" 1 "TRAILER_MODE_OFF" 0 "NO  Request" ;
VAL_ 446 ivi_esc_epbButtonRelease 1 "REQUEST" 0 "NO REQUEST" ;
VAL_ 469 ivi_ASCMaintainModeReq 3 "INVALID" 2 "ON" 1 "OFF" 0 "NO  Request" ;
VAL_ 469 ivi_laneAssistFuncSet 7 "Invalid" 6 "Reserved" 5 "Reserved" 4 "LDW+LCC" 3 "LDW+LKA" 2 "LDW" 1 "OFF" 0 "No Req" ;
VAL_ 469 ivi_lasWarningModeSelection 7 "No Request" 6 "Reserved" 5 "Reserved" 4 "Reserved" 3 "Voice+Voice+Vibration" 2 "Voice+Vibration" 1 "Vision+Voice" 0 "Only Vision" ;
VAL_ 469 ivi_EmergencyHvOffRequest 1 "REQUEST" 0 "NO_REQUEST" ;
VAL_ 497 ivi_faceIDSet 3 "INVALID" 2 "ON" 1 "OFF" 0 "NO Request" ;
VAL_ 497 ivi_gestureIDSet 3 "INVALID" 2 "ON" 1 "OFF" 0 "NO Request" ;
VAL_ 497 ivi_dmsFaceIDRegiReq 3 "Abort" 2 "Retry" 1 "Start" 0 "No Request" ;
VAL_ 497 ivi_FaceIDLoginReq 3 "Reserved" 2 "Scanning Failed" 1 "Start Scanning" 0 "No Request" ;
VAL_ 497 ivi_dmsRegiFaceID 15 "Reserved" 14 "Reserved" 13 "Reserved" 12 "Reserved" 11 "Unkown" 10 "Driver10" 9 "Driver9" 8 "Driver8" 7 "Driver7" 6 "Driver6" 5 "Driver5" 4 "Driver4" 3 "Driver3" 2 "Driver2" 1 "Driver1" 0 "No Request" ;
VAL_ 497 ivi_dmsDeleteFaceID 15 "Reserved" 14 "Reserved" 13 "Reserved" 12 "Reserved" 11 "Unkown" 10 "Driver10" 9 "Driver9" 8 "Driver8" 7 "Driver7" 6 "Driver6" 5 "Driver5" 4 "Driver4" 3 "Driver3" 2 "Driver2" 1 "Driver1" 0 "No Request" ;
VAL_ 497 ivi_FaceIDEmptydataResp 1 "Active" 0 "Inactive" ;
VAL_ 497 ivi_dmsRegiFaceIDSts 3 "Reserved" 2 "Fail" 1 "Success" 0 "NO Request" ;
VAL_ 766 ic_totalMileage 16777215 "Invalid" ;
VAL_ 766 ic_lowSocIndication 1 "ACTIVE(20% SOC)" 0 "INACTIVE" ;
VAL_ 766 ic_displayFail 1 "FAULT" 0 "NORMAL" ;
VAL_ 766 ic_qDashACCFail 3 "Reserved" 2 "Reserved" 1 "ERROR" 0 "NO_ERROR" ;
VAL_ 766 ic_RemainingMileage 1023 "Invalid" ;
VAL_ 766 ic_brakeFluidLevel 1 "LEVEL_LOW" 0 "NORMAL" ;
VAL_ 766 ic_totalMileageValid 1 "VALID" 0 "INVALID" ;
VAL_ 766 ic_vehicleSpeedDispValid 1 "VALID" 0 "INVALID" ;
VAL_ 849 ivi_dsSeatBackPos 255 "Invalid" 254 "No Request" ;
VAL_ 849 ivi_dsSeatSlidePos 255 "Invalid" 254 "No Request" ;
VAL_ 849 ivi_dsSeatHeightPos 255 "Invalid" 254 "No Request" ;
VAL_ 849 ivi_dsSeatCushionAnglePos 255 "Invalid" 254 "No Request" ;
VAL_ 849 ivi_LeftMirrorVerticalPos 255 "Invalid" 254 "No Request" ;
VAL_ 849 ivi_LeftMirrorHorizontalPos 255 "Invalid" 254 "No Request" ;
VAL_ 849 ivi_RightMirrorVerticalPos 255 "Invalid" 254 "No Request" ;
VAL_ 849 ivi_RightMirrorHorizontalPos 255 "Invalid" 254 "No Request" ;
VAL_ 850 ivi_dsSeatBackPos2 255 "Invalid" 254 "No Request" ;
VAL_ 850 ivi_dsSeatSlidePos2 255 "Invalid" 254 "No Request" ;
VAL_ 850 ivi_dsSeatHeightPos2 255 "Invalid" 254 "No Request" ;
VAL_ 850 ivi_dsSeatCushionAnglePos2 255 "Invalid" 254 "No Request" ;
VAL_ 850 ivi_LeftMirrorVerticalPos2 255 "Invalid" 254 "No Request" ;
VAL_ 850 ivi_LeftMirrorHorizontalPos2 255 "Invalid" 254 "No Request" ;
VAL_ 850 ivi_RightMirrorVerticalPos2 255 "Invalid" 254 "No Request" ;
VAL_ 850 ivi_RightMirrorHorizontalPos2 255 "Invalid" 254 "No Request" ;
VAL_ 851 ivi_dsSeatBackPos3 255 "Invalid" 254 "No Request" ;
VAL_ 851 ivi_dsSeatSlidePos3 255 "Invalid" 254 "No Request" ;
VAL_ 851 ivi_dsSeatHeightPos3 255 "Invalid" 254 "No Request" ;
VAL_ 851 ivi_dsSeatCushionAnglePos3 255 "Invalid" 254 "No Request" ;
VAL_ 851 ivi_LeftMirrorVerticalPos3 255 "Invalid" 254 "No Request" ;
VAL_ 851 ivi_LeftMirrorHorizontalPos3 255 "Invalid" 254 "No Request" ;
VAL_ 851 ivi_RightMirrorVerticalPos3 255 "Invalid" 254 "No Request" ;
VAL_ 851 ivi_RightMirrorHorizontalPos3 255 "Invalid" 254 "No Request" ;
VAL_ 949 ivi_hvacOnOffReq 1 "KEY_PRESS" 0 "INVALID" ;
VAL_ 949 ivi_hvacAutoModeReq 1 "KEY_PRESS" 0 "INVALID" ;
VAL_ 949 ivi_hvacRecircModeReq 1 "KEY_PRESS" 0 "INVALID" ;
VAL_ 949 ivi_hvacModeReq 7 "No Request" 4 "DEFROST" 3 "FOOT_AND_DEFROST" 2 "FOOT" 1 "FACE_AND_FOOT" 0 "FACE" ;
VAL_ 949 ivi_driverTempCSet 31 "No Request" ;
VAL_ 949 ivi_passengerTempCSet 31 "No Request" ;
VAL_ 949 ivi_hvacDualMode 1 "KEY_PRESS" 0 "INVALID" ;
VAL_ 949 ivi_acReq 1 "KEY_PRESS" 0 "INVALID" ;
VAL_ 949 ivi_pm25StsReq 1 "KEY_PRESS" 0 "INVALID" ;
VAL_ 949 ivi_acWorkModeSet 3 "强劲" 2 "正常" 1 "轻柔" 0 "No Request" ;
VAL_ 949 ivi_acDiagReq 1 "REQUEST" 0 "INVALID" ;
VAL_ 949 IVI_Backlightadjust 15 "Invalid" 14 "Reserved" 13 "Reserved" 12 "Reserved" 11 "Reserved" 10 "Level 10" 9 "Level 9" 8 "Level 8" 7 "Level 7" 6 "Level 6" 5 "Level 5" 4 "Level 4" 3 "Level 3" 2 "Level 2" 1 "Level 1" 0 "No Action" ;
VAL_ 949 IVI_FreshAirModeSet 1 "KEY_PRESS" 0 "INVALID" ;
VAL_ 949 IVI_VentilationCoolSet 1 "KEY_PRESS" 0 "INVALID" ;
VAL_ 949 ivi_frontDefrostCtrl 1 "KEY_PRESS" 0 "INVALID" ;
VAL_ 949 ivi_languageSet 3 "NO_COMMAND" 2 "RESERVED" 1 "ENGLISH" 0 "SIMPLIFIED_CHINESE" ;
VAL_ 949 ivi_unitSet 3 "INVALID" 2 "NO  Request" 1 "MILE" 0 "KM" ;
VAL_ 949 ivi_hvacBlowLvReq 8 "LEVEL_7" 7 "LEVEL_6" 6 "LEVEL_5" 5 "LEVEL_4" 4 "LEVEL_3" 3 "LEVEL_2" 2 "LEVEL_1" 1 "OFF" 0 "Default" ;
VAL_ 949 IVI_Sunroof_HorizontalControl 127 "No Request" ;
VAL_ 1011 IC_MaintenanceMileage 65535 "Invalid" ;
VAL_ 1011 ic_lastingtime 2047 "Invalid" ;
VAL_ 1011 ic_mileageSincethelastcharge 16383 "Invalid" ;
VAL_ 1011 ic_tripmeterThisMoment 16383 "Invalid" ;
VAL_ 1011 IC_MaintenanceReset 1 "Request" 0 "No Request" ;
VAL_ 1248 ic_totalMileageRev 16777215 "Invalid" ;
VAL_ 1013 IC_TripBAvgPwrConsum 1023 "Invalid" ;
VAL_ 1013 IC_TripAAvgPwrConsum 1023 "Invalid" ;
VAL_ 1013 IC_SinceChargeAvgPwrConsum 1023 "Invalid" ;
VAL_ 1013 IC_CurrentTripAvgPwrConsum 1023 "Invalid" ;
VAL_ 1022 ivi_timeValid 1 "VALID" 0 "INVALID" ;
VAL_ 1022 ivi_altitude 127 "Invalid" ;
VAL_ 1154 IC_FuelConsump 1023 "Invalid" ;
VAL_ 1154 IC_ConsumpRatioInstant 1535 "Invalid" ;
VAL_ 1154 ic_oilPercentFail 3 "SHORT_POWER_OR_OPEN_CIRCURT" 2 "OUT_RANGE" 1 "SHORT_GROUND" 0 "NORMAL" ;
VAL_ 1154 IC_OilRemainingMileage 1023 "Invalid" ;
VAL_ 1154 ic_oilPercent 255 "Invalid" ;
VAL_ 1170 ic_tripmeterA 16383 "Invalid" ;
VAL_ 1170 ic_maintenanceInd 1 "INDICATION" 0 "NO_INDICATION" ;
VAL_ 1170 ic_tripmeterB 16777215 "Invalid" ;
VAL_ 1170 IC_ChargingPower 8191 "Invalid" ;
VAL_ 1170 IC_ChargingSpeed 2047 "Invalid" ;
VAL_ 1173 IVI_FrameType 2 "IVI_ACK" 1 "IVI_Status" 0 "INVALID" ;
VAL_ 1173 IVI_WorkSts 3 "IVI start incomplete(启动未完成)" 2 "IVI abnormal work (异常工作)" 1 "IVI normal work (正常工作)" 0 "INVALID" ;
VAL_ 1173 IVI_CurrentVideo 11 "No LVDS video 无LVDS视频" 10 "Online radio 在线电台" 9 "Local radio 本地电台" 8 "IPod music IPod音乐" 7 "Online music 在线按音乐" 6 "Bluetooth music 蓝牙音乐" 5 "USB music USB音乐" 4 "Telephone_record 电话_通话记录" 3 "Telephone_personal collection电话_个人收藏" 2 "Small navigation 小导航" 1 "Large navigation (full screen)大导航（全屏）" 0 "INVALID" ;
VAL_ 1173 IVI_EventNotify 4 "Phone hang up 电话挂断" 3 "In the call 通话中" 2 "Call 去电" 1 "Incoming call 来电" 0 "INVALID" ;
VAL_ 1173 IVI_IC_Sync 3 "INVALID" 2 "Full screen navigation syn 全屏导航同步" 1 "Cancel full screen syn 取消全屏同步" 0 "No COMMAND" ;
VAL_ 1173 ivi_highwayType 1 "Highway" 0 "Not highway" ;
VAL_ 1264 IC_TripALastingTime 8191 "Invalid" ;
VAL_ 1264 IC_TripAAvgSpeed 511 "Invalid" ;
VAL_ 1264 IC_TripBLastingTime 8191 "Invalid" ;
VAL_ 1264 IC_TripBAavSpeed 511 "Invalid" ;
VAL_ 1264 IC_TripBAvgOilConsum 255 "Invalid" ;
VAL_ 1264 IC_TripAAvgOilConsum 255 "Invalid" ;
VAL_ 1265 IC_SinceChargeAvgSpd 511 "Invalid" ;
VAL_ 1265 IC_SinceChargeTime 8191 "Invalid" ;
VAL_ 1265 IC_SinceChargeAvgOIilConsum 255 "Invalid" ;
VAL_ 1265 IC_CurrentTripAAvgOilConsum 255 "Invalid" ;
VAL_ 1265 IC_CurrentTripAvgSpd 511 "Invalid" ;
VAL_ 1573 IVI_RMR 1 "Repeat Message State requested" 0 "Repeat Message State not requested" ;
VAL_ 1573 IVI_AWB 1 "Node has woken up the network (active Wakeup)" 0 "Node has not woken up the network (passive wakeup)" ;
VAL_ 774 nvs_Sts 3 "FAULT" 2 "Active" 1 "STANDBY" 0 "default" ;
VAL_ 774 nvs_ocrSts 3 "INVALID" 2 "ON" 1 "OFF" 0 "default" ;
VAL_ 774 nvs_displayReq 3 "hint" 2 "Exit Rec" 1 "Enter Rec" 0 "default" ;
VAL_ 774 nvs_warnningSts 1 "warn_ON" 0 "warn_OFF" ;
VAL_ 774 nvs_cameraSts 3 "Error" 2 "Block" 1 "Normal" 0 "OFF" ;
VAL_ 774 nvs_leltLEDSts 3 "Error" 2 "Block" 1 "Normal" 0 "OFF" ;
VAL_ 774 nvs_rightLEDSts 3 "Error" 2 "Block" 1 "Normal" 0 "OFF" ;
VAL_ 774 nvs_textPrompt 7 "INVALID" 6 "Beam" 5 "overexposure" 4 "insufficient light" 3 "Error" 2 "Block" 1 "display" 0 "OFF" ;
VAL_ 774 nvs_warningType 7 "unknown" 6 "Truck" 5 "Bus" 4 "Van" 3 "Vehicle" 2 "Two-wheeler" 1 "Pedestrian" 0 "Defult" ;
VAL_ 774 nvs_warningSpeed 255 "Invalid" ;
VAL_ 774 nvs_warningDistance 255 "Invalid" ;
VAL_ 416 pdc_rearMidleftRegObjSts 30 "Error" 25 "150cm" 24 "145cm" 23 "140cm" 22 "135cm" 21 "130cm" 20 "125cm" 19 "120cm" 18 "115cm" 17 "110cm" 16 "105cm" 15 "100cm" 14 "95cm" 13 "90cm" 12 "85cm" 11 "80cm" 10 "75cm" 9 "70cm" 8 "65cm" 7 "60cm" 6 "55cm" 5 "50cm" 4 "45cm" 3 "40cm" 2 "35cm" 1 "≤30cm" 0 "No Object" ;
VAL_ 416 pdc_sysSts 2 "Failed" 1 "Active" 0 "Inactive" ;
VAL_ 416 pdc_failureWarning 1 "Warning on" 0 "No warning" ;
VAL_ 416 pdc_rearLeftRegObjSts 30 "Error" 25 "150cm" 24 "145cm" 23 "140cm" 22 "135cm" 21 "130cm" 20 "125cm" 19 "120cm" 18 "115cm" 17 "110cm" 16 "105cm" 15 "100cm" 14 "95cm" 13 "90cm" 12 "85cm" 11 "80cm" 10 "75cm" 9 "70cm" 8 "65cm" 7 "60cm" 6 "55cm" 5 "50cm" 4 "45cm" 3 "40cm" 2 "35cm" 1 "≤30cm" 0 "No Object" ;
VAL_ 416 pdc_OnOffSts 3 "PAS SW Inhibited" 2 "PAS SW OFF" 1 "PAS SW ON" 0 "Invalid" ;
VAL_ 416 pdc_frontLeftRegObjSts 30 "Error" 25 "150cm" 24 "145cm" 23 "140cm" 22 "135cm" 21 "130cm" 20 "125cm" 19 "120cm" 18 "115cm" 17 "110cm" 16 "105cm" 15 "100cm" 14 "95cm" 13 "90cm" 12 "85cm" 11 "80cm" 10 "75cm" 9 "70cm" 8 "65cm" 7 "60cm" 6 "55cm" 5 "50cm" 4 "45cm" 3 "40cm" 2 "35cm" 1 "≤30cm" 0 "No Object" ;
VAL_ 416 pdc_audibleFrontBeepRate 7 "Reserved" 6 "Reserved" 5 "Reserved" 4 "Warning on" 3 "4 Hz" 2 "2 Hz" 1 "1 Hz" 0 "No warning" ;
VAL_ 416 pdc_rearRightRegObjSts 30 "Error" 25 "150cm" 24 "145cm" 23 "140cm" 22 "135cm" 21 "130cm" 20 "125cm" 19 "120cm" 18 "115cm" 17 "110cm" 16 "105cm" 15 "100cm" 14 "95cm" 13 "90cm" 12 "85cm" 11 "80cm" 10 "75cm" 9 "70cm" 8 "65cm" 7 "60cm" 6 "55cm" 5 "50cm" 4 "45cm" 3 "40cm" 2 "35cm" 1 "≤30cm" 0 "No Object" ;
VAL_ 416 pdc_audibleRearBeepRate 7 "Reserved" 6 "Reserved" 5 "Reserved" 4 "Warning on" 3 "4 Hz" 2 "2 Hz" 1 "1 Hz" 0 "No warning" ;
VAL_ 416 pdc_frontRightRegObjSts 30 "Error" 25 "150cm" 24 "145cm" 23 "140cm" 22 "135cm" 21 "130cm" 20 "125cm" 19 "120cm" 18 "115cm" 17 "110cm" 16 "105cm" 15 "100cm" 14 "95cm" 13 "90cm" 12 "85cm" 11 "80cm" 10 "75cm" 9 "70cm" 8 "65cm" 7 "60cm" 6 "55cm" 5 "50cm" 4 "45cm" 3 "40cm" 2 "35cm" 1 "≤30cm" 0 "No Object" ;
VAL_ 416 pdc_frontMidLeftRegObjSts 30 "Error" 25 "150cm" 24 "145cm" 23 "140cm" 22 "135cm" 21 "130cm" 20 "125cm" 19 "120cm" 18 "115cm" 17 "110cm" 16 "105cm" 15 "100cm" 14 "95cm" 13 "90cm" 12 "85cm" 11 "80cm" 10 "75cm" 9 "70cm" 8 "65cm" 7 "60cm" 6 "55cm" 5 "50cm" 4 "45cm" 3 "40cm" 2 "35cm" 1 "≤30cm" 0 "No Object" ;
VAL_ 416 pdc_rearMidRightRegObjSts 30 "Error" 25 "150cm" 24 "145cm" 23 "140cm" 22 "135cm" 21 "130cm" 20 "125cm" 19 "120cm" 18 "115cm" 17 "110cm" 16 "105cm" 15 "100cm" 14 "95cm" 13 "90cm" 12 "85cm" 11 "80cm" 10 "75cm" 9 "70cm" 8 "65cm" 7 "60cm" 6 "55cm" 5 "50cm" 4 "45cm" 3 "40cm" 2 "35cm" 1 "≤30cm" 0 "No Object" ;
VAL_ 416 pdc_frontMidRightRegObjSts 30 "Error" 25 "150cm" 24 "145cm" 23 "140cm" 22 "135cm" 21 "130cm" 20 "125cm" 19 "120cm" 18 "115cm" 17 "110cm" 16 "105cm" 15 "100cm" 14 "95cm" 13 "90cm" 12 "85cm" 11 "80cm" 10 "75cm" 9 "70cm" 8 "65cm" 7 "60cm" 6 "55cm" 5 "50cm" 4 "45cm" 3 "40cm" 2 "35cm" 1 "≤30cm" 0 "No Object" ;
VAL_ 72 Tbox_AuthResponeStatus 95 "Authentication Failed" 245 "Busy，Tbox is calculating response" 240 "Authentication is in progress" 0 "Authentication Successed" ;
VAL_ 88 tbox_remoteLockCtrlReq 2 "LOCK" 1 "UNLOCK" 0 "NO_REQUEST" ;
VAL_ 88 tbox_remoteCarSearchReq 3 "Reserved" 2 "ON" 1 "OFF" 0 "NO_REQUEST" ;
VAL_ 88 tbox_remoteTailgateCtrlReq 2 "CLOSE" 1 "OPEN" 0 "NO_REQUEST" ;
VAL_ 88 tbox_sunroofGlassCmd 7 "STOP_SUNSHADE" 6 "CLOSE_SUNSHAGE" 5 "OPEN_SUNSHADE" 4 "TILTUP_GLASS" 3 "STOP_GLASS" 2 "CLOSE_GLASS" 1 "OPEN_GLASS" 0 "NO_CMD" ;
VAL_ 88 tbox_remoteForbiddenOn 3 "Reserved" 2 "Forbidden" 1 "Not Forbidden" 0 "No Request" ;
VAL_ 88 tbox_HornReq 3 "Reserved" 2 "On" 1 "OFF" 0 "NO_REQUEST" ;
VAL_ 88 tbox_remotePowerCtrlReq 2 "START_OFF" 1 "START_ON" 0 "NO_REQUEST" ;
VAL_ 88 tbox_remoteDrSeatHeatReq 4 "Level3" 3 "Level2" 2 "Level1" 1 "Seat Heat Off" 0 "No Request" ;
VAL_ 88 tbox_remotePassSeatHeatReq 4 "Level3" 3 "Level2" 2 "Level1" 1 "Seat Heat Off" 0 "No Request" ;
VAL_ 88 tbox_HazardLightReq 3 "Reserved" 2 "ON" 1 "OFF" 0 "No Request" ;
VAL_ 88 tbox_remoteACOnOffReq 2 "ON" 1 "OFF" 0 "NO_REQUEST" ;
VAL_ 88 tbox_remoteInfoCollectionReq 2 "Collection _OFF" 1 "Collection _ON" 0 "No Request" ;
VAL_ 88 tbox_oneTouchCoolSet 2 "Close" 1 "Open" 0 "No Request" ;
VAL_ 88 tbox_oneTouchHeatSet 2 "Close" 1 "Open" 0 "No Request" ;
VAL_ 88 tbox_remoteWinLFCtrlRqst 3 "Open" 2 "Close" 1 "Ventilate" 0 "No Request" ;
VAL_ 88 tbox_remoteWinRFCtrlRqst 3 "Open" 2 "Close" 1 "Ventilate" 0 "No Request" ;
VAL_ 88 tbox_remoteWinLRCtrlRqst 3 "Open" 2 "Close" 1 "Ventilate" 0 "No Request" ;
VAL_ 88 tbox_remoteWinRRCtrlRqst 3 "Open" 2 "Close" 1 "Ventilate" 0 "No Request" ;
VAL_ 88 tbox_lowBeamOnOffCtrl 3 "INVALID" 2 "ON" 1 "OFF" 0 "NO_COMMAND" ;
VAL_ 126 tbox_reservationChargeMode 1 "Cycle" 0 "No Cycle" ;
VAL_ 126 tbox_SysErSt 3 "Reserved" 2 "Serious Fault" 1 "Minor Fault" 0 "Noraml" ;
VAL_ 126 tbox_chargeSetValid_Reserved 1 "VALID" 0 "INVALID" ;
VAL_ 126 tbox_MaxChargeCurrentSet 63 "Invalid" ;
VAL_ 126 tbox_ChargeFormSet 3 "RESERVE_CHRGFORM1" 2 "TIMING_CHARGE" 1 "IMMEDIATE_CHARGE" 0 "NO_REQUEST" ;
VAL_ 126 tbox_ChargeEndTimeHalfDay 1 "AFTERNOON" 0 "MORNING" ;
VAL_ 126 tbox_ChargeEndTimeHour 15 "Invalid" 12 "12" 11 "11" 10 "10" 9 "9" 8 "8" 7 "7" 6 "6" 5 "5" 4 "4" 3 "3" 2 "2" 1 "1" 0 "Reserved" ;
VAL_ 126 tbox_remoteVehicleForbiddenStart 3 "INVALID" 2 "Forbidden Start" 1 "Start" 0 "NO_REQUEST" ;
VAL_ 126 tbox_ChargeEndTimeMinute 63 "INVALID" ;
VAL_ 126 tbox_ChargeCancel 1 "CANCEL" 0 "NO_REQUEST" ;
VAL_ 126 tbox_ChargeEnable 1 "ENABLE" 0 "NO_REQUEST" ;
VAL_ 126 tbox_ChargeStartTimeHalfDay 1 "AFTERNOON" 0 "MORNING" ;
VAL_ 126 tbox_ChargeStartTimeHour 15 "Invalid" 12 "12" 11 "11" 10 "10" 9 "9" 8 "8" 7 "7" 6 "6" 5 "5" 4 "4" 3 "3" 2 "2" 1 "1" 0 "Reserved" ;
VAL_ 126 tbox_EmergencyHvOffReq 1 "REQUEST" 0 "NO_REQUEST" ;
VAL_ 126 tbox_BatteryCondition_Reserved 1 "ENABLE" 0 "DISABLE" ;
VAL_ 126 tbox_MaxChargeSOCSet 127 "INVALID" ;
VAL_ 126 tbox_ChargeEndTimeValid 1 "VALID" 0 "INVALID" ;
VAL_ 126 tbox_ChargeStartTimeValid 1 "VALID" 0 "INVALID" ;
VAL_ 126 tbox_ChargeSetEnable 1 "Enable" 0 "Disable" ;
VAL_ 126 tbox_remoteengStartCmd 1 "Request" 0 "No Request" ;
VAL_ 168 tbox_dvrTakePicCtrl 7 "Reserved" 6 "DMS VIdeo" 5 "ROA video" 4 "DVR video" 3 "DMS photo" 2 "ROA photo" 1 "DVR photo" 0 "No Request" ;
VAL_ 1278 tbox_vehicleMode 15 "Invalid" 14 "Reserved" 13 "Reserved" 12 "Reserved" 11 "Reserved" 10 "Reserved" 9 "Reserved" 8 "Reserved" 7 "Reserved" 6 "Reserved" 5 "OTA mode" 4 "Collision mode (Reserved)" 3 "Transportation mode (Reserved)" 2 "Factory mode (Reserved)" 1 "Normal mode" 0 "Initial value" ;
VAL_ 1278 TBOX_OTAEnergyCtl 15 "Reserved" 14 "Reserved" 13 "Reserved" 12 "Reserved" 11 "Reserved" 10 "Reserved" 9 "Reserved" 8 "Reserved" 7 "Reserved" 6 "Reserved" 5 "Reserved" 4 "Reserved" 3 "Reserved" 2 "Power down request" 1 "Power on request" 0 "Inactive" ;
VAL_ 1576 TBOX_RMR 1 "Repeat Message State requested" 0 "Repeat Message State not requested" ;
VAL_ 1576 TBOX_AWB 1 "Node has woken up the network (active Wakeup)" 0 "Node has not woken up the network (passive wakeup)" ;
VAL_ 928 vsp_soundEnable 1 "ENABLE" 0 "DISABLE" ;
VAL_ 928 vsp_errorIdentification 1 "ERROR" 0 "NO_ERROR" ;
VAL_ 941 wcm_chargingSts 3 "FAULT" 2 "CHARGE_FINISHED" 1 "CHARGING" 0 "NO_CHARGE" ;
VAL_ 941 wcm_failureSts 7 "Reserved" 6 "Reserved" 5 "OverPower" 4 "FOREIGN_MATTER_DETECTED" 3 "HIGH_TEMP" 2 "HIGH_VOLT" 1 "LOW_VOLT" 0 "NORMAL" ;
VAL_ 941 wcm_workingSts 3 "INVALID" 2 "ON" 1 "OFF" 0 "INACTIVE" ;
VAL_ 941 wcm_reminder 1 "Warning" 0 "No warning" ;
VAL_ 1140 bms_obcChargeMode 3 "RESERVED" 2 "PAUSE_CHARGE" 1 "CONSTANT_CURRENT" 0 "CONSTANT_VOLTAGE" ;
VAL_ 1444 vcu_HVPTC_InternalWaterTemp2 255 "Invalid" ;
VAL_ 1445 vcu_HVPTC_HV_DC_curr 255 "Invalid" ;
VAL_ 1445 vcu_HVPTC_HV_voltage 255 "Invalid" ;
VAL_ 787 mcuf0_tempCltInlet 511 "Invalid" ;
VAL_ 787 mcuf0_hwDtcRecordFlag 1 "Flag" 0 "NO Flag" ;
VAL_ 787 mcuf0_pcbTemp 511 "Invalid" ;
VAL_ 786 mcur0_tempCltInlet 511 "Invalid" ;
VAL_ 786 mcur0_hwDtcRecordFlag 1 "Flag" 0 "NO Flag" ;
VAL_ 786 mcur0_pcbTemp 511 "Invalid" ;
